VERSION "HNNBNNNYNNNNNNNNNNNNNNNNNNNNNNNNNNNNNNNNNN/4/%%%/4/'%**4NNN///"

NS_ :

BS_ :

BU_:  Airbag BAP_Tester ICAS1_Gateway ICAS1_KommunikationsServer LE1 LE2 Motor_BEV Schaltbetaetigung

BO_ 299 GRA_ACC_01: 8 ICAS1_Gateway
 SG_ GRA_ACC_01_CRC  : 0|8@1+ (1.000000,0.000000) [0.000000|255.000000] "" Motor_BEV
 SG_ GRA_ACC_01_BZ  : 8|4@1+ (1.000000,0.000000) [0.000000|15.000000] "" Motor_BEV
 SG_ GRA_Hauptschalter  : 12|1@1+ (1.000000,0.000000) [0.000000|1.000000] "" Motor_BEV
 SG_ GRA_Abbrechen  : 13|1@1+ (1.000000,0.000000) [0.000000|1.000000] "" Motor_BEV
 SG_ GRA_Typ_Hauptschalter  : 14|1@1+ (1.000000,0.000000) [0.000000|1.000000] "" Motor_BEV
 SG_ GRA_Limiter  : 15|1@1+ (1.000000,0.000000) [0.000000|1.000000] "" Motor_BEV
 SG_ GRA_Tip_Setzen  : 16|1@1+ (1.000000,0.000000) [0.000000|1.000000] "" Motor_BEV
 SG_ GRA_Tip_Hoch  : 17|1@1+ (1.000000,0.000000) [0.000000|1.000000] "" Motor_BEV
 SG_ GRA_Tip_Runter  : 18|1@1+ (1.000000,0.000000) [0.000000|1.000000] "" Motor_BEV
 SG_ GRA_Tip_Wiederaufnahme  : 19|1@1+ (1.000000,0.000000) [0.000000|1.000000] "" Motor_BEV
 SG_ GRA_Verstellung_Zeitluecke  : 20|2@1+ (1.000000,0.000000) [0.000000|3.000000] "" Vector__XXX
 SG_ GRA_Codierung  : 22|2@1+ (1.000000,0.000000) [0.000000|3.000000] "" Motor_BEV
 SG_ GRA_Fehler  : 24|1@1+ (1.000000,0.000000) [0.000000|1.000000] "" Motor_BEV
 SG_ GRA_LIM_Taste_verfuegbar  : 25|1@1+ (1.000000,0.000000) [0.000000|1.000000] "" Motor_BEV
 SG_ GRA_Tip_Stufe_2  : 26|1@1+ (1.000000,0.000000) [0.000000|1.000000] "" Motor_BEV
 SG_ GRA_Typ_Bedienteil  : 27|3@1+ (1.000000,0.000000) [0.000000|7.000000] "" Motor_BEV
 SG_ GRA_TravelAssist  : 30|1@1+ (1.000000,0.000000) [0.000000|1.000000] "" Vector__XXX
 SG_ GRA_reserveByte4  : 31|1@1+ (1.000000,0.000000) [0.000000|1.000000] "" Vector__XXX
 SG_ GRA_reserveByte5  : 32|8@1+ (1.000000,0.000000) [0.000000|255.000000] "" Vector__XXX
 SG_ GRA_reserveByte6  : 40|8@1+ (1.000000,0.000000) [0.000000|255.000000] "" Vector__XXX
 SG_ GRA_reserveByte7  : 48|8@1+ (1.000000,0.000000) [0.000000|255.000000] "" Vector__XXX
 SG_ GRA_reserveByte8  : 56|8@1+ (1.000000,0.000000) [0.000000|255.000000] "" Vector__XXX

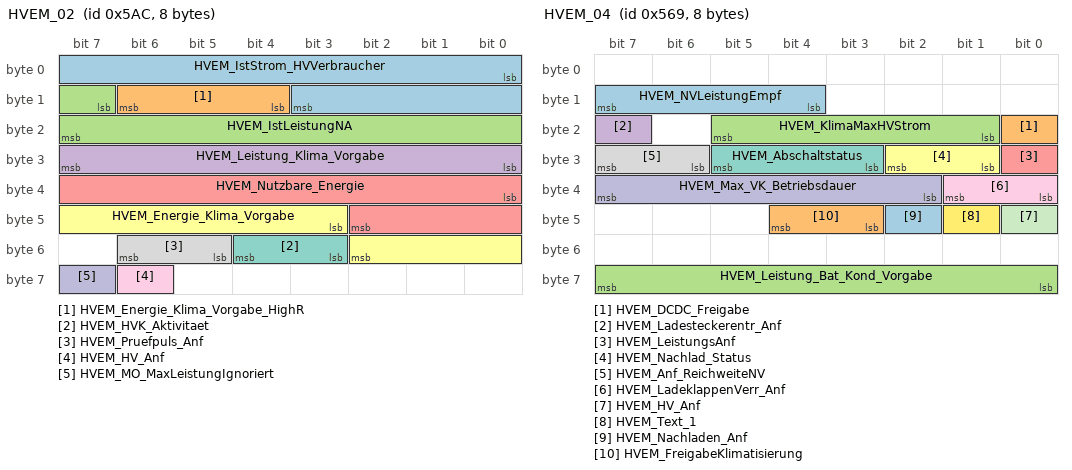
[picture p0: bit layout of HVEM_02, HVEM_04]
BO_ 1452 HVEM_02: 8 ICAS1_Gateway
 SG_ HVEM_IstStrom_HVVerbraucher  : 0|12@1+ (0.100000,-204.700000) [-204.700000|204.600000] "Unit_Amper" Vector__XXX
 SG_ HVEM_Energie_Klima_Vorgabe_HighR  : 12|3@1+ (10.000000,0.000000) [0.000000|50.000000] "Unit_WattHour" Vector__XXX
 SG_ HVEM_IstLeistungNA  : 15|9@1+ (50.000000,0.000000) [0.000000|25450.000000] "Unit_Watt" Motor_BEV
 SG_ HVEM_Leistung_Klima_Vorgabe  : 24|8@1+ (50.000000,0.000000) [0.000000|12650.000000] "Unit_Watt" Vector__XXX
 SG_ HVEM_Nutzbare_Energie  : 32|11@1+ (50.000000,0.000000) [0.000000|102200.000000] "Unit_WattHour" Vector__XXX
 SG_ HVEM_Energie_Klima_Vorgabe  : 43|8@1+ (50.000000,0.000000) [0.000000|12650.000000] "Unit_WattHour" Vector__XXX
 SG_ HVEM_HVK_Aktivitaet  : 51|2@1+ (1.000000,0.000000) [0.000000|3.000000] "" Motor_BEV
 SG_ HVEM_Pruefpuls_Anf  : 53|2@1+ (1.000000,0.000000) [0.000000|3.000000] "" Motor_BEV
 SG_ HVEM_HV_Anf  : 62|1@1+ (1.000000,0.000000) [0.000000|1.000000] "" Motor_BEV
 SG_ HVEM_MO_MaxLeistungIgnoriert  : 63|1@1+ (1.000000,0.000000) [0.000000|1.000000] "" Vector__XXX

BO_ 1385 HVEM_04: 8 ICAS1_Gateway
 SG_ HVEM_NVLeistungEmpf  : 12|4@1+ (100.000000,0.000000) [0.000000|1500.000000] "Unit_Watt" Vector__XXX
 SG_ HVEM_DCDC_Freigabe  : 16|1@1+ (1.000000,0.000000) [0.000000|1.000000] "" Motor_BEV
 SG_ HVEM_KlimaMaxHVStrom  : 17|5@1+ (1.000000,0.000000) [0.000000|31.000000] "Unit_Amper" Vector__XXX
 SG_ HVEM_Ladesteckerentr_Anf  : 23|1@1+ (1.000000,0.000000) [0.000000|1.000000] "" Vector__XXX
 SG_ HVEM_LeistungsAnf  : 24|1@1+ (1.000000,0.000000) [0.000000|1.000000] "" Vector__XXX
 SG_ HVEM_Nachlad_Status  : 25|2@1+ (1.000000,0.000000) [0.000000|3.000000] "" Vector__XXX
 SG_ HVEM_Abschaltstatus  : 27|3@1+ (1.000000,0.000000) [0.000000|7.000000] "" Vector__XXX
 SG_ HVEM_Anf_ReichweiteNV  : 30|2@1+ (1.000000,0.000000) [0.000000|3.000000] "" Vector__XXX
 SG_ HVEM_LadeklappenVerr_Anf  : 32|2@1+ (1.000000,0.000000) [0.000000|3.000000] "" Vector__XXX
 SG_ HVEM_Max_VK_Betriebsdauer  : 34|6@1+ (1.000000,0.000000) [0.000000|60.000000] "Unit_Minut" Vector__XXX
 SG_ HVEM_HV_Anf  : 40|1@1+ (1.000000,0.000000) [0.000000|1.000000] "" Vector__XXX
 SG_ HVEM_Text_1  : 41|1@1+ (1.000000,0.000000) [0.000000|1.000000] "" Vector__XXX
 SG_ HVEM_Nachladen_Anf  : 42|1@1+ (1.000000,0.000000) [0.000000|1.000000] "" Vector__XXX
 SG_ HVEM_FreigabeKlimatisierung  : 43|2@1+ (1.000000,0.000000) [0.000000|3.000000] "" Vector__XXX
 SG_ HVEM_Leistung_Bat_Kond_Vorgabe  : 56|8@1+ (50.000000,0.000000) [0.000000|12650.000000] "Unit_Watt" Vector__XXX

BO_ 1283 HVK_01: 8 Motor_BEV
 SG_ HVK_01_CRC  : 0|8@1+ (1.000000,0.000000) [0.000000|255.000000] "" ICAS1_Gateway LE1 LE2
 SG_ HVK_01_BZ  : 8|4@1+ (1.000000,0.000000) [0.000000|15.000000] "" ICAS1_Gateway LE1 LE2
 SG_ HVK_Istmodus_Anf  : 12|1@1+ (1.000000,0.000000) [0.000000|1.000000] "" ICAS1_Gateway
 SG_ HVK_TN1_Sollmodus  : 13|2@1+ (1.000000,0.000000) [0.000000|3.000000] "" ICAS1_Gateway
 SG_ HVK_Vorladung_aktiv  : 15|1@1+ (1.000000,0.000000) [0.000000|1.000000] "" ICAS1_Gateway
 SG_ HVK_BMS_Sollmodus  : 24|3@1+ (1.000000,0.000000) [0.000000|7.000000] "" ICAS1_Gateway
 SG_ HVK_DCDC_Sollmodus  : 27|3@1+ (1.000000,0.000000) [0.000000|7.000000] "" ICAS1_Gateway
 SG_ HVK_EKK_Sollmodus  : 30|3@1+ (1.000000,0.000000) [0.000000|7.000000] "" ICAS1_Gateway
 SG_ HVK_HVPTC_Sollmodus  : 33|3@1+ (1.000000,0.000000) [0.000000|7.000000] "" ICAS1_Gateway
 SG_ HVK_HVLM_Sollmodus  : 36|3@1+ (1.000000,0.000000) [0.000000|7.000000] "" ICAS1_Gateway
 SG_ HVK_HV_Netz_Warnungen  : 39|2@1+ (1.000000,0.000000) [0.000000|3.000000] "" ICAS1_Gateway ICAS1_KommunikationsServer
 SG_ HV_Bordnetz_aktiv  : 41|1@1+ (1.000000,0.000000) [0.000000|1.000000] "" ICAS1_Gateway LE1 LE2
 SG_ HV_Bordnetz_Fehler  : 42|1@1+ (1.000000,0.000000) [0.000000|1.000000] "" ICAS1_Gateway
 SG_ HVK_Gesamtst_Spgfreiheit  : 43|2@1+ (1.000000,0.000000) [0.000000|3.000000] "" ICAS1_Gateway ICAS1_KommunikationsServer
 SG_ HVK_AktiveEntladung_Anf  : 45|1@1+ (1.000000,0.000000) [0.000000|1.000000] "" ICAS1_Gateway LE1 LE2
 SG_ HVK_HVEM_Freigabe  : 46|2@1+ (1.000000,0.000000) [0.000000|3.000000] "" ICAS1_Gateway
 SG_ HVK_Notentladung_Anf  : 48|2@1+ (1.000000,0.000000) [0.000000|3.000000] "" ICAS1_Gateway LE1 LE2
 SG_ HVK_Iso_Messung_Start  : 50|3@1+ (1.000000,0.000000) [0.000000|7.000000] "" ICAS1_Gateway
 SG_ HVK_Ladebereit  : 53|3@1+ (1.000000,0.000000) [0.000000|7.000000] "" ICAS1_Gateway
 SG_ HVK_PPulsFreigabe  : 56|2@1+ (1.000000,0.000000) [0.000000|3.000000] "" ICAS1_Gateway

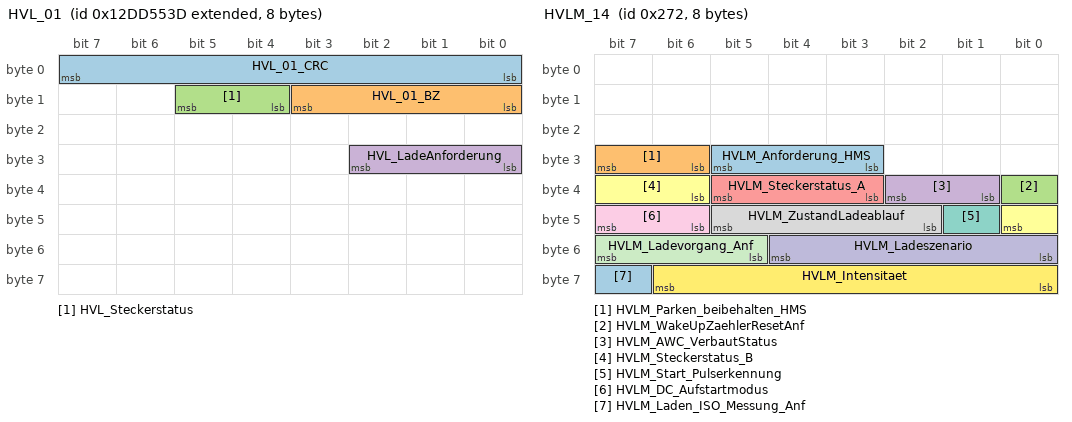
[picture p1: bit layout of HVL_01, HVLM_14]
BO_ 2463978813 HVL_01: 8 ICAS1_Gateway
 SG_ HVL_01_CRC  : 0|8@1+ (1.000000,0.000000) [0.000000|255.000000] "" Motor_BEV
 SG_ HVL_01_BZ  : 8|4@1+ (1.000000,0.000000) [0.000000|15.000000] "" Motor_BEV
 SG_ HVL_Steckerstatus  : 12|2@1+ (1.000000,0.000000) [0.000000|3.000000] "" Motor_BEV
 SG_ HVL_LadeAnforderung  : 24|3@1+ (1.000000,0.000000) [0.000000|7.000000] "" Motor_BEV

BO_ 626 HVLM_14: 8 ICAS1_Gateway
 SG_ HVLM_Anforderung_HMS  : 27|3@1+ (1.000000,0.000000) [0.000000|7.000000] "" Vector__XXX
 SG_ HVLM_Parken_beibehalten_HMS  : 30|2@1+ (1.000000,0.000000) [0.000000|3.000000] "" Vector__XXX
 SG_ HVLM_WakeUpZaehlerResetAnf  : 32|1@1+ (1.000000,0.000000) [0.000000|1.000000] "" Vector__XXX
 SG_ HVLM_AWC_VerbautStatus  : 33|2@1+ (1.000000,0.000000) [0.000000|3.000000] "" Motor_BEV
 SG_ HVLM_Steckerstatus_A  : 35|3@1+ (1.000000,0.000000) [0.000000|7.000000] "" Motor_BEV
 SG_ HVLM_Steckerstatus_B  : 38|3@1+ (1.000000,0.000000) [0.000000|7.000000] "" Vector__XXX
 SG_ HVLM_Start_Pulserkennung  : 41|1@1+ (1.000000,0.000000) [0.000000|1.000000] "" Vector__XXX
 SG_ HVLM_ZustandLadeablauf  : 42|4@1+ (1.000000,0.000000) [0.000000|15.000000] "" Motor_BEV
 SG_ HVLM_DC_Aufstartmodus  : 46|2@1+ (1.000000,0.000000) [0.000000|3.000000] "" Motor_BEV
 SG_ HVLM_Ladeszenario  : 48|5@1+ (1.000000,0.000000) [0.000000|31.000000] "" Vector__XXX
 SG_ HVLM_Ladevorgang_Anf  : 53|3@1+ (1.000000,0.000000) [0.000000|7.000000] "" Motor_BEV
 SG_ HVLM_Intensitaet  : 56|7@1+ (1.000000,0.000000) [0.000000|100.000000] "Unit_PerCent" Vector__XXX
 SG_ HVLM_Laden_ISO_Messung_Anf  : 63|1@1+ (1.000000,0.000000) [0.000000|1.000000] "" Motor_BEV

BO_ 268 IMMO_CORD_01: 8 Motor_BEV
 SG_ ImoCord_Auth_Aufforderung_WFS  : 63|1@1+ (1.000000,0.000000) [0.000000|1.000000] "" LE1 LE2

BO_ 23 IMMO_MSG3_Antwort: 8 ICAS1_Gateway
 SG_ WFS_IMMO_MSG3_CRC  : 0|32@1+ (1.000000,0.000000) [0.000000|4294967295.000000] "" LE2
 SG_ WFS_IMMO_MSG3_Status  : 56|8@1+ (1.000000,0.000000) [0.000000|255.000000] "" LE2

BO_ 25 IMMO_MSG4_Antwort: 8 ICAS1_Gateway
 SG_ WFS_IMMO_MSG4_CRC  : 0|32@1+ (1.000000,0.000000) [0.000000|4294967295.000000] "" LE1
 SG_ WFS_IMMO_MSG4_Status  : 56|8@1+ (1.000000,0.000000) [0.000000|255.000000] "" LE1

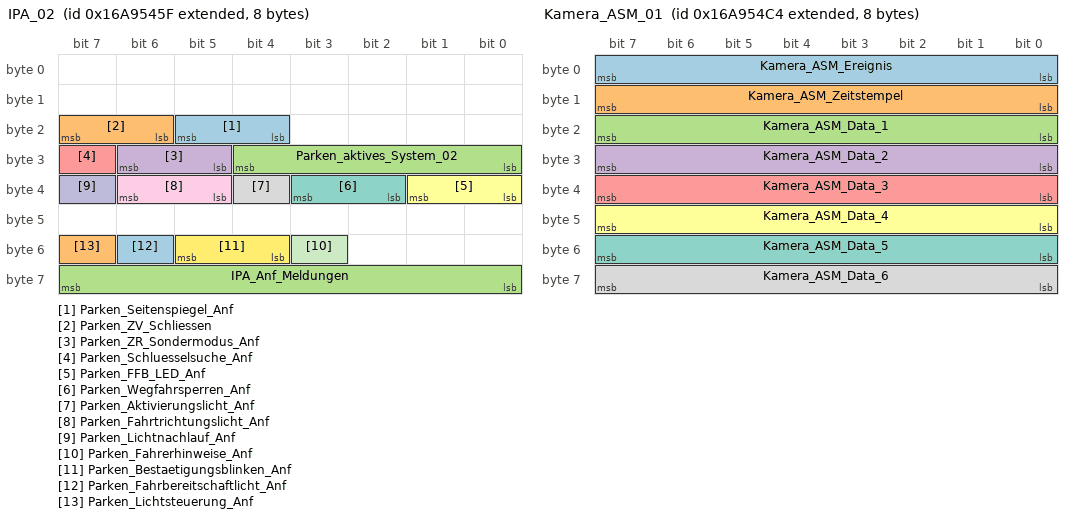
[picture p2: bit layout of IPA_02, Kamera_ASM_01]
BO_ 2527679583 IPA_02: 8 ICAS1_Gateway
 SG_ Parken_Seitenspiegel_Anf  : 20|2@1+ (1.000000,0.000000) [0.000000|3.000000] "" Vector__XXX
 SG_ Parken_ZV_Schliessen  : 22|2@1+ (1.000000,0.000000) [0.000000|3.000000] "" Vector__XXX
 SG_ Parken_aktives_System_02  : 24|5@1+ (1.000000,0.000000) [0.000000|31.000000] "" Vector__XXX
 SG_ Parken_ZR_Sondermodus_Anf  : 29|2@1+ (1.000000,0.000000) [0.000000|3.000000] "" Vector__XXX
 SG_ Parken_Schluesselsuche_Anf  : 31|1@1+ (1.000000,0.000000) [0.000000|1.000000] "" Vector__XXX
 SG_ Parken_FFB_LED_Anf  : 32|2@1+ (1.000000,0.000000) [0.000000|3.000000] "" Vector__XXX
 SG_ Parken_Wegfahrsperren_Anf  : 34|2@1+ (1.000000,0.000000) [0.000000|3.000000] "" LE1 LE2
 SG_ Parken_Aktivierungslicht_Anf  : 36|1@1+ (1.000000,0.000000) [0.000000|1.000000] "" Vector__XXX
 SG_ Parken_Fahrtrichtungslicht_Anf  : 37|2@1+ (1.000000,0.000000) [0.000000|3.000000] "" Vector__XXX
 SG_ Parken_Lichtnachlauf_Anf  : 39|1@1+ (1.000000,0.000000) [0.000000|1.000000] "" Vector__XXX
 SG_ Parken_Fahrerhinweise_Anf  : 51|1@1+ (1.000000,0.000000) [0.000000|1.000000] "" Vector__XXX
 SG_ Parken_Bestaetigungsblinken_Anf  : 52|2@1+ (1.000000,0.000000) [0.000000|3.000000] "" Vector__XXX
 SG_ Parken_Fahrbereitschaftlicht_Anf  : 54|1@1+ (1.000000,0.000000) [0.000000|1.000000] "" Vector__XXX
 SG_ Parken_Lichtsteuerung_Anf  : 55|1@1+ (1.000000,0.000000) [0.000000|1.000000] "" Vector__XXX
 SG_ IPA_Anf_Meldungen  : 56|8@1+ (1.000000,0.000000) [0.000000|255.000000] "" Vector__XXX

BO_ 1813 ISO_Airbag_01_Req: 8 ICAS1_Gateway
 SG_ ISO_Airbag_01_Req_Data  : 0|64@1+ (1.000000,0.000000) [0.000000|18446744073709551616.000000] "" Airbag

BO_ 1919 ISO_Airbag_01_Resp: 8 Airbag
 SG_ ISO_Airbag_01_Resp_Data  : 0|64@1+ (1.000000,0.000000) [0.000000|18446744073709551616.000000] "" ICAS1_Gateway

BO_ 1792 ISO_Funktionaler_Req_All: 8 ICAS1_Gateway
 SG_ ISO_ALL_01_Req_Data  : 0|64@1+ (1.000000,0.000000) [0.000000|18446744073709551616.000000] "" Airbag LE1 LE2 Motor_BEV

BO_ 2621440021 ISOx_Airbag_01_Req_FD: 64 ICAS1_Gateway
 SG_ ISOx_Airbag_01_Req_FD_Data  : 0|512@1+ (1.000000,0.000000) [0.000000|13407807929942597099574024998205846127479365820592393377723561443721764030073546976801874298166903427690031858186486050853753882811946569946433649006084096.000000] "" Airbag

BO_ 2621571093 ISOx_Airbag_01_Resp_FD: 64 Airbag
 SG_ ISOx_Airbag_01_Resp_FD_Data  : 0|512@1+ (1.000000,0.000000) [0.000000|13407807929942597099574024998205846127479365820592393377723561443721764030073546976801874298166903427690031858186486050853753882811946569946433649006084096.000000] "" ICAS1_Gateway

BO_ 2549874812 ISOx_EMotor_01_Req: 8 ICAS1_Gateway
 SG_ ISO_EMotor_01_Req_Data  : 0|64@1+ (1.000000,0.000000) [0.000000|18446744073709551616.000000] "" LE1

BO_ 2621440124 ISOx_EMotor_01_Req_FD: 64 ICAS1_Gateway
 SG_ ISOx_EMotor_01_Req_FD_Data  : 0|512@1+ (1.000000,0.000000) [0.000000|13407807929942597099574024998205846127479365820592393377723561443721764030073546976801874298166903427690031858186486050853753882811946569946433649006084096.000000] "" LE1

BO_ 2550005884 ISOx_EMotor_01_Resp: 8 LE1
 SG_ ISO_EMotor_01_Resp_Data  : 0|64@1+ (1.000000,0.000000) [0.000000|18446744073709551616.000000] "" ICAS1_Gateway

BO_ 2621571196 ISOx_EMotor_01_Resp_FD: 64 LE1
 SG_ ISOx_EMotor_01_Resp_FD_Data  : 0|512@1+ (1.000000,0.000000) [0.000000|13407807929942597099574024998205846127479365820592393377723561443721764030073546976801874298166903427690031858186486050853753882811946569946433649006084096.000000] "" ICAS1_Gateway

BO_ 2549874872 ISOx_EMotor_02_Req: 8 ICAS1_Gateway
 SG_ ISO_EMotor_02_Req_Data  : 0|64@1+ (1.000000,0.000000) [0.000000|18446744073709551616.000000] "" LE2

BO_ 2621440184 ISOx_EMotor_02_Req_FD: 64 ICAS1_Gateway
 SG_ ISOx_EMotor_02_Req_FD_Data  : 0|512@1+ (1.000000,0.000000) [0.000000|13407807929942597099574024998205846127479365820592393377723561443721764030073546976801874298166903427690031858186486050853753882811946569946433649006084096.000000] "" LE2

BO_ 2550005944 ISOx_EMotor_02_Resp: 8 LE2
 SG_ ISO_EMotor_02_Resp_Data  : 0|64@1+ (1.000000,0.000000) [0.000000|18446744073709551616.000000] "" ICAS1_Gateway

BO_ 2621571256 ISOx_EMotor_02_Resp_FD: 64 LE2
 SG_ ISOx_EMotor_02_Resp_FD_Data  : 0|512@1+ (1.000000,0.000000) [0.000000|13407807929942597099574024998205846127479365820592393377723561443721764030073546976801874298166903427690031858186486050853753882811946569946433649006084096.000000] "" ICAS1_Gateway

BO_ 2621505536 ISOx_Funkt_Req_All_FD: 64 ICAS1_Gateway
 SG_ ISOx_Funkt_Req_All_FD_Data  : 0|512@1+ (1.000000,0.000000) [0.000000|13407807929942597099574024998205846127479365820592393377723561443721764030073546976801874298166903427690031858186486050853753882811946569946433649006084096.000000] "" Airbag LE1 LE2 Motor_BEV

BO_ 2549874806 ISOx_MO_01_Req: 8 ICAS1_Gateway
 SG_ ISOx_MO_01_Req_Data  : 0|64@1+ (1.000000,0.000000) [0.000000|18446744073709551616.000000] "" Motor_BEV

BO_ 2621440118 ISOx_MO_01_Req_FD: 64 ICAS1_Gateway
 SG_ ISOx_MO_01_Req_FD_Data  : 0|512@1+ (1.000000,0.000000) [0.000000|13407807929942597099574024998205846127479365820592393377723561443721764030073546976801874298166903427690031858186486050853753882811946569946433649006084096.000000] "" Motor_BEV

BO_ 2550005878 ISOx_MO_01_Resp: 8 Motor_BEV
 SG_ ISOx_MO_01_Resp_Data  : 0|64@1+ (1.000000,0.000000) [0.000000|18446744073709551616.000000] "" ICAS1_Gateway

BO_ 2621571190 ISOx_MO_01_Resp_FD: 64 Motor_BEV
 SG_ ISOx_MO_01_Resp_FD_Data  : 0|512@1+ (1.000000,0.000000) [0.000000|13407807929942597099574024998205846127479365820592393377723561443721764030073546976801874298166903427690031858186486050853753882811946569946433649006084096.000000] "" ICAS1_Gateway

BO_ 2527679684 Kamera_ASM_01: 8 ICAS1_Gateway
 SG_ Kamera_ASM_Ereignis  : 0|8@1+ (1.000000,0.000000) [1.000000|254.000000] "" Airbag
 SG_ Kamera_ASM_Zeitstempel  : 8|8@1+ (0.080000,0.000000) [0.000000|20.320000] "Unit_Secon" Airbag
 SG_ Kamera_ASM_Data_1  : 16|8@1+ (1.000000,0.000000) [0.000000|255.000000] "" Airbag
 SG_ Kamera_ASM_Data_2  : 24|8@1+ (1.000000,0.000000) [0.000000|255.000000] "" Airbag
 SG_ Kamera_ASM_Data_3  : 32|8@1+ (1.000000,0.000000) [0.000000|255.000000] "" Airbag
 SG_ Kamera_ASM_Data_4  : 40|8@1+ (1.000000,0.000000) [0.000000|255.000000] "" Airbag
 SG_ Kamera_ASM_Data_5  : 48|8@1+ (1.000000,0.000000) [0.000000|255.000000] "" Airbag
 SG_ Kamera_ASM_Data_6  : 56|8@1+ (1.000000,0.000000) [0.000000|255.000000] "" Airbag

BO_ 960 Klemmen_Status_01: 4 ICAS1_Gateway
 SG_ Klemmen_Status_01_CRC  : 0|8@1+ (1.000000,0.000000) [0.000000|255.000000] "" Motor_BEV
 SG_ Klemmen_Status_01_BZ  : 8|4@1+ (1.000000,0.000000) [0.000000|15.000000] "" Motor_BEV
 SG_ RSt_Fahrerhinweise  : 12|4@1+ (1.000000,0.000000) [0.000000|15.000000] "" Vector__XXX
 SG_ ZAS_Kl_S  : 16|1@1+ (1.000000,0.000000) [0.000000|1.000000] "" Vector__XXX
 SG_ ZAS_Kl_15  : 17|1@1+ (1.000000,0.000000) [0.000000|1.000000] "" Airbag LE1 LE2 Motor_BEV Schaltbetaetigung
 SG_ ZAS_Kl_X  : 18|1@1+ (1.000000,0.000000) [0.000000|1.000000] "" Vector__XXX
 SG_ ZAS_Kl_50_Startanforderung  : 19|1@1+ (1.000000,0.000000) [0.000000|1.000000] "" Motor_BEV
 SG_ BCM_Remotestart_Betrieb  : 20|1@1+ (1.000000,0.000000) [0.000000|1.000000] "" Vector__XXX
 SG_ ZAS_Kl_Infotainment  : 21|1@1+ (1.000000,0.000000) [0.000000|1.000000] "" Vector__XXX
 SG_ BCM_Remotestart_KL15_Anf  : 22|1@1+ (1.000000,0.000000) [0.000000|1.000000] "" Vector__XXX
 SG_ BCM_Remotestart_MO_Start  : 23|1@1+ (1.000000,0.000000) [0.000000|1.000000] "" Vector__XXX
 SG_ KST_Warn_P1_ZST_def  : 24|1@1+ (1.000000,0.000000) [0.000000|1.000000] "" Vector__XXX
 SG_ KST_Warn_P2_ZST_def  : 25|1@1+ (1.000000,0.000000) [0.000000|1.000000] "" Vector__XXX
 SG_ KST_Fahrerhinweis_1  : 26|1@1+ (1.000000,0.000000) [0.000000|1.000000] "" Vector__XXX
 SG_ KST_Fahrerhinweis_2  : 27|1@1+ (1.000000,0.000000) [0.000000|1.000000] "" Vector__XXX
 SG_ BCM_Ausparken_Betrieb  : 28|1@1+ (1.000000,0.000000) [0.000000|1.000000] "" Vector__XXX
 SG_ KST_Fahrerhinweis_4  : 29|1@1+ (1.000000,0.000000) [0.000000|1.000000] "" Vector__XXX
 SG_ KST_Fahrerhinweis_5  : 30|1@1+ (1.000000,0.000000) [0.000000|1.000000] "" Vector__XXX
 SG_ KST_Fahrerhinweis_6  : 31|1@1+ (1.000000,0.000000) [0.000000|1.000000] "" Vector__XXX

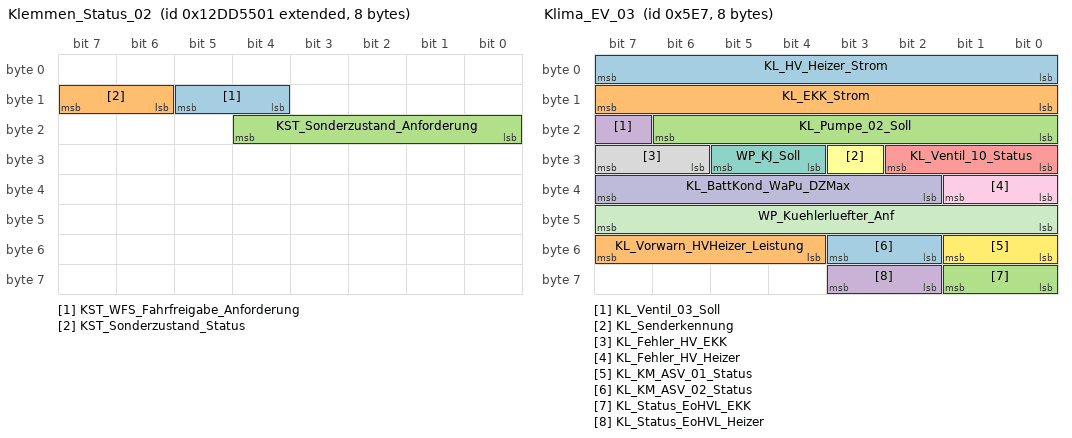
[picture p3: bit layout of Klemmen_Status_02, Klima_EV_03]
BO_ 2463978753 Klemmen_Status_02: 8 ICAS1_Gateway
 SG_ KST_WFS_Fahrfreigabe_Anforderung  : 12|2@1+ (1.000000,0.000000) [0.000000|3.000000] "" LE1 LE2
 SG_ KST_Sonderzustand_Status  : 14|2@1+ (1.000000,0.000000) [0.000000|3.000000] "" LE1 LE2
 SG_ KST_Sonderzustand_Anforderung  : 16|5@1+ (1.000000,0.000000) [0.000000|31.000000] "" LE1 LE2

BO_ 1420 Klemmen_Steuerung_01: 8 ICAS1_Gateway
 SG_ Klemmen_Steuerung_01_CRC  : 0|8@1+ (1.000000,0.000000) [0.000000|255.000000] "" Vector__XXX
 SG_ Klemmen_Steuerung_01_BZ  : 8|4@1+ (1.000000,0.000000) [0.000000|15.000000] "" Vector__XXX
 SG_ KST_Anf_Klemme_15  : 12|1@1+ (1.000000,0.000000) [0.000000|1.000000] "" Vector__XXX
 SG_ KST_Anf_Klemme_50  : 13|1@1+ (1.000000,0.000000) [0.000000|1.000000] "" Motor_BEV
 SG_ KST_Anf_Klemme_S  : 14|1@1+ (1.000000,0.000000) [0.000000|1.000000] "" Vector__XXX
 SG_ KST_Txt_Werkstatt  : 15|1@1+ (1.000000,0.000000) [0.000000|1.000000] "" Vector__XXX
 SG_ KST_Txt_P_Gang  : 16|1@1+ (1.000000,0.000000) [0.000000|1.000000] "" Vector__XXX
 SG_ KST_Txt_Panikabschaltung  : 17|1@1+ (1.000000,0.000000) [0.000000|1.000000] "" Vector__XXX
 SG_ KST_Anf_Klemmenfreigabe_ELV  : 18|1@1+ (1.000000,0.000000) [0.000000|1.000000] "" Vector__XXX
 SG_ KST_Txt_Komfortabschaltung  : 19|1@1+ (1.000000,0.000000) [0.000000|1.000000] "" Vector__XXX
 SG_ KST_ZAT_betaetigt  : 20|1@1+ (1.000000,0.000000) [0.000000|1.000000] "" Vector__XXX
 SG_ KST_Unterdr_Zuendungsmeldung  : 21|1@1+ (1.000000,0.000000) [0.000000|1.000000] "" Vector__XXX
 SG_ KST_aut_Abschaltung_Zuendung  : 22|1@1+ (1.000000,0.000000) [0.000000|1.000000] "" Vector__XXX
 SG_ KST_Anf_Klemmenfreigabe_WFS  : 23|1@1+ (1.000000,0.000000) [0.000000|1.000000] "" Vector__XXX
 SG_ KST_Anf_ZV_Verriegelung  : 24|1@1+ (1.000000,0.000000) [0.000000|1.000000] "" Vector__XXX
 SG_ Relais_VoKo_angesteuert  : 25|1@1+ (1.000000,0.000000) [0.000000|1.000000] "" Vector__XXX
 SG_ RSt_Anforderung_HMS  : 26|3@1+ (1.000000,0.000000) [0.000000|7.000000] "" Vector__XXX
 SG_ KST_Zuendungswarnung  : 29|2@1+ (1.000000,0.000000) [0.000000|3.000000] "" Vector__XXX
 SG_ KST_Fahrer_Info_Text  : 31|3@1+ (1.000000,0.000000) [0.000000|7.000000] "" Vector__XXX

BO_ 949 Klima_11: 8 ICAS1_Gateway
 SG_ KL_Drehz_Anh  : 0|1@1+ (1.000000,0.000000) [0.000000|1.000000] "" Vector__XXX
 SG_ KL_Vorwarn_Komp_ein  : 1|1@1+ (1.000000,0.000000) [0.000000|1.000000] "" Vector__XXX
 SG_ KL_AC_Schalter  : 2|1@1+ (1.000000,0.000000) [0.000000|1.000000] "" Vector__XXX
 SG_ KL_Komp_Moment_alt  : 3|1@1+ (1.000000,0.000000) [0.000000|1.000000] "" Vector__XXX
 SG_ KL_Vorwarn_Zuheizer_ein  : 6|1@1+ (1.000000,0.000000) [0.000000|1.000000] "" Vector__XXX
 SG_ KL_Zustand  : 7|1@1+ (1.000000,0.000000) [0.000000|1.000000] "" Vector__XXX
 SG_ KL_Kompressorkupplung_linear  : 8|8@1+ (20.000000,0.000000) [0.000000|4000.000000] "Unit_MilliAmper" Vector__XXX
 SG_ KL_Charisma_FahrPr  : 16|4@1+ (1.000000,0.000000) [0.000000|15.000000] "" Vector__XXX
 SG_ KL_Charisma_Status  : 20|2@1+ (1.000000,0.000000) [0.000000|3.000000] "" Vector__XXX
 SG_ KL_nachtr_Stopp_Anf  : 22|1@1+ (1.000000,0.000000) [0.000000|1.000000] "" Vector__XXX
 SG_ KL_T_Charge  : 23|1@1+ (1.000000,0.000000) [0.000000|1.000000] "" Vector__XXX
 SG_ KL_Last_Kompr  : 24|8@1+ (0.250000,0.000000) [0.000000|63.500000] "Unit_NewtoMeter" Vector__XXX
 SG_ KL_Spannungs_Anf  : 32|2@1+ (1.000000,0.000000) [0.000000|3.000000] "" Vector__XXX
 SG_ KL_Thermomanagement  : 34|2@1+ (1.000000,0.000000) [0.000000|3.000000] "" Motor_BEV
 SG_ KL_StartStopp_Info  : 36|2@1+ (1.000000,0.000000) [0.000000|3.000000] "" Vector__XXX
 SG_ KL_Freilauf_Info  : 38|2@1+ (1.000000,0.000000) [0.000000|3.000000] "" Vector__XXX
 SG_ KL_Anf_KL  : 40|8@1+ (0.400000,0.000000) [0.000000|101.600000] "Unit_PerCent" Motor_BEV
 SG_ KL_el_Zuheizer_Stufe  : 48|3@1+ (1.000000,0.000000) [0.000000|7.000000] "" Vector__XXX
 SG_ KL_Ausstattung_Klima  : 51|3@1+ (1.000000,0.000000) [0.000000|7.000000] "" Vector__XXX
 SG_ KL_Variante_Standheizung  : 54|2@1+ (1.000000,0.000000) [0.000000|3.000000] "" Vector__XXX
 SG_ KL_Anf_KV  : 57|7@1+ (1.000000,0.000000) [0.000000|100.000000] "Unit_PerCent" Motor_BEV

BO_ 1511 Klima_EV_03: 8 ICAS1_Gateway
 SG_ KL_HV_Heizer_Strom  : 0|8@1+ (0.250000,0.000000) [0.000000|63.500000] "Unit_Amper" Motor_BEV
 SG_ KL_EKK_Strom  : 8|8@1+ (0.250000,0.000000) [0.000000|63.500000] "Unit_Amper" Motor_BEV
 SG_ KL_Pumpe_02_Soll  : 16|7@1+ (1.000000,0.000000) [0.000000|100.000000] "Unit_PerCent" Motor_BEV
 SG_ KL_Ventil_03_Soll  : 23|1@1+ (1.000000,0.000000) [0.000000|1.000000] "" Vector__XXX
 SG_ KL_Ventil_10_Status  : 24|3@1+ (1.000000,0.000000) [0.000000|7.000000] "" Vector__XXX
 SG_ KL_Senderkennung  : 27|1@1+ (1.000000,0.000000) [0.000000|1.000000] "" Vector__XXX
 SG_ WP_KJ_Soll  : 28|2@1+ (1.000000,0.000000) [0.000000|3.000000] "" Vector__XXX
 SG_ KL_Fehler_HV_EKK  : 30|2@1+ (1.000000,0.000000) [0.000000|3.000000] "" Vector__XXX
 SG_ KL_Fehler_HV_Heizer  : 32|2@1+ (1.000000,0.000000) [0.000000|3.000000] "" Vector__XXX
 SG_ KL_BattKond_WaPu_DZMax  : 34|6@1+ (2.000000,0.000000) [0.000000|100.000000] "Unit_PerCent" Vector__XXX
 SG_ WP_Kuehlerluefter_Anf  : 40|8@1+ (0.400000,0.000000) [0.000000|101.600000] "Unit_PerCent" Vector__XXX
 SG_ KL_KM_ASV_01_Status  : 48|2@1+ (1.000000,0.000000) [0.000000|3.000000] "" Vector__XXX
 SG_ KL_KM_ASV_02_Status  : 50|2@1+ (1.000000,0.000000) [0.000000|3.000000] "" Vector__XXX
 SG_ KL_Vorwarn_HVHeizer_Leistung  : 52|4@1+ (1.000000,0.000000) [0.000000|15.000000] "" Vector__XXX
 SG_ KL_Status_EoHVL_EKK  : 56|2@1+ (1.000000,0.000000) [0.000000|3.000000] "" Motor_BEV
 SG_ KL_Status_EoHVL_Heizer  : 58|2@1+ (1.000000,0.000000) [0.000000|3.000000] "" Motor_BEV

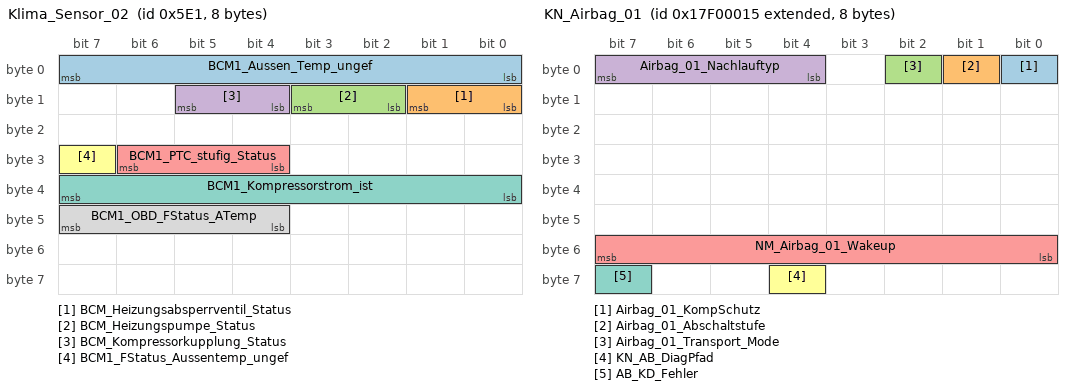
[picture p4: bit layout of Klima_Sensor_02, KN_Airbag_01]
BO_ 1505 Klima_Sensor_02: 8 ICAS1_Gateway
 SG_ BCM1_Aussen_Temp_ungef  : 0|8@1+ (0.500000,-50.000000) [-50.000000|76.000000] "Unit_DegreCelsi" LE1 LE2 Motor_BEV
 SG_ BCM_Heizungsabsperrventil_Status  : 8|2@1+ (1.000000,0.000000) [0.000000|3.000000] "" Vector__XXX
 SG_ BCM_Heizungspumpe_Status  : 10|2@1+ (1.000000,0.000000) [0.000000|3.000000] "" Vector__XXX
 SG_ BCM_Kompressorkupplung_Status  : 12|2@1+ (1.000000,0.000000) [0.000000|3.000000] "" Vector__XXX
 SG_ BCM1_PTC_stufig_Status  : 28|3@1+ (1.000000,0.000000) [0.000000|7.000000] "" Vector__XXX
 SG_ BCM1_FStatus_Aussentemp_ungef  : 31|1@1+ (1.000000,0.000000) [0.000000|1.000000] "" Vector__XXX
 SG_ BCM1_Kompressorstrom_ist  : 32|8@1+ (4.000000,0.000000) [0.000000|1000.000000] "Unit_MilliAmper" Vector__XXX
 SG_ BCM1_OBD_FStatus_ATemp  : 44|4@1+ (1.000000,0.000000) [0.000000|15.000000] "" Vector__XXX

BO_ 2549088277 KN_Airbag_01: 8 Airbag
 SG_ Airbag_01_KompSchutz  : 0|1@1+ (1.000000,0.000000) [0.000000|1.000000] "" Vector__XXX
 SG_ Airbag_01_Abschaltstufe  : 1|1@1+ (1.000000,0.000000) [0.000000|1.000000] "" Vector__XXX
 SG_ Airbag_01_Transport_Mode  : 2|1@1+ (1.000000,0.000000) [0.000000|1.000000] "" Vector__XXX
 SG_ Airbag_01_Nachlauftyp  : 4|4@1+ (1.000000,0.000000) [0.000000|15.000000] "" ICAS1_Gateway
 SG_ NM_Airbag_01_Wakeup  : 48|8@1+ (1.000000,0.000000) [0.000000|255.000000] "" Vector__XXX
 SG_ KN_AB_DiagPfad  : 60|1@1+ (1.000000,0.000000) [0.000000|1.000000] "" ICAS1_Gateway
 SG_ AB_KD_Fehler  : 63|1@1+ (1.000000,0.000000) [0.000000|1.000000] "" ICAS1_Gateway

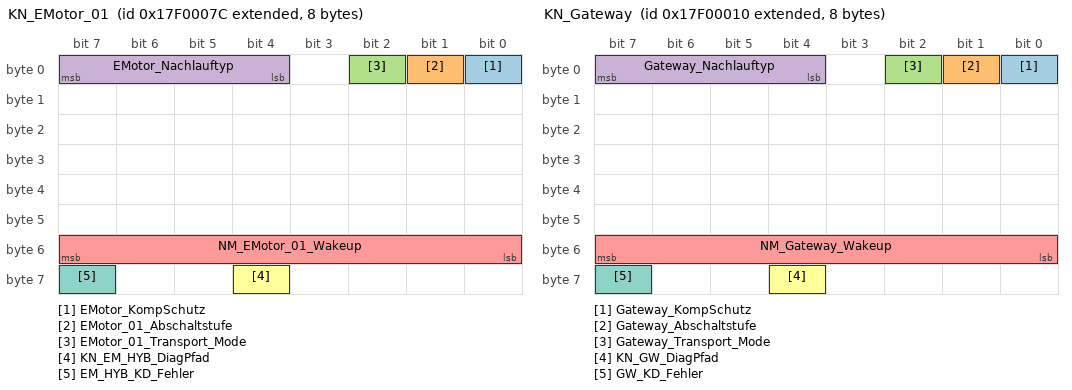
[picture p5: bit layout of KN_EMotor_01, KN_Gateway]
BO_ 2549088380 KN_EMotor_01: 8 LE1
 SG_ EMotor_KompSchutz  : 0|1@1+ (1.000000,0.000000) [0.000000|1.000000] "" Vector__XXX
 SG_ EMotor_01_Abschaltstufe  : 1|1@1+ (1.000000,0.000000) [0.000000|1.000000] "" Vector__XXX
 SG_ EMotor_01_Transport_Mode  : 2|1@1+ (1.000000,0.000000) [0.000000|1.000000] "" Vector__XXX
 SG_ EMotor_Nachlauftyp  : 4|4@1+ (1.000000,0.000000) [0.000000|15.000000] "" ICAS1_Gateway
 SG_ NM_EMotor_01_Wakeup  : 48|8@1+ (1.000000,0.000000) [0.000000|255.000000] "" Vector__XXX
 SG_ KN_EM_HYB_DiagPfad  : 60|1@1+ (1.000000,0.000000) [0.000000|1.000000] "" ICAS1_Gateway
 SG_ EM_HYB_KD_Fehler  : 63|1@1+ (1.000000,0.000000) [0.000000|1.000000] "" ICAS1_Gateway

BO_ 2549088272 KN_Gateway: 8 ICAS1_Gateway
 SG_ Gateway_KompSchutz  : 0|1@1+ (1.000000,0.000000) [0.000000|1.000000] "" Vector__XXX
 SG_ Gateway_Abschaltstufe  : 1|1@1+ (1.000000,0.000000) [0.000000|1.000000] "" Vector__XXX
 SG_ Gateway_Transport_Mode  : 2|1@1+ (1.000000,0.000000) [0.000000|1.000000] "" Vector__XXX
 SG_ Gateway_Nachlauftyp  : 4|4@1+ (1.000000,0.000000) [0.000000|15.000000] "" Vector__XXX
 SG_ NM_Gateway_Wakeup  : 48|8@1+ (1.000000,0.000000) [0.000000|255.000000] "" Vector__XXX
 SG_ KN_GW_DiagPfad  : 60|1@1+ (1.000000,0.000000) [0.000000|1.000000] "" Vector__XXX
 SG_ GW_KD_Fehler  : 63|1@1+ (1.000000,0.000000) [0.000000|1.000000] "" Vector__XXX

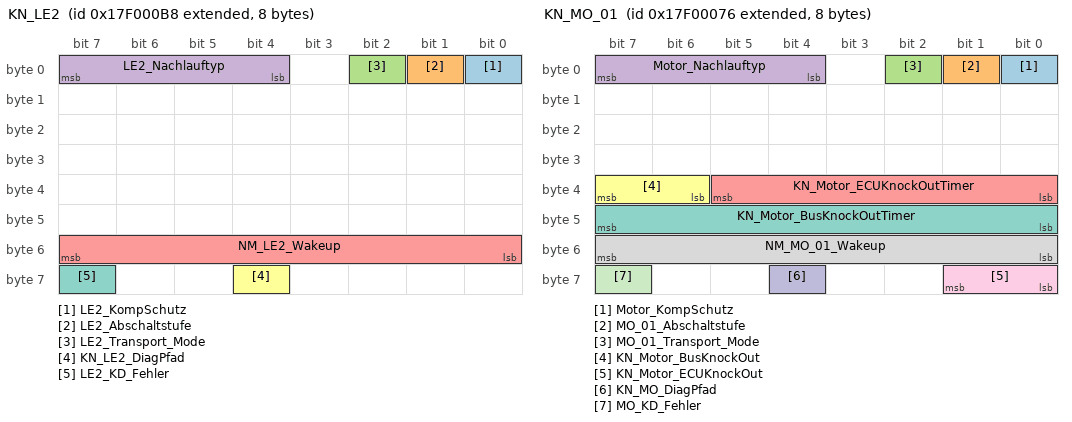
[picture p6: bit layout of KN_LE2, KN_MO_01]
BO_ 2549088440 KN_LE2: 8 LE2
 SG_ LE2_KompSchutz  : 0|1@1+ (1.000000,0.000000) [0.000000|1.000000] "" Vector__XXX
 SG_ LE2_Abschaltstufe  : 1|1@1+ (1.000000,0.000000) [0.000000|1.000000] "" Vector__XXX
 SG_ LE2_Transport_Mode  : 2|1@1+ (1.000000,0.000000) [0.000000|1.000000] "" Vector__XXX
 SG_ LE2_Nachlauftyp  : 4|4@1+ (1.000000,0.000000) [0.000000|15.000000] "" ICAS1_Gateway
 SG_ NM_LE2_Wakeup  : 48|8@1+ (1.000000,0.000000) [0.000000|255.000000] "" Vector__XXX
 SG_ KN_LE2_DiagPfad  : 60|1@1+ (1.000000,0.000000) [0.000000|1.000000] "" ICAS1_Gateway
 SG_ LE2_KD_Fehler  : 63|1@1+ (1.000000,0.000000) [0.000000|1.000000] "" ICAS1_Gateway

BO_ 2549088374 KN_MO_01: 8 Motor_BEV
 SG_ Motor_KompSchutz  : 0|1@1+ (1.000000,0.000000) [0.000000|1.000000] "" Vector__XXX
 SG_ MO_01_Abschaltstufe  : 1|1@1+ (1.000000,0.000000) [0.000000|1.000000] "" Vector__XXX
 SG_ MO_01_Transport_Mode  : 2|1@1+ (1.000000,0.000000) [0.000000|1.000000] "" Vector__XXX
 SG_ Motor_Nachlauftyp  : 4|4@1+ (1.000000,0.000000) [0.000000|15.000000] "" ICAS1_Gateway
 SG_ KN_Motor_ECUKnockOutTimer  : 32|6@1+ (1.000000,0.000000) [0.000000|62.000000] "Unit_Minut" Vector__XXX
 SG_ KN_Motor_BusKnockOut  : 38|2@1+ (1.000000,0.000000) [0.000000|3.000000] "" Vector__XXX
 SG_ KN_Motor_BusKnockOutTimer  : 40|8@1+ (1.000000,0.000000) [0.000000|254.000000] "" Vector__XXX
 SG_ NM_MO_01_Wakeup  : 48|8@1+ (1.000000,0.000000) [0.000000|255.000000] "" Vector__XXX
 SG_ KN_Motor_ECUKnockOut  : 56|2@1+ (1.000000,0.000000) [0.000000|3.000000] "" Vector__XXX
 SG_ KN_MO_DiagPfad  : 60|1@1+ (1.000000,0.000000) [0.000000|1.000000] "" ICAS1_Gateway
 SG_ MO_KD_Fehler  : 63|1@1+ (1.000000,0.000000) [0.000000|1.000000] "" ICAS1_Gateway

BO_ 2621440277 KS_Airbag_01_Req_FD: 16 ICAS1_Gateway
 SG_ KS_Airbag_01_Req_FD_Data  : 0|128@1+ (1.000000,0.000000) [0.000000|340282366920938463463374607431768211456.000000] "" Airbag

BO_ 2621571349 KS_Airbag_01_Resp_FD: 16 Airbag
 SG_ KS_Airbag_01_Resp_FD_Data  : 0|128@1+ (1.000000,0.000000) [0.000000|340282366920938463463374607431768211456.000000] "" ICAS1_Gateway

BO_ 982 Licht_hinten_01: 8 ICAS1_Gateway
 SG_ Licht_hinten_01_BZ  : 0|4@1+ (1.000000,0.000000) [0.000000|15.000000] "" Vector__XXX
 SG_ LH_Aussenlicht_def  : 7|1@1+ (1.000000,0.000000) [0.000000|1.000000] "" Vector__XXX
 SG_ LH_Standlicht_H_aktiv  : 8|1@1+ (1.000000,0.000000) [0.000000|1.000000] "" Vector__XXX
 SG_ LH_Parklicht_HL_aktiv  : 9|1@1+ (1.000000,0.000000) [0.000000|1.000000] "" Vector__XXX
 SG_ LH_Parklicht_HR_aktiv  : 10|1@1+ (1.000000,0.000000) [0.000000|1.000000] "" Vector__XXX
 SG_ LH_Bremslicht_H_aktiv  : 11|1@1+ (1.000000,0.000000) [0.000000|1.000000] "" Vector__XXX
 SG_ LH_Nebelschluss_aktiv  : 12|1@1+ (1.000000,0.000000) [0.000000|1.000000] "" Vector__XXX
 SG_ LH_Rueckfahrlicht_aktiv  : 13|1@1+ (1.000000,0.000000) [0.000000|1.000000] "" Vector__XXX
 SG_ LH_Blinker_HL_akt  : 14|1@1+ (1.000000,0.000000) [0.000000|1.000000] "" Vector__XXX
 SG_ LH_Blinker_HR_akt  : 15|1@1+ (1.000000,0.000000) [0.000000|1.000000] "" Vector__XXX
 SG_ LH_Blinker_li_def  : 16|1@1+ (1.000000,0.000000) [0.000000|1.000000] "" Vector__XXX
 SG_ LH_Bremsl_li_def  : 17|1@1+ (1.000000,0.000000) [0.000000|1.000000] "" Vector__XXX
 SG_ LH_Schlusslicht_li_def  : 18|1@1+ (1.000000,0.000000) [0.000000|1.000000] "" Vector__XXX
 SG_ LH_Rueckf_li_def  : 19|1@1+ (1.000000,0.000000) [0.000000|1.000000] "" Vector__XXX
 SG_ LH_Nebel_li_def  : 20|1@1+ (1.000000,0.000000) [0.000000|1.000000] "" Vector__XXX
 SG_ LH_Schluss_Brems_Nebel_li_def  : 21|1@1+ (1.000000,0.000000) [0.000000|1.000000] "" Vector__XXX
 SG_ LH_Schluss_Brems_Nebel_re_def  : 22|1@1+ (1.000000,0.000000) [0.000000|1.000000] "" Vector__XXX
 SG_ LH_Zusatzschlussl_def  : 23|1@1+ (1.000000,0.000000) [0.000000|1.000000] "" Vector__XXX
 SG_ LH_Schluss_Brems_li_def  : 24|1@1+ (1.000000,0.000000) [0.000000|1.000000] "" Vector__XXX
 SG_ LH_Schluss_Nebel_li_def  : 25|1@1+ (1.000000,0.000000) [0.000000|1.000000] "" Vector__XXX
 SG_ LH_SL_BRL_BLK_li_def  : 26|1@1+ (1.000000,0.000000) [0.000000|1.000000] "" Vector__XXX
 SG_ LH_Brems_Blk_li_def  : 27|1@1+ (1.000000,0.000000) [0.000000|1.000000] "" Vector__XXX
 SG_ LH_Diag_Status_re_def  : 28|1@1+ (1.000000,0.000000) [0.000000|1.000000] "" Vector__XXX
 SG_ LH_Diag_Status_li_def  : 29|1@1+ (1.000000,0.000000) [0.000000|1.000000] "" Vector__XXX
 SG_ LH_Diag_LED_li_def  : 30|1@1+ (1.000000,0.000000) [0.000000|1.000000] "" Vector__XXX
 SG_ LH_Diag_LED_re_def  : 31|1@1+ (1.000000,0.000000) [0.000000|1.000000] "" Vector__XXX
 SG_ LH_Blinker_re_def  : 32|1@1+ (1.000000,0.000000) [0.000000|1.000000] "" Vector__XXX
 SG_ LH_Bremsl_re_def  : 33|1@1+ (1.000000,0.000000) [0.000000|1.000000] "" Vector__XXX
 SG_ LH_Schlusslicht_re_def  : 34|1@1+ (1.000000,0.000000) [0.000000|1.000000] "" Vector__XXX
 SG_ LH_Rueckf_re_def  : 35|1@1+ (1.000000,0.000000) [0.000000|1.000000] "" Vector__XXX
 SG_ LH_Nebel_re_def  : 36|1@1+ (1.000000,0.000000) [0.000000|1.000000] "" Vector__XXX
 SG_ LH_Schluss_Brems_mi_def  : 37|1@1+ (1.000000,0.000000) [0.000000|1.000000] "" Vector__XXX
 SG_ LH_Schluss_Brems_re_def  : 40|1@1+ (1.000000,0.000000) [0.000000|1.000000] "" Vector__XXX
 SG_ LH_Schluss_Nebel_re_def  : 41|1@1+ (1.000000,0.000000) [0.000000|1.000000] "" Vector__XXX
 SG_ LH_SL_BRL_BLK_re_def  : 42|1@1+ (1.000000,0.000000) [0.000000|1.000000] "" Vector__XXX
 SG_ LH_Brems_Blk_re_def  : 43|1@1+ (1.000000,0.000000) [0.000000|1.000000] "" Vector__XXX
 SG_ LH_Kennzl_def  : 48|1@1+ (1.000000,0.000000) [0.000000|1.000000] "" Vector__XXX
 SG_ LH_3_Bremsl_def  : 49|1@1+ (1.000000,0.000000) [0.000000|1.000000] "" Motor_BEV
 SG_ LH_Nebel_mi_def  : 50|1@1+ (1.000000,0.000000) [0.000000|1.000000] "" Vector__XXX
 SG_ LH_Rueckf_mi_def  : 51|1@1+ (1.000000,0.000000) [0.000000|1.000000] "" Vector__XXX
 SG_ LH_Schlusslicht_mi_def  : 52|1@1+ (1.000000,0.000000) [0.000000|1.000000] "" Vector__XXX
 SG_ LH_Bremsl_li_ges_def  : 54|1@1+ (1.000000,0.000000) [0.000000|1.000000] "" Motor_BEV
 SG_ LH_Bremsl_re_ges_def  : 55|1@1+ (1.000000,0.000000) [0.000000|1.000000] "" Motor_BEV
 SG_ LH_Bremsl_mi_def  : 61|1@1+ (1.000000,0.000000) [0.000000|1.000000] "" Vector__XXX
 SG_ BRL_als_SHL  : 62|1@1+ (1.000000,0.000000) [0.000000|1.000000] "" Vector__XXX

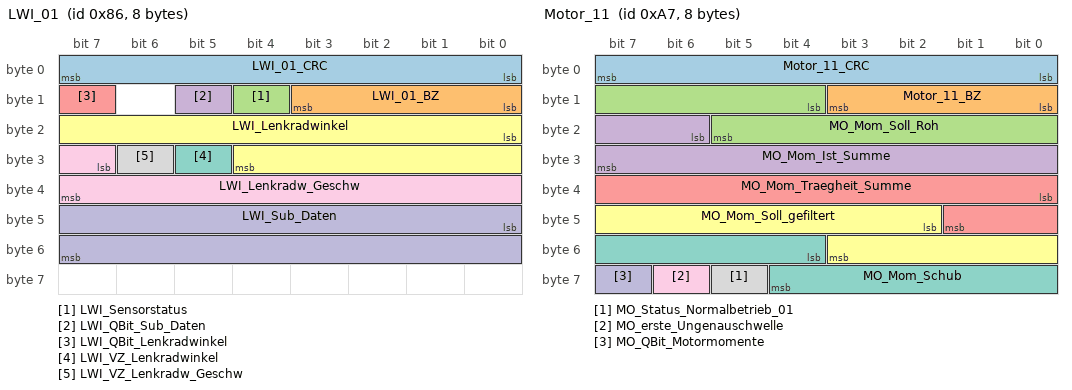
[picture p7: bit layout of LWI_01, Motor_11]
BO_ 134 LWI_01: 8 ICAS1_Gateway
 SG_ LWI_01_CRC  : 0|8@1+ (1.000000,0.000000) [0.000000|255.000000] "" Airbag Motor_BEV
 SG_ LWI_01_BZ  : 8|4@1+ (1.000000,0.000000) [0.000000|15.000000] "" Airbag Motor_BEV
 SG_ LWI_Sensorstatus  : 12|1@1+ (1.000000,0.000000) [0.000000|1.000000] "" Airbag Motor_BEV
 SG_ LWI_QBit_Sub_Daten  : 13|1@1+ (1.000000,0.000000) [0.000000|1.000000] "" Vector__XXX
 SG_ LWI_QBit_Lenkradwinkel  : 15|1@1+ (1.000000,0.000000) [0.000000|1.000000] "" Airbag Motor_BEV
 SG_ LWI_Lenkradwinkel  : 16|13@1+ (0.100000,0.000000) [0.000000|800.000000] "Unit_DegreOfArc" Airbag Motor_BEV
 SG_ LWI_VZ_Lenkradwinkel  : 29|1@1+ (1.000000,0.000000) [0.000000|1.000000] "" Airbag Motor_BEV
 SG_ LWI_VZ_Lenkradw_Geschw  : 30|1@1+ (1.000000,0.000000) [0.000000|1.000000] "" Vector__XXX
 SG_ LWI_Lenkradw_Geschw  : 31|9@1+ (5.000000,0.000000) [0.000000|2500.000000] "Unit_DegreOfArcPerSecon" Airbag
 SG_ LWI_Sub_Daten  : 40|16@1+ (1.000000,0.000000) [0.000000|65535.000000] "" Vector__XXX

BO_ 817 MFL_01: 8 ICAS1_Gateway
 SG_ MFL_Zaehler  : 0|4@1+ (1.000000,0.000000) [0.000000|15.000000] "" Vector__XXX
 SG_ MFL_Toggle  : 4|1@1+ (1.000000,0.000000) [0.000000|1.000000] "" Vector__XXX
 SG_ MFL_Lokalaktiv  : 5|1@1+ (1.000000,0.000000) [0.000000|1.000000] "" Vector__XXX
 SG_ MFL_M_Taste  : 6|1@1+ (1.000000,0.000000) [0.000000|1.000000] "" Vector__XXX
 SG_ MFL_Paddle_Verbau  : 7|1@1+ (1.000000,0.000000) [0.000000|1.000000] "" Vector__XXX
 SG_ MFL_Tastencode_1  : 8|8@1+ (1.000000,0.000000) [0.000000|255.000000] "" Vector__XXX
 SG_ MFL_Tastencode_2  : 16|8@1+ (1.000000,0.000000) [0.000000|255.000000] "" Vector__XXX
 SG_ MFL_Eventcode_1  : 24|4@1+ (1.000000,0.000000) [0.000000|15.000000] "" Vector__XXX
 SG_ MFL_Eventcode_2  : 28|4@1+ (1.000000,0.000000) [0.000000|15.000000] "" Vector__XXX
 SG_ MFL_Marke  : 32|4@1+ (1.000000,0.000000) [0.000000|15.000000] "" Vector__XXX
 SG_ MFL_Variante  : 36|4@1+ (1.000000,0.000000) [0.000000|15.000000] "" Vector__XXX
 SG_ MFL_Dummy_0_Signal_1  : 40|8@1+ (1.000000,0.000000) [0.000000|255.000000] "" Vector__XXX
 SG_ MFL_Tip_Down  : 48|1@1+ (1.000000,0.000000) [0.000000|1.000000] "" Motor_BEV
 SG_ MFL_Tip_Up  : 49|1@1+ (1.000000,0.000000) [0.000000|1.000000] "" Motor_BEV
 SG_ MFL_SatModul_links_Err  : 50|1@1+ (1.000000,0.000000) [0.000000|1.000000] "" Vector__XXX
 SG_ MFL_SatModul_rechts_Err  : 51|1@1+ (1.000000,0.000000) [0.000000|1.000000] "" Vector__XXX
 SG_ MFL_Dummy_0_Signal_2  : 52|1@1+ (1.000000,0.000000) [0.000000|1.000000] "" Vector__XXX
 SG_ MFL_Dummy_0_Signal_3  : 53|1@1+ (1.000000,0.000000) [0.000000|1.000000] "" Vector__XXX
 SG_ MFL_LR_HZG_Status  : 54|1@1+ (1.000000,0.000000) [0.000000|1.000000] "" Vector__XXX
 SG_ MFL_LR_HZG_Err  : 55|1@1+ (1.000000,0.000000) [0.000000|1.000000] "" Vector__XXX
 SG_ MFL_Signalhorn  : 56|1@1+ (1.000000,0.000000) [0.000000|1.000000] "" Vector__XXX
 SG_ MFL_Signalhorn_Err  : 57|1@1+ (1.000000,0.000000) [0.000000|1.000000] "" Vector__XXX
 SG_ MFL_Tip_links_Err  : 58|1@1+ (1.000000,0.000000) [0.000000|1.000000] "" Vector__XXX
 SG_ MFL_Tip_rechts_Err  : 59|1@1+ (1.000000,0.000000) [0.000000|1.000000] "" Vector__XXX
 SG_ MFL_Taste_links_Err  : 60|1@1+ (1.000000,0.000000) [0.000000|1.000000] "" Vector__XXX
 SG_ MFL_Taste_rechts_Err  : 61|1@1+ (1.000000,0.000000) [0.000000|1.000000] "" Vector__XXX
 SG_ MFL_ECU_Err  : 62|1@1+ (1.000000,0.000000) [0.000000|1.000000] "" Vector__XXX
 SG_ MFL_Response_Err  : 63|1@1+ (1.000000,0.000000) [0.000000|1.000000] "" Vector__XXX

BO_ 15 MO_SOPC: 1 Motor_BEV
 SG_ MO_SOPC  : 0|1@1+ (1.000000,0.000000) [0.000000|1.000000] "" Vector__XXX

BO_ 1600 Motor_07: 8 Motor_BEV
 SG_ MO_QBit_Ansaugluft_Temp  : 0|1@1+ (1.000000,0.000000) [0.000000|1.000000] "" Vector__XXX
 SG_ MO_QBit_Oel_Temp  : 1|1@1+ (1.000000,0.000000) [0.000000|1.000000] "" Vector__XXX
 SG_ MO_QBit_Kuehlmittel_Temp  : 2|1@1+ (1.000000,0.000000) [0.000000|1.000000] "" Vector__XXX
 SG_ MO_KL15_Abschaltempfehlung  : 3|1@1+ (1.000000,0.000000) [0.000000|1.000000] "" Vector__XXX
 SG_ MO_HYB_Fehler_HV_Netz  : 4|1@1+ (1.000000,0.000000) [0.000000|1.000000] "" Vector__XXX
 SG_ MO_aktives_Getriebeheizen  : 5|1@1+ (1.000000,0.000000) [0.000000|1.000000] "" Vector__XXX
 SG_ MO_Absperrventil_oeffnen  : 6|2@1+ (1.000000,0.000000) [0.000000|3.000000] "" Vector__XXX
 SG_ MO_Ansaugluft_Temp  : 8|8@1+ (0.750000,-48.000000) [-48.000000|141.750000] "Unit_DegreCelsi" Vector__XXX
 SG_ MO_Oel_Temp  : 16|8@1+ (1.000000,-60.000000) [-60.000000|192.000000] "Unit_DegreCelsi" Vector__XXX
 SG_ MO_Kuehlmittel_Temp  : 24|8@1+ (0.750000,-48.000000) [-48.000000|141.750000] "Unit_DegreCelsi" Vector__XXX
 SG_ MO_Hoeheninfo  : 32|8@1+ (0.007810,0.000000) [0.000000|1.983740] "" Vector__XXX
 SG_ MO_Kennfeldk  : 40|1@1+ (1.000000,0.000000) [0.000000|1.000000] "" Vector__XXX
 SG_ MO_Versionsinfo_02  : 41|5@1+ (1.000000,0.000000) [0.000000|31.000000] "" Vector__XXX
 SG_ MO_QBit_Hoeheninfo  : 46|1@1+ (1.000000,0.000000) [0.000000|1.000000] "" Vector__XXX
 SG_ MO_Getriebe_kuehlen  : 47|1@1+ (1.000000,0.000000) [0.000000|1.000000] "" Vector__XXX
 SG_ MO_Mom_Traegheit_02  : 48|5@1+ (0.010000,0.000000) [0.000000|0.310000] "Unit_KiloGramMeterSquar" Vector__XXX
 SG_ MO_Heizungspumpenansteuerung  : 53|4@1+ (10.000000,0.000000) [0.000000|100.000000] "Unit_PerCent" Vector__XXX
 SG_ MO_SpannungsAnf  : 57|1@1+ (1.000000,0.000000) [0.000000|1.000000] "" Vector__XXX
 SG_ MO_Nachlaufzeit_Heizungspumpe  : 58|6@1+ (15.000000,0.000000) [0.000000|945.000000] "Unit_Secon" Vector__XXX

BO_ 167 Motor_11: 8 Motor_BEV
 SG_ Motor_11_CRC  : 0|8@1+ (1.000000,0.000000) [0.000000|255.000000] "" ICAS1_Gateway
 SG_ Motor_11_BZ  : 8|4@1+ (1.000000,0.000000) [0.000000|15.000000] "" ICAS1_Gateway
 SG_ MO_Mom_Soll_Roh  : 12|10@1+ (1.000000,-509.000000) [-509.000000|509.000000] "" ICAS1_Gateway
 SG_ MO_Mom_Ist_Summe  : 22|10@1+ (1.000000,-509.000000) [-509.000000|509.000000] "" ICAS1_Gateway
 SG_ MO_Mom_Traegheit_Summe  : 32|10@1+ (1.000000,-509.000000) [-509.000000|509.000000] "" ICAS1_Gateway
 SG_ MO_Mom_Soll_gefiltert  : 42|10@1+ (1.000000,-509.000000) [-509.000000|509.000000] "" ICAS1_Gateway
 SG_ MO_Mom_Schub  : 52|9@1+ (1.000000,-509.000000) [-509.000000|0.000000] "" ICAS1_Gateway
 SG_ MO_Status_Normalbetrieb_01  : 61|1@1+ (1.000000,0.000000) [0.000000|1.000000] "" ICAS1_Gateway
 SG_ MO_erste_Ungenauschwelle  : 62|1@1+ (1.000000,0.000000) [0.000000|1.000000] "" ICAS1_Gateway
 SG_ MO_QBit_Motormomente  : 63|1@1+ (1.000000,0.000000) [0.000000|1.000000] "" ICAS1_Gateway

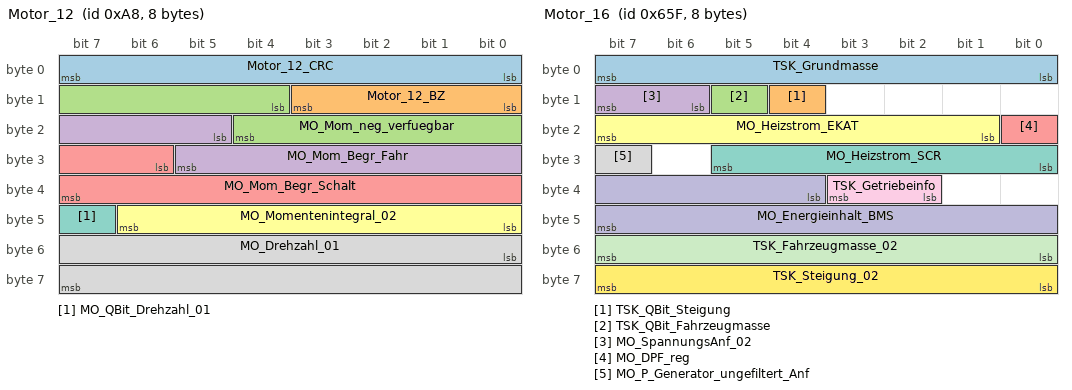
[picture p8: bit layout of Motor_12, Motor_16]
BO_ 168 Motor_12: 8 Motor_BEV
 SG_ Motor_12_CRC  : 0|8@1+ (1.000000,0.000000) [0.000000|255.000000] "" ICAS1_Gateway
 SG_ Motor_12_BZ  : 8|4@1+ (1.000000,0.000000) [0.000000|15.000000] "" ICAS1_Gateway
 SG_ MO_Mom_neg_verfuegbar  : 12|9@1+ (1.000000,-509.000000) [-509.000000|0.000000] "" ICAS1_Gateway
 SG_ MO_Mom_Begr_Fahr  : 21|9@1+ (1.000000,0.000000) [0.000000|509.000000] "" ICAS1_Gateway
 SG_ MO_Mom_Begr_Schalt  : 30|10@1+ (1.000000,-509.000000) [-509.000000|509.000000] "" ICAS1_Gateway
 SG_ MO_Momentenintegral_02  : 40|7@1+ (1.000000,0.000000) [0.000000|100.000000] "Unit_PerCent" ICAS1_Gateway
 SG_ MO_QBit_Drehzahl_01  : 47|1@1+ (1.000000,0.000000) [0.000000|1.000000] "" Airbag ICAS1_Gateway LE2
 SG_ MO_Drehzahl_01  : 48|16@1+ (0.250000,0.000000) [0.000000|16383.000000] "Unit_MinutInver" ICAS1_Gateway

BO_ 958 Motor_14: 8 Motor_BEV
 SG_ Motor_14_CRC  : 0|8@1+ (1.000000,0.000000) [0.000000|255.000000] "" ICAS1_Gateway
 SG_ Motor_14_BZ  : 8|4@1+ (1.000000,0.000000) [0.000000|15.000000] "" ICAS1_Gateway
 SG_ MO_StartStopp_Status  : 12|2@1+ (1.000000,0.000000) [0.000000|3.000000] "" ICAS1_Gateway
 SG_ MO_StartStopp_Wiederstart  : 14|1@1+ (1.000000,0.000000) [0.000000|1.000000] "" ICAS1_Gateway
 SG_ MO_StartStopp_Motorstopp  : 15|1@1+ (1.000000,0.000000) [0.000000|1.000000] "" ICAS1_Gateway
 SG_ MO_Freig_Reku  : 16|2@1+ (1.000000,0.000000) [0.000000|3.000000] "" ICAS1_Gateway
 SG_ MO_Kl_75  : 18|1@1+ (1.000000,0.000000) [0.000000|1.000000] "" ICAS1_Gateway
 SG_ MO_Kl_50  : 19|1@1+ (1.000000,0.000000) [0.000000|1.000000] "" ICAS1_Gateway
 SG_ MO_Gangposition  : 20|4@1+ (1.000000,0.000000) [0.000000|15.000000] "" ICAS1_Gateway
 SG_ MO_StartStopp_Fahrerwunsch  : 24|2@1+ (1.000000,0.000000) [0.000000|3.000000] "" ICAS1_Gateway
 SG_ MO_HYB_Fahrbereitschaft  : 26|1@1+ (1.000000,0.000000) [0.000000|1.000000] "" ICAS1_Gateway
 SG_ MO_Ext_E_Fahrt_aktiv  : 27|1@1+ (1.000000,0.000000) [0.000000|1.000000] "" ICAS1_Gateway
 SG_ MO_Fahrer_bremst  : 28|1@1+ (1.000000,0.000000) [0.000000|1.000000] "" Airbag ICAS1_Gateway
 SG_ MO_QBit_Fahrer_bremst  : 29|1@1+ (1.000000,0.000000) [0.000000|1.000000] "" Airbag ICAS1_Gateway
 SG_ MO_BLS  : 30|1@1+ (1.000000,0.000000) [0.000000|1.000000] "" Airbag ICAS1_Gateway
 SG_ MO_Konsistenz_Bremsped  : 31|1@1+ (1.000000,0.000000) [0.000000|1.000000] "" ICAS1_Gateway
 SG_ MO_Timeout_ESP  : 32|1@1+ (1.000000,0.000000) [0.000000|1.000000] "" ICAS1_Gateway
 SG_ MO_Klima_Eingr  : 33|2@1+ (1.000000,0.000000) [0.000000|3.000000] "" ICAS1_Gateway
 SG_ MO_Aussp_Anlass  : 35|1@1+ (1.000000,0.000000) [0.000000|1.000000] "" ICAS1_Gateway
 SG_ MO_Freig_Anlass  : 36|1@1+ (1.000000,0.000000) [0.000000|1.000000] "" ICAS1_Gateway
 SG_ MO_Kuppl_schalter  : 37|1@1+ (1.000000,0.000000) [0.000000|1.000000] "" ICAS1_Gateway
 SG_ MO_Interlock  : 38|1@1+ (1.000000,0.000000) [0.000000|1.000000] "" ICAS1_Gateway
 SG_ MO_Motor_laeuft  : 39|1@1+ (1.000000,0.000000) [0.000000|1.000000] "" ICAS1_Gateway
 SG_ MO_Kickdown  : 40|1@1+ (1.000000,0.000000) [0.000000|1.000000] "" ICAS1_Gateway ICAS1_KommunikationsServer
 SG_ MO_QBit_KL_75  : 41|1@1+ (1.000000,0.000000) [0.000000|1.000000] "" ICAS1_Gateway
 SG_ MO_EKlKomLeiRed  : 42|2@1+ (1.000000,0.000000) [0.000000|3.000000] "" ICAS1_Gateway
 SG_ MO_Handshake_STH  : 44|1@1+ (1.000000,0.000000) [0.000000|1.000000] "" ICAS1_Gateway
 SG_ MO_BKV_Unterdruckwarnung  : 45|1@1+ (1.000000,0.000000) [0.000000|1.000000] "" ICAS1_Gateway
 SG_ MO_Freigabe_Segeln  : 46|1@1+ (1.000000,0.000000) [0.000000|1.000000] "" ICAS1_Gateway
 SG_ MO_PTC_Status  : 47|3@1+ (1.000000,0.000000) [0.000000|7.000000] "" ICAS1_Gateway
 SG_ MO_QBit_Gangposition  : 50|1@1+ (1.000000,0.000000) [0.000000|1.000000] "" ICAS1_Gateway
 SG_ MO_Signalquelle_Gangposition  : 51|1@1+ (1.000000,0.000000) [0.000000|1.000000] "" ICAS1_Gateway
 SG_ MO_Remotestart_Betrieb  : 52|1@1+ (1.000000,0.000000) [0.000000|1.000000] "" ICAS1_Gateway
 SG_ MO_Remotestart_moeglich  : 53|1@1+ (1.000000,0.000000) [0.000000|1.000000] "" ICAS1_Gateway
 SG_ MO_FMAus_aktiv  : 55|1@1+ (1.000000,0.000000) [0.000000|1.000000] "" ICAS1_Gateway
 SG_ MO_FMAus_Startvariante  : 56|2@1+ (1.000000,0.000000) [0.000000|3.000000] "" ICAS1_Gateway
 SG_ MO_BMS_NV_Anf_stuetzen  : 58|1@1+ (1.000000,0.000000) [0.000000|1.000000] "" ICAS1_Gateway
 SG_ MO_Zylinderabschaltung  : 59|2@1+ (1.000000,0.000000) [0.000000|3.000000] "" ICAS1_Gateway
 SG_ MO_HYB_VM_aktiv  : 61|1@1+ (1.000000,0.000000) [0.000000|1.000000] "" ICAS1_Gateway
 SG_ MO_StartVorauss_erfuellt  : 62|2@1+ (1.000000,0.000000) [0.000000|3.000000] "" ICAS1_Gateway

BO_ 1631 Motor_16: 8 Motor_BEV
 SG_ TSK_Grundmasse  : 0|8@1+ (32.000000,0.000000) [0.000000|8128.000000] "Unit_KiloGram" ICAS1_Gateway
 SG_ TSK_QBit_Steigung  : 12|1@1+ (1.000000,0.000000) [0.000000|1.000000] "" ICAS1_Gateway
 SG_ TSK_QBit_Fahrzeugmasse  : 13|1@1+ (1.000000,0.000000) [0.000000|1.000000] "" ICAS1_Gateway
 SG_ MO_SpannungsAnf_02  : 14|2@1+ (1.000000,0.000000) [0.000000|3.000000] "" ICAS1_Gateway
 SG_ MO_DPF_reg  : 16|1@1+ (1.000000,0.000000) [0.000000|1.000000] "" ICAS1_Gateway
 SG_ MO_Heizstrom_EKAT  : 17|7@1+ (1.000000,0.000000) [0.000000|126.000000] "Unit_Amper" ICAS1_Gateway
 SG_ MO_Heizstrom_SCR  : 24|6@1+ (1.000000,0.000000) [0.000000|62.000000] "Unit_Amper" ICAS1_Gateway
 SG_ MO_P_Generator_ungefiltert_Anf  : 31|1@1+ (1.000000,0.000000) [0.000000|1.000000] "" ICAS1_Gateway
 SG_ TSK_Getriebeinfo  : 34|2@1+ (1.000000,0.000000) [0.000000|3.000000] "" ICAS1_Gateway
 SG_ MO_Energieinhalt_BMS  : 36|12@1+ (25.000000,0.000000) [0.000000|102325.000000] "Unit_WattHour" ICAS1_Gateway
 SG_ TSK_Fahrzeugmasse_02  : 48|8@1+ (32.000000,0.000000) [0.000000|8128.000000] "Unit_KiloGram" ICAS1_Gateway
 SG_ TSK_Steigung_02  : 56|8@1+ (0.800000,-101.600000) [-100.800000|101.600000] "Unit_PerCent" ICAS1_Gateway

BO_ 1648 Motor_18: 8 Motor_BEV
 SG_ MO_max_Ladedruck  : 0|6@1+ (0.100000,0.000000) [0.000000|6.300000] "Unit_Bar" ICAS1_Gateway
 SG_ MO_ANC_Kennfeld_Anf  : 6|2@1+ (1.000000,0.000000) [0.000000|3.000000] "" ICAS1_Gateway
 SG_ MO_Bremslicht_Reku  : 8|1@1+ (1.000000,0.000000) [0.000000|1.000000] "" ICAS1_Gateway
 SG_ MO_StartStopp_PopUp  : 9|2@1+ (1.000000,0.000000) [0.000000|3.000000] "" ICAS1_Gateway
 SG_ MO1_Sperr_Info_WFS  : 11|1@1+ (1.000000,0.000000) [0.000000|1.000000] "" ICAS1_Gateway
 SG_ MO1_Freigabe_Info_WFS  : 12|1@1+ (1.000000,0.000000) [0.000000|1.000000] "" ICAS1_Gateway
 SG_ MO_EPCL  : 13|3@1+ (1.000000,0.000000) [0.000000|7.000000] "" ICAS1_Gateway ICAS1_KommunikationsServer
 SG_ MO_Zylabsch_Texte_02  : 16|4@1+ (1.000000,0.000000) [0.000000|15.000000] "" ICAS1_Gateway
 SG_ MO_Fahrzeugtyp  : 20|3@1+ (1.000000,0.000000) [0.000000|7.000000] "" ICAS1_Gateway ICAS1_KommunikationsServer
 SG_ MO_NMAX_Schaltanzeige  : 23|9@1+ (25.000000,0.000000) [0.000000|12775.000000] "Unit_MinutInver" ICAS1_Gateway
 SG_ MO_Abstellzeit  : 32|8@1+ (8.000000,0.000000) [0.000000|2024.000000] "Unit_Minut" ICAS1_Gateway
 SG_ MO_Abstellzeit_Status  : 40|2@1+ (1.000000,0.000000) [0.000000|3.000000] "" ICAS1_Gateway
 SG_ MO1_Freigabe_Verfallsinfo_WFS  : 42|1@1+ (1.000000,0.000000) [0.000000|1.000000] "" ICAS1_Gateway
 SG_ MO_Hybrid_StartStopp_LED  : 43|2@1+ (1.000000,0.000000) [0.000000|3.000000] "" ICAS1_Gateway
 SG_ MO_Fehler_Zylabsch  : 45|2@1+ (1.000000,0.000000) [0.000000|3.000000] "" ICAS1_Gateway
 SG_ MO_Anzahl_Abgesch_Zyl  : 47|3@1+ (1.000000,0.000000) [0.000000|7.000000] "" ICAS1_Gateway
 SG_ MO_Zylabsch_Texte  : 50|2@1+ (1.000000,0.000000) [0.000000|3.000000] "" ICAS1_Gateway
 SG_ MO_Ethanol_BS_Texte  : 52|3@1+ (1.000000,0.000000) [0.000000|7.000000] "" ICAS1_Gateway
 SG_ MO_Drehzahl_Warnung  : 55|1@1+ (1.000000,0.000000) [0.000000|1.000000] "" ICAS1_Gateway
 SG_ MO_obere_Drehzahlgrenze  : 56|8@1+ (50.000000,0.000000) [50.000000|12750.000000] "Unit_MinutInver" ICAS1_Gateway

BO_ 967 Motor_26: 8 Motor_BEV
 SG_ MO_Kuehlerluefter_MUX M : 0|1@1+ (1.000000,0.000000) [0.000000|1.000000] "siema ooo" ICAS1_Gateway
 SG_ MO_Kuehlerluefter_1 m0 : 1|7@1+ (1.000000,0.000000) [0.000000|100.000000] "Unit_PerCent" ICAS1_Gateway
 SG_ MO_Kuehlerluefter_2 m1 : 1|7@1+ (1.000000,0.000000) [0.000000|100.000000] "Unit_PerCent" ICAS1_Gateway
 SG_ MO_EFLEX_Lampe  : 8|2@1+ (1.000000,0.000000) [0.000000|3.000000] "" ICAS1_Gateway
 SG_ MO_KJS_nicht_bereit  : 10|1@1+ (1.000000,0.000000) [0.000000|1.000000] "" ICAS1_Gateway
 SG_ MO_ITM_Warnung_Pumpe  : 11|1@1+ (1.000000,0.000000) [0.000000|1.000000] "" ICAS1_Gateway
 SG_ WIV_Anzeige_aktiv  : 12|1@1+ (1.000000,0.000000) [0.000000|1.000000] "" ICAS1_Gateway
 SG_ WIV_Oelmin_Warn  : 13|1@1+ (1.000000,0.000000) [0.000000|1.000000] "" ICAS1_Gateway
 SG_ WIV_Sensorfehler  : 14|1@1+ (1.000000,0.000000) [0.000000|1.000000] "" ICAS1_Gateway
 SG_ WIV_Schieflage  : 15|1@1+ (1.000000,0.000000) [0.000000|1.000000] "" ICAS1_Gateway
 SG_ WIV_Oelstand  : 16|4@1+ (12.500000,0.000000) [0.000000|100.000000] "Unit_PerCent" ICAS1_Gateway
 SG_ MO_Zustand_HWP  : 20|2@1+ (1.000000,0.000000) [0.000000|3.000000] "" ICAS1_Gateway
 SG_ OLEV_Systemstoerung  : 22|1@1+ (1.000000,0.000000) [0.000000|1.000000] "" ICAS1_Gateway
 SG_ MO_Oelwarnung_max  : 23|1@1+ (1.000000,0.000000) [0.000000|1.000000] "" ICAS1_Gateway
 SG_ WIV_Oelsystem_aktiv  : 24|1@1+ (1.000000,0.000000) [0.000000|1.000000] "" ICAS1_Gateway
 SG_ WIV_nicht_betriebswarm  : 25|1@1+ (1.000000,0.000000) [0.000000|1.000000] "" ICAS1_Gateway
 SG_ WIV_Ueberfuell_Warn  : 26|1@1+ (1.000000,0.000000) [0.000000|1.000000] "" ICAS1_Gateway
 SG_ WIV_laufender_Motor  : 27|1@1+ (1.000000,0.000000) [0.000000|1.000000] "" ICAS1_Gateway
 SG_ MO_E_Warnungen  : 28|4@1+ (1.000000,0.000000) [0.000000|15.000000] "" ICAS1_Gateway
 SG_ MO_Text_Motorstart  : 32|4@1+ (1.000000,0.000000) [0.000000|15.000000] "" ICAS1_Gateway
 SG_ MO_E_Texte  : 36|4@1+ (1.000000,0.000000) [0.000000|15.000000] "" ICAS1_Gateway
 SG_ WIV_Oeldyn_avl  : 40|1@1+ (1.000000,0.000000) [0.000000|1.000000] "" ICAS1_Gateway
 SG_ MO_Text_Partikelfil_Reg  : 41|1@1+ (1.000000,0.000000) [0.000000|1.000000] "" ICAS1_Gateway
 SG_ OLEV_Oelstand_nicht_vorhanden  : 42|1@1+ (1.000000,0.000000) [0.000000|1.000000] "" ICAS1_Gateway
 SG_ WIV_Oelmenge  : 43|5@1+ (125.000000,0.000000) [0.000000|3875.000000] "Unit_MilliLiter" ICAS1_Gateway
 SG_ MO_Systemlampe  : 48|1@1+ (1.000000,0.000000) [0.000000|1.000000] "" ICAS1_Gateway
 SG_ MO_OBD2_Lampe  : 49|1@1+ (1.000000,0.000000) [0.000000|1.000000] "" ICAS1_Gateway
 SG_ MO_Heissleuchte  : 50|1@1+ (1.000000,0.000000) [0.000000|1.000000] "" ICAS1_Gateway
 SG_ MO_Partikel_Lampe  : 51|1@1+ (1.000000,0.000000) [0.000000|1.000000] "" ICAS1_Gateway
 SG_ MO_RedFahrleistung_Lampe  : 52|1@1+ (1.000000,0.000000) [0.000000|1.000000] "" ICAS1_Gateway ICAS1_KommunikationsServer
 SG_ WIV_Oelstand_nicht_vorhanden  : 53|1@1+ (1.000000,0.000000) [0.000000|1.000000] "" ICAS1_Gateway
 SG_ WIV_nachfuellanzeige_ein  : 54|1@1+ (1.000000,0.000000) [0.000000|1.000000] "" ICAS1_Gateway
 SG_ WIV_Ueberfuell_deaktiv  : 55|1@1+ (1.000000,0.000000) [0.000000|1.000000] "" ICAS1_Gateway
 SG_ WIV_Unterfuell_Warn  : 56|1@1+ (1.000000,0.000000) [0.000000|1.000000] "" ICAS1_Gateway
 SG_ MO_Tankdeckel_Lampe  : 57|1@1+ (1.000000,0.000000) [0.000000|1.000000] "" ICAS1_Gateway
 SG_ MO_Text_Tankdeckelwarn  : 58|1@1+ (1.000000,0.000000) [0.000000|1.000000] "" ICAS1_Gateway
 SG_ MO_Vorglueh_Lampe  : 59|1@1+ (1.000000,0.000000) [0.000000|1.000000] "" ICAS1_Gateway
 SG_ WIV_Oeldr_Warn_Motor  : 60|1@1+ (1.000000,0.000000) [0.000000|1.000000] "" ICAS1_Gateway
 SG_ MO_E_Mode  : 61|3@1+ (1.000000,0.000000) [0.000000|7.000000] "" ICAS1_Gateway

CM_ BO_ 2527679583 "ehemalsZFAS_01";
CM_ BO_ 2621505536 "VWAGDiagnosefunktionalerRequestaufCANFD";
CM_ BO_ 960 "MQB";
CM_ BO_ 949 "abMQB7.4";
CM_ BO_ 1505 "abMQB7.3";
CM_ BO_ 982 "MQB";
CM_ BO_ 134 "abMQBmitCRCinByte1";
CM_ BO_ 1600 "abMQBmitQBitHöheneinfoundMO_Versionsinfo_02";
CM_ BO_ 168 "Teil2neueMomentenschnittstelleMLB";
CM_ BO_ 1648 "Kombischnittstelle";
CM_ BO_ 967 "MQB-vorherMotor_06/Umbenennungwg.ID-Wechsel";
CM_ SG_ 299 GRA_ACC_01_CRC "FürMLB:
'Berechnung siehe Lastenheft 'Kommunikationsabsicherung für FlexRay und CAN''

Ab MQB und MLBevo:
'Berechnung siehe Lastenheft 'End-to-End Kommunikationsabsicherung''

Endwerte siehe Begleitdokument 'S-PDU Kennungsfolgen'";
CM_ SG_ 299 GRA_ACC_01_BZ "4bitBotschaftszaehler,wirdmitjederSendebotschaftinkrementiert";
CM_ SG_ 299 GRA_Hauptschalter "StellungdesGRA/ACC-Hauptschalters:
Bei gerastetem Hauptschalter:
0: Hauptschalter aus
1: Hauptschalter ein
Bei getastetem Hauptschalter:
0: Taster nicht betätigt
1: Taster betätigt";
CM_ SG_ 299 GRA_Abbrechen "GRA:ausmitspeichern
ACC : Soft aus";
CM_ SG_ 299 GRA_Typ_Hauptschalter "VariantedesGRA/ACC-Hauptschalters:
0: gerasteter Hauptschalter (bzw. Taster mit Speicherung des Status im SMLS (PAG))
1: getasteter Hauptschalter, keine Speicherung des Status im SMLS";
CM_ SG_ 299 GRA_Limiter "StellungdesLimiter-Tasters";
CM_ SG_ 299 GRA_Tip_Setzen "TippschalterSet";
CM_ SG_ 299 GRA_Tip_Hoch "TippschalterTipUp/Geschwindigkeiterhöhen";
CM_ SG_ 299 GRA_Tip_Runter "TippschalterTipDown/Geschwindigkeitreduzieren";
CM_ SG_ 299 GRA_Tip_Wiederaufnahme "TippschalterWiederaufnahme";
CM_ SG_ 299 GRA_Verstellung_Zeitluecke "VerstellungderZeitlückefürACC

DIST -1 = Zeitluecke um 1 Stufe kleiner
DIST +1 = Zeitluecke um 1 Stufe groeßer
DIST Toggle = Zeitlücke um 1 Stufe kleiner, von kleinster Stufe auf größte Stufe";
CM_ SG_ 299 GRA_Codierung "DasSignalzeigtan,obdasSende-SG(SMLS/MFL)aufGRA-oderACC-Bedienteilcodiertist:
0: kein GRA- oder ACC Bedienteil
1: GRA-Bedienteil
2: ACC-Bedienteil
3: Limiter_Only-Bedienteil";
CM_ SG_ 299 GRA_Fehler "DasSignalzeigtan,dassdasSende-SG(SMLS/MFG)einenDefektdesGRA-BedienteilserkannthatundhierzueinFSPEabgelegtwurde.";
CM_ SG_ 299 GRA_LIM_Taste_verfuegbar "DasSignalzeigtan,obeineLimiter-UmschalttasteamjeweiligenGRA/ACC-Bedienelementvorhandenist.";
CM_ SG_ 299 GRA_Tip_Stufe_2 "Signalzeigtan,dassderzweistufigeGRA/ACC-Hebel(8_Positions_Bedienteil)inder2.Tip-Stufebetätigtwird.DasSignalwirdnurgleichzeitigmitdemSignalGRA_Tip_HochoderGRA_Tip_Runtergesetzt,wobeidieBitsGRA_Tip_Hochbzw.GRA_Tip_RunterdieR";
CM_ SG_ 299 GRA_Typ_Bedienteil "DasSignalkennzeichnetdieVariantedesGRA/ACC-Bedienteils:
0: Init
1: 4-Positionen-Bedienteil (z.B. GRA im Blinkerhebel)
2: 6-Positionen-Bedienteil (GRA/ACC-Bedienteil mit separaten Stellungen für Set/Resume/TipUp/TipDown)
3: 8-Positionen-Bediente";
CM_ SG_ 299 GRA_TravelAssist "TastefürTravelAssist";
CM_ SG_ 299 GRA_reserveByte4 "Zweck:BefüllenderreserviertenBitpositionenmit0(wg.LIN-TeilnehmerMFL)";
CM_ SG_ 299 GRA_reserveByte5 "Zweck:BefüllenderreserviertenBitpositionenmit0(wg.LIN-TeilnehmerMFL)";
CM_ SG_ 299 GRA_reserveByte6 "Zweck:BefüllenderreserviertenBitpositionenmit0(wg.LIN-TeilnehmerMFL)";
CM_ SG_ 299 GRA_reserveByte7 "Zweck:BefüllenderreserviertenBitpositionenmit0(wg.LIN-TeilnehmerMFL)";
CM_ SG_ 299 GRA_reserveByte8 "Zweck:BefüllenderreserviertenBitpositionenmit0(wg.LIN-TeilnehmerMFL)";
CM_ SG_ 1452 HVEM_IstStrom_HVVerbraucher "IststromaufnahmederelektrischenNebenaggregateausdemHVZwischenkreis";
CM_ SG_ 1452 HVEM_Energie_Klima_Vorgabe_HighR "ErweiterteAuflösungvon10WhfürSignalHVEM_Energie_Klima_Vorgabe.
Signalwert wird zu HVEM_Energie_Klima_Vorgabe Addiert";
CM_ SG_ 1452 HVEM_IstLeistungNA "aktuelleLeistungsaufnahmederNebenaggregate";
CM_ SG_ 1452 HVEM_Leistung_Klima_Vorgabe "LeistungsvorgabeThermo(fürKühlenundHeizen)";
CM_ SG_ 1452 HVEM_Nutzbare_Energie "NutzbareEnergiewelchefürKomfortfunktionenvomHVEMfreigegebenwird.";
CM_ SG_ 1452 HVEM_Energie_Klima_Vorgabe "HVEM-EnergievorgabefürKlima-Vorkonditionierung";
CM_ SG_ 1452 HVEM_HVK_Aktivitaet "DemHVEMsindHV-Komponentenzugeordnet.DasHVEMübermitteltandenHVKein
Hochvolt –Aktivitätsstatus dieser HV-Komponenten.";
CM_ SG_ 1452 HVEM_Pruefpuls_Anf "PrüfpulsanforderungandenHV-Koordinator";
CM_ SG_ 1452 HVEM_HV_Anf "HVAnforderungdesHVEnergiemanagementsandasMSG";
CM_ SG_ 1452 HVEM_MO_MaxLeistungIgnoriert "RueckmeldungdesHVEMobdievorgegebeneMaxLeistungvomMSGeingehaltenwird.";
CM_ SG_ 1385 HVEM_NVLeistungEmpf "MaximalerSollwertderaktuellenLeistungderNV-SeitedesDCDC-Wandlers.";
CM_ SG_ 1385 HVEM_DCDC_Freigabe "FreigabedesDCDCwenndasFzgnichtFahrbereitist.";
CM_ SG_ 1385 HVEM_KlimaMaxHVStrom "KommuniziertdemKlimasteuergerätdenmax.Aufnahmestrom";
CM_ SG_ 1385 HVEM_Ladesteckerentr_Anf "AnforderungLadesteckerentriegelnnachZVAufBefehl";
CM_ SG_ 1385 HVEM_LeistungsAnf "AnforderunganNV-EMzurErhöhungderPerformancedenEnergieverbrauchaufderNV-Seitezureduzieren.";
CM_ SG_ 1385 HVEM_Nachlad_Status "StatusderUmsetzungderNachladeanforderungderNV-Seite.";
CM_ SG_ 1385 HVEM_Abschaltstatus "StatusderReduzierungsstufenderKlimakomponentenbeimLaden

0 = 100% (keine Reduzierung)
1 = 75%
2 = 50%
3 = 25%
7 = Init";
CM_ SG_ 1385 HVEM_Anf_ReichweiteNV "AnforderunganNV-EMzurErhöhungderReichweitedenEnergieverbrauchaufderNV-Seitezureduzieren.";
CM_ SG_ 1385 HVEM_LadeklappenVerr_Anf "AnforderungeinesVer-oderEntriegelnsderLadedosenklappeüberdieZV.";
CM_ SG_ 1385 HVEM_Max_VK_Betriebsdauer "BetriebslaufzeitderStandklimatisierung";
CM_ SG_ 1385 HVEM_HV_Anf "HVAnforderungdesHVEnergiemanagementsandasMSG";
CM_ SG_ 1385 HVEM_Text_1 "MeldungbeieinemAnzeigeSOC<10%('AchtungBatterieladen.Funktioneneingeschränkt')";
CM_ SG_ 1385 HVEM_Nachladen_Anf "AnforderungfürHVLadenbeigestecktemSteckerunddeaktivierterLadeanforderung";
CM_ SG_ 1385 HVEM_FreigabeKlimatisierung "Klimatisierungfreigeben";
CM_ SG_ 1385 HVEM_Leistung_Bat_Kond_Vorgabe "elektr.LeistungsvorgabeThermoBatterie";
CM_ SG_ 1283 HVK_01_CRC "FürMLB:
'Berechnung siehe Lastenheft 'Kommunikationsabsicherung für FlexRay und CAN''

Ab MQB und MLBevo:
'Berechnung siehe Lastenheft 'End-to-End Kommunikationsabsicherung''

Endwerte siehe Begleitdokument 'S-PDU Kennungsfolgen'";
CM_ SG_ 1283 HVK_Istmodus_Anf "HVK-AnforderunganalleHV-KomponentenderenIstmodusimschnellenZyklus(Inhibitzeit)zusenden.";
CM_ SG_ 1283 HVK_TN1_Sollmodus "AngeforderterSollmodusderSteuereinheitfürdasSchützedesTeilnetz1'Ladepfad':
0 : HV_Off
1 : HV_On (Schütz geschlossen)
2 : reserviert
3 : Init   (CAN-Initialisierung)";
CM_ SG_ 1283 HVK_Vorladung_aktiv "Systeminformation,dassaktivvorgeladenwird";
CM_ SG_ 1283 HVK_BMS_Sollmodus "AngeforderterSollmodusderHV-Batterie:
0 : HV_Off
1 : HV_On (HS geschlossen)
2 : nicht belegbar
3 : AC-Laden_erw (HS +AC_2-Schütze geschlossen)
4 : AC-";
CM_ SG_ 1283 HVK_DCDC_Sollmodus "angeforderteSoll-BetriebsartdesDC/DC-Wandlers:
0: Standby; Kommunikation aktiv
1: Zwischenkreis des HV-Netzes wird vorgeladen; HV-Netz wird aktiviert und darf nicht
belastet werden.
2: Tiefsetzen (HV --> BN 14,4V)
Sollwertvorgabe projek";
CM_ SG_ 1283 HVK_EKK_Sollmodus "SollmoduselektrischerKlimakompressor";
CM_ SG_ 1283 HVK_HVPTC_Sollmodus "SollmodusHV-PTC
0 : keine Freigabe
1 : Freigabe
2 : Freigabe_ausgesetzt
3 : nicht belegbar
4 : nicht belegbar
5 : nicht belegbar
6 : nicht belegbar
7 : Init   (CAN-Initialisierung)

Info: 'nicht belegbar' d.h. Sollmodus nicht relevant für HV";
CM_ SG_ 1283 HVK_HVLM_Sollmodus "AngeforderterSollmodusdesLademanagers.";
CM_ SG_ 1283 HVK_HV_Netz_Warnungen "AnforderungWarnung/FehlerHV-SystemimKombi
0: Keine Warnung/Init
1:Anforderung_Anzeige_Warnung_HV-Netz (gelbes Symbol)
2:Anforderung_Anzeige_Fehler_HV-Netz (rotes Symbol)
3:Anforderung_Anzeige_Warnung_Kein_Wiederstart_möglich";
CM_ SG_ 1283 HV_Bordnetz_aktiv "SignalisierteinaktivesHochvoltbordnetz.FürdieBelastbarkeitdesHV-NetzesmüssenStrom-bzw.Leistungsgrenzeneingehaltenwerden";
CM_ SG_ 1283 HV_Bordnetz_Fehler "StatusobimHV-NetzeinFehlerdetektiertwurde.";
CM_ SG_ 1283 HVK_Gesamtst_Spgfreiheit "StatusdesHV-Systems";
CM_ SG_ 1283 HVK_AktiveEntladung_Anf "AnforderungzumaktivenEntladendesHV-Netzes,währendderAbschaltungdesHV-Netz.";
CM_ SG_ 1283 HVK_HVEM_Freigabe "DerHVKgibtdasHVEMfrei,umdasHV-NetzunterEinhaltungvonLeistungsgrenzeninAnspruchzunehmen.";
CM_ SG_ 1283 HVK_Notentladung_Anf "AufforderungzurschnellstmöglichenEntladungdesHV-NetzesaufgrundHV-Sicherheit(Crash-Erkennung/AbrissPilotlinie/…).";
CM_ SG_ 1283 HVK_Iso_Messung_Start "AnforderungandieisolationswiderstandsüberwachendenHV-KomponentenzurDurchführungderIsolations-Widerstandsmessung.";
CM_ SG_ 1283 HVK_Ladebereit "InformationandasLademanagement,dassdasHV-SystemausSichtdesHVKsbereitgestelltwerdenkann.";
CM_ SG_ 1283 HVK_PPulsFreigabe "Prüfpuls-FreigabeseitensHochvoltkoordinator";
CM_ SG_ 2463978813 HVL_01_CRC "FürMLB:
Berechnung siehe Lastenheft 'Kommunikationsabsicherung für FlexRay und CAN'
Ab MQB und MLBevo:
Berechnung siehe Lastenheft 'End-to-End Kommunikationsabsicherung'

Endwerte siehe Begleitdokument 'S-PDU Kennungsfolgen'";
CM_ SG_ 2463978813 HVL_01_BZ "4bitBotschaftszähler,wirdmitjederSendebotschaftinkrementiert";
CM_ SG_ 2463978813 HVL_Steckerstatus "StelltdenStatusdesLadesteckershinsichtlichPräsenzzurVerfügung";
CM_ SG_ 2463978813 HVL_LadeAnforderung "FuSi-AbgesicherteLadeanforderungandenHVK";
CM_ SG_ 626 HVLM_Anforderung_HMS "AnforderungzurVerriegelungdesTriebstrangs";
CM_ SG_ 626 HVLM_Parken_beibehalten_HMS "AnforderungdenTriebstrangverriegeltzuhalten";
CM_ SG_ 626 HVLM_WakeUpZaehlerResetAnf "0=keine_Anforderung
1 = Reset_Zaehler";
CM_ SG_ 626 HVLM_AWC_VerbautStatus "VerbausignalisierungvomHVLMderoptionalenKomponenteAWC";
CM_ SG_ 626 HVLM_Steckerstatus_A "GibtdenSteckerstatusausderLadedoseAan";
CM_ SG_ 626 HVLM_Steckerstatus_B "GibtdenSteckerstatusausderLadedoseBan";
CM_ SG_ 626 HVLM_Start_Pulserkennung "StartanforderungfürdiePulserkennung";
CM_ SG_ 626 HVLM_ZustandLadeablauf "ZustandimAblaufdesLadevorganges
0 = Init
1 = Standby_Ladevorbedingungen erfuellt
2 = Standby_Ladevorbedingungen_nicht_erfuellt
3 = Fehler
4 = Laden_starten
5 = Laden_beenden
6 = HVBatterie_Laden
7 = HVBatterie_Entladen
8 = Erhaltungsladen";
CM_ SG_ 626 HVLM_DC_Aufstartmodus "AufstartmoduszumAktivierendesHV-ModusfürDC-Laden
0= keine_Anforderung
1= Angleich_Fahrzeug (Fahrzeug schaltet auf DC-Spannung der Ladesäule auf)
2= Angleich_LS_1 (Ladesäule schaltet auf DC-Spannung des Fahrzeuges auf Methode 1)
3= Angleich_LS_2 ";
CM_ SG_ 626 HVLM_Ladeszenario "ÜberdiesesSignalwirddaseinzustellendeSzenariofürdieVisualisierunggesendet.";
CM_ SG_ 626 HVLM_Ladevorgang_Anf "ArtderangefordertenLadeart
0 = Laden_nicht_angefordert
1 = AC_Laden_Angefordert
2 = DC_Laden_Angefordert
3 = AC_und_DC_Angefordert
4 = Induktiv_Laden_Angef
5 = AC_und_Induktiv_Angef
6 = DC_und_Induktiv_Angef
7 = AC_DC_und_Induktiv_Angef";
CM_ SG_ 626 HVLM_Intensitaet "ÜberdiesesSignalwirdeineInformationüberdieBeleuchtungsintensitätgesendet.";
CM_ SG_ 626 HVLM_Laden_ISO_Messung_Anf "MessungdesIsolationswiderstandesdesLadesystems(FzgundLadesäule)währenddesLadevorgangesdurchdasFahrzeug
0= Anforderung
1= keine_Anforderung";
CM_ SG_ 268 ImoCord_Auth_Aufforderung_WFS "WFS-Anforderung";
CM_ SG_ 2527679583 Parken_Seitenspiegel_Anf "AnforderungfürSeitenspiegelan-oderabklappenbeimPiloPa";
CM_ SG_ 2527679583 Parken_ZV_Schliessen "AnforderungfürZentralverriegelungverriegelnodersafenbeimPiloPa";
CM_ SG_ 2527679583 Parken_aktives_System_02 "zeigtanwelchesparkendesSystemaktivist";
CM_ SG_ 2527679583 Parken_ZR_Sondermodus_Anf "AnforderungSondermodus,umbeim„pilotiertenParken“spezielleFunktionsanpassungenimInfotainment-Bereichzuermöglichen(u.a.schnellererStartup,AbschaltungBT)";
CM_ SG_ 2527679583 Parken_Schluesselsuche_Anf "AnsteuerungderSchlüsselsuchefürdaspilotierteParken.";
CM_ SG_ 2527679583 Parken_FFB_LED_Anf "StatusinformationdesPilotiertenParkensfürdieAnsteuerungderLEDaufderFunkfernbedienung.";
CM_ SG_ 2527679583 Parken_Wegfahrsperren_Anf "AnsteuerungderWegfahrsperrenKomponentenfürdaspilotierteParken.";
CM_ SG_ 2527679583 Parken_Aktivierungslicht_Anf "AnforderungdesAktivierungslichtsnacherfolgreicherAktivierungshandlungseitensPilotiertemParken.";
CM_ SG_ 2527679583 Parken_Fahrtrichtungslicht_Anf "AnforderungseitensPilotiertemParkenfürdieAnzeigederinitialenFahrtrichtungnachSystemaktivierung.";
CM_ SG_ 2527679583 Parken_Lichtnachlauf_Anf "AnforderungdesLichtnachlaufsbeimBCM1(analogVerlassenskonzept)fürdasPilotierteParken.";
CM_ SG_ 2527679583 Parken_Fahrerhinweise_Anf "AnforderungzurerneutenLampenaufprüfungundAnzeigevonWarnhinweisennacheinempilotiertenAusparkvorgang.";
CM_ SG_ 2527679583 Parken_Bestaetigungsblinken_Anf "AnforderungseitensPilotiertemParkenfüreinErfolgsblinkennachdemErreichenderZielpositionbzw.füreinAbbruchsblinkenbeiEintreteneinerAbbruchsbedingung.";
CM_ SG_ 2527679583 Parken_Fahrbereitschaftlicht_Anf "AnforderungdesFahrbereitschaftslichts";
CM_ SG_ 2527679583 Parken_Lichtsteuerung_Anf "AnforderungzumSetzendesLichtmodusdesFahrzeugesvonderParkfunktion";
CM_ SG_ 2527679583 IPA_Anf_Meldungen "AnforderungderMeldungen:
0 - Keine Meldung
1-127 IPA niederprio. Meldungen
128-191 IPA hochprio. Meldungen
192-207 TPA Meldungen
208-255 Vorhalt";
CM_ SG_ 1813 ISO_Airbag_01_Req_Data "DiagnoseRequestAirbagsteuergeraet";
CM_ SG_ 1919 ISO_Airbag_01_Resp_Data "DiagnoseResponseAirbagsteuergeraet";
CM_ SG_ 1792 ISO_ALL_01_Req_Data "FunktionalerRequestALL";
CM_ SG_ 2621440021 ISOx_Airbag_01_Req_FD_Data "DiagnoseRequest";
CM_ SG_ 2621571093 ISOx_Airbag_01_Resp_FD_Data "DiagnoseResponse";
CM_ SG_ 2549874812 ISO_EMotor_01_Req_Data "DiagnoseRequestLeistungselektronikE-Maschine1";
CM_ SG_ 2621440124 ISOx_EMotor_01_Req_FD_Data "DiagnoseRequest";
CM_ SG_ 2550005884 ISO_EMotor_01_Resp_Data "DiagnoseResponseLeistungselektronikE-Maschine1";
CM_ SG_ 2621571196 ISOx_EMotor_01_Resp_FD_Data "DiagnoseResponse";
CM_ SG_ 2549874872 ISO_EMotor_02_Req_Data "DiagnoseRequestLeistungselektronikE-Maschine2";
CM_ SG_ 2621440184 ISOx_EMotor_02_Req_FD_Data "DiagnoseRequest";
CM_ SG_ 2550005944 ISO_EMotor_02_Resp_Data "DiagnoseResponseLeistungselektronikE-Maschine2";
CM_ SG_ 2621571256 ISOx_EMotor_02_Resp_FD_Data "DiagnoseResponse";
CM_ SG_ 2621505536 ISOx_Funkt_Req_All_FD_Data "VWAGDiagnosefunktionalerRequestaufCANFD";
CM_ SG_ 2549874806 ISOx_MO_01_Req_Data "DiagnoseRequest";
CM_ SG_ 2621440118 ISOx_MO_01_Req_FD_Data "DiagnoseRequest";
CM_ SG_ 2550005878 ISOx_MO_01_Resp_Data "DiagnoseResponse";
CM_ SG_ 2621571190 ISOx_MO_01_Resp_FD_Data "DiagnoseResponse";
CM_ SG_ 2527679684 Kamera_ASM_Ereignis "DiesesSignaldefiniert,welcheFunktionundwelcheArtvonAktivitätdasSendenderBotschaftandenAssistenzsystemmonitorASMveranlassthat.";
CM_ SG_ 2527679684 Kamera_ASM_Zeitstempel "DiesesSignalermöglichtdiezeitlicheZuordnungdervonACCandenAssistenzsystemmonitorASMgesendetenStatusbotschaften.";
CM_ SG_ 2527679684 Kamera_ASM_Data_1 "DiesesSignalwirdvonderFrontkamerabefülltundandenAssistenzsystemmonitorASMgesendet.";
CM_ SG_ 2527679684 Kamera_ASM_Data_2 "DiesesSignalwirdvonderFrontkamerabefülltundandenAssistenzsystemmonitorASMgesendet.";
CM_ SG_ 2527679684 Kamera_ASM_Data_3 "DiesesSignalwirdvonderFrontkamerabefülltundandenAssistenzsystemmonitorASMgesendet.";
CM_ SG_ 2527679684 Kamera_ASM_Data_4 "DiesesSignalwirdvonderFrontkamerabefülltundandenAssistenzsystemmonitorASMgesendet.";
CM_ SG_ 2527679684 Kamera_ASM_Data_5 "DiesesSignalwirdvonderFrontkamerabefülltundandenAssistenzsystemmonitorASMgesendet.";
CM_ SG_ 2527679684 Kamera_ASM_Data_6 "DiesesSignalwirdvonderFrontkamerabefülltundandenAssistenzsystemmonitorASMgesendet.";
CM_ SG_ 960 Klemmen_Status_01_CRC "FürMLB:
'Berechnung siehe Lastenheft 'Kommunikationsabsicherung für FlexRay und CAN''

Ab MQB und MLBevo:
'Berechnung siehe Lastenheft 'End-to-End Kommunikationsabsicherung''

Endwerte siehe Begleitdokument 'S-PDU Kennungsfolgen'";
CM_ SG_ 960 Klemmen_Status_01_BZ "4bitBotschaftszaehler;wirdinjederSendebotschaftinkrementiert";
CM_ SG_ 960 RSt_Fahrerhinweise "ÜberdasSignalfordertdasBCMFahrerhinweiseimKombifürdieFunktionRemoteStartan.";
CM_ SG_ 960 ZAS_Kl_S "KlemmeS:S-Kontakt(Schluesselsteckt)
";
CM_ SG_ 960 ZAS_Kl_15 "Klemme15:Zuendung(SW-Kl.15)
";
CM_ SG_ 960 ZAS_Kl_X "Klemme75
";
CM_ SG_ 960 ZAS_Kl_50_Startanforderung "Klemme50:StartwunschFahrer
";
CM_ SG_ 960 BCM_Remotestart_Betrieb "ZeigtdenStatusdesRemoteStartsan,d.h.KL15_RStistaktiviertundderMotorlaufistimRSt-Betriebaktiv.";
CM_ SG_ 960 ZAS_Kl_Infotainment "SeparateKlemmeninformationfürdasInfotainment.SignalentsprichtimwesentlicheneinerKlemmeSInformation,kannaberübereinenVor-bzw.NachlaufzuKlemmeSverfügen.
Ein konkreter Anwendungsfall für einen Nachlauf ist die Abschaltung der Klemme";
CM_ SG_ 960 BCM_Remotestart_KL15_Anf "ZeigtdenStatusderAktivierungderKL15_RSTdurchdasBCMan.";
CM_ SG_ 960 BCM_Remotestart_MO_Start "NachdemdasBCMdieRemotestartMSGFreigabesichererkannthat,fordertdasBCMwiederumüberdiesesSignalvomMSGeinenMotorstartdurchzuführen.";
CM_ SG_ 960 KST_Warn_P1_ZST_def "KombiPrioWarnungKlemmensteuerung
Zündschloß defekt, Service aufsuchen!";
CM_ SG_ 960 KST_Warn_P2_ZST_def "KombiPrioWarnungKlemmensteuerung
Zündschloß defekt!
";
CM_ SG_ 960 KST_Fahrerhinweis_1 "SignalisierungFahrerhinweis1derKlemmensteuerungandasKombi";
CM_ SG_ 960 KST_Fahrerhinweis_2 "SignalisierungFahrerhinweis2derKlemmensteuerungandasKombi";
CM_ SG_ 960 BCM_Ausparken_Betrieb "AnforderungzurerneutenLampenaufprüfungundAnzeigevonWarnhinweisennacheinempilotiertenAusparkvorgang(Trigger:fallendeFlanke)";
CM_ SG_ 960 KST_Fahrerhinweis_4 "SignalisierungFahrerhinweis4derKlemmensteuerungandasKombi";
CM_ SG_ 960 KST_Fahrerhinweis_5 "AnzeigesignalfürRemoteStart";
CM_ SG_ 960 KST_Fahrerhinweis_6 "SignalaktiviertdieKombi-Anzeigeinstrumente(Drehzahl,Tankinhalt,Kühlmitteltemperatur)währendaktiviertemRemoteStart-Betrieb";
CM_ SG_ 2463978753 KST_WFS_Fahrfreigabe_Anforderung "HiermitwirddenWegfahrsperren-TeilnehmernsignalisiertwelcheArtderFahrfreigabevonderanforderndenSonderfunktionbenötigtwird";
CM_ SG_ 2463978753 KST_Sonderzustand_Status "Hiermitwirdsignalisiert,dasseineSonderfunktionaktivistunddieKlemme15durchdieseangefordertwurdebzw.einÜbergangvonSonderfunktionenstattfindet";
CM_ SG_ 2463978753 KST_Sonderzustand_Anforderung "Hiermitwirddieaktivebzw.aktuellangeforderte(s.KST_Sonderzustand_Status)Sonderfunktionidentifiziert";
CM_ SG_ 1420 Klemmen_Steuerung_01_CRC "AbMQBundMLBevo:
'Berechnung siehe Lastenheft 'End-to-End Kommunikationsabsicherung''

Endwerte siehe Begleitdokument 'S-PDU Kennungsfolgen'";
CM_ SG_ 1420 Klemmen_Steuerung_01_BZ "4bitBotschaftszaehler;wirdinjederSendebotschaftinkrementiert";
CM_ SG_ 1420 KST_Anf_Klemme_15 "AnforderungderKlemme15andasBCM.SignalwirdzurPlausibilisierungparallelzumKlemmensignalaufdemCANübertragen.";
CM_ SG_ 1420 KST_Anf_Klemme_50 "AnforderungderKlemme50andasMSG.SignalwirdzurPlausibilisierungparallelzumKlemmensignalaufdemCANübertragen.";
CM_ SG_ 1420 KST_Anf_Klemme_S "AnforderungderKlemmeSandasBCM.SignalwirdzurPlausibilisierungparallelzumKlemmensignalaufdemCANübertragen.";
CM_ SG_ 1420 KST_Txt_Werkstatt "Text:'Klemmensteuerung!Werkstatt!'";
CM_ SG_ 1420 KST_Txt_P_Gang "Text:'WählhebelinPositionPbringen!'";
CM_ SG_ 1420 KST_Txt_Panikabschaltung "Text:'Notabschaltung''";
CM_ SG_ 1420 KST_Anf_Klemmenfreigabe_ELV "KlemmensteuerungfordertKlemmen-FreigabedurchdieELVan.";
CM_ SG_ 1420 KST_Txt_Komfortabschaltung "DiesesSignalfordertimKombidieMeldungan,diedenFahrerüberdieausgeführteautomatischeZündungsabschaltunginformiert.Signalwirdfür10sgesendet.";
CM_ SG_ 1420 KST_ZAT_betaetigt "Zündanlass-Taster(ZAT)betätigt";
CM_ SG_ 1420 KST_Unterdr_Zuendungsmeldung "BeiaktivemSignalsolldieZündungsmeldungdurchdasKombiunterdrücktwerden.";
CM_ SG_ 1420 KST_aut_Abschaltung_Zuendung "FallsbeieingeschalteterZündungdasAbblendlichtaktivwar,mussnachderautomatischenAbschaltungderKl_15&Kl_S,dassStandlichtaktivbleiben.DasSignalsendetdieInformation,dasseineautomatischeAbschaltungderKl_15undKl_Serfogt.";
CM_ SG_ 1420 KST_Anf_Klemmenfreigabe_WFS "AnforderungderFreigabevonderWFSzumEinschaltenvonKlemme15undKlemmeS";
CM_ SG_ 1420 KST_Anf_ZV_Verriegelung "NeuerVerriegelungstriggerfürdieZVnachderautomatischenKlemmenabschaltung.

Wird bei Kessyfahrzeugen mit StartStop ein aktiver Stop-Mode und Fahrerverlassen erkannt, startet ein 30 Sekunden-Timer. Innerhalb dieser 30 Sekunden hat der Fahrer die Mö";
CM_ SG_ 1420 Relais_VoKo_angesteuert "SignalzurRückmeldung,obdasRelaisfürdieVerbrauchervonerweiterteVoko/RemoteStartangesteuertwird.";
CM_ SG_ 1420 RSt_Anforderung_HMS "AnforderungvomRSt(RemoteStart)andasHMS(HaltemanagementSystem)";
CM_ SG_ 1420 KST_Zuendungswarnung "BeiaktivemSignalsolljenachgesetztemStatuseineWarnungdurchdasKombiausgegebenwerden";
CM_ SG_ 1420 KST_Fahrer_Info_Text "HinweisefürdenFahrerfürdieFahrzeugaktivierung/-deaktivierung";
CM_ SG_ 949 KL_Drehz_Anh "DrehzahlanhebungvomMotorangefordert

";
CM_ SG_ 949 KL_Vorwarn_Komp_ein "VorwarnungKompressorein;140msvorher;InformationfürMotorzumAufbauMomentenreserve";
CM_ SG_ 949 KL_AC_Schalter "ACSchalter
";
CM_ SG_ 949 KL_Vorwarn_Zuheizer_ein "VorwarnungZuheizerbetrieb
";
CM_ SG_ 949 KL_Zustand "BeschreibtdenZustanddesKlima-/Heizungsbedienteils.(OFF-ModeBedienteil)

PAG (MLB): Beschreibt den Zustand des Kompressors";
CM_ SG_ 949 KL_Kompressorkupplung_linear "SollwertzurAnsteuerungderKompressorkupplung";
CM_ SG_ 949 KL_Charisma_FahrPr "MLBevo:AktuellesFahrprogrammdesCharisma-Teilnehmers(sieheSystemlastenheftDriveSelect)
MQB: Istwert der Kennlinie (siehe Systemlastenheft MQB FPA)";
CM_ SG_ 949 KL_Charisma_Status "CharismaSystemstatusdesCharisma-Teilnehmers

Wert 0x3 ist nur für Fahrzeuge ab MQB relevant";
CM_ SG_ 949 KL_nachtr_Stopp_Anf "DiesesSignaldientdemMotoralsTrigger,dasseinnachträglicherMotorstoppeingeleitetwerdenkann,wennesdieBedingungendesStStKoordinatorsdieszulassen.";
CM_ SG_ 949 KL_T_Charge "SignalfürTastenbetätigungCharge-Taste(SOCIncreasing)";
CM_ SG_ 949 KL_Last_Kompr "AktuellesVerlustmomentderKlimaanlagebezogenaufdieKurbelwelle.WirdderKlimakompressornichtangesteuert,istdasSchleppmomentbezogenaufdieKurbelwellezusenden.";
CM_ SG_ 949 KL_Spannungs_Anf "ForderungdesKlima-SG'szurSpannungsanhebung.";
CM_ SG_ 949 KL_Thermomanagement "StufendesThermomanagement";
CM_ SG_ 949 KL_StartStopp_Info "Stopp-FreigabeundStart-AnforderungandenStart-Stopp-Koordinator";
CM_ SG_ 949 KL_Freilauf_Info "FreilaufInformationssignalvonKlimazumFreilaufkoordinator.KlimakannüberdiesesSignaldenFreilauffreigeben,verhindernbzw.explizitanfordern.";
CM_ SG_ 949 KL_Anf_KL "AnforderungKühlerlüfterderKlimaanlageinProzent

";
CM_ SG_ 949 KL_el_Zuheizer_Stufe "VorgabefürMotorsteuergeraetPTC-Stufe;imMLB-B8undMQBnurStufe0...3

";
CM_ SG_ 949 KL_Ausstattung_Klima "AusttattungsartderKlimabedienung";
CM_ SG_ 949 KL_Variante_Standheizung "IdentifikationderVariantederStandheizungenzurBerechnungderenergetischenZielzeit";
CM_ SG_ 949 KL_Anf_KV "AnforderungdesKühlerrollosin%";
CM_ SG_ 1511 KL_HV_Heizer_Strom "StromHV-HeizerfürReichweitenberechnung";
CM_ SG_ 1511 KL_EKK_Strom "EKKStromaufnahme(Hochvolt)";
CM_ SG_ 1511 KL_Pumpe_02_Soll "AnforderungKM-PumpeKlimakreislauf
Init (126dec)      = 0% Ansteuerung Pumpe
Fehler (127dec) = 100% Ansteuerung Pumpe";
CM_ SG_ 1511 KL_Ventil_03_Soll "AnforderungBatteriebypass-VentilimKlimakreislauf";
CM_ SG_ 1511 KL_Ventil_10_Status "StatusVentil_Wärmepump";
CM_ SG_ 1511 KL_Senderkennung "Gibtan,welchesSG(KlimaoderWP)dieBotschaftsendet";
CM_ SG_ 1511 WP_KJ_Soll "AnforderungderKuehlerjalousiestellungdurchWaermepumpenSG";
CM_ SG_ 1511 KL_Fehler_HV_EKK "FehlersignalbeiErkennungHVFehleramelektrischenKlimakompressorEKK
Sender: Klima MQB (evtl. Wärmepumpen SG MQB, OBD SG MQB)";
CM_ SG_ 1511 KL_Fehler_HV_Heizer "FehlersignalbeiErkennungHVFehleramHVHeizer
Sender: Klima MQB (evtl. Wärmepumpen SG MQB, OBD SG MQB)";
CM_ SG_ 1511 KL_BattKond_WaPu_DZMax "Maximal-DrehzahlderWasserpumpeimBatteriekühlkreislaufalsVorgabefürBMS";
CM_ SG_ 1511 WP_Kuehlerluefter_Anf "AnforderungKühlerlüfterdurchWärmepumpenSG";
CM_ SG_ 1511 KL_KM_ASV_01_Status "SchaltstatusKältemittelAbsperrventil
VW370/9 PHEV = Ventil vor Verdampfer";
CM_ SG_ 1511 KL_KM_ASV_02_Status "SchaltstatusKältemittelAbsperrventil
VW370/9 PHEV = Ventil vor Chiller";
CM_ SG_ 1511 KL_Vorwarn_HVHeizer_Leistung "VorwarnungderHeizerleistungfürdieStromregelung.Botschaft:Klima_EV_03,dadasSignalentwedervomKlimasteuergerätoderdemWärmepumpensteuergerätgesendetwerdensoll.";
CM_ SG_ 1511 KL_Status_EoHVL_EKK "ErkennungeineroffenenHV-Leitung(EoHVL).BewertetanhandeinerSpannungsgrenze.";
CM_ SG_ 1511 KL_Status_EoHVL_Heizer "ErkennungeineroffenenHV-Leitung(EoHVL).BewertetanhandeinerSpannungsgrenze.";
CM_ SG_ 1505 BCM1_Aussen_Temp_ungef "ungefilterterWertdesAussentemperatursensors
";
CM_ SG_ 1505 BCM_Heizungsabsperrventil_Status "DasSignalbeschreibtdenZustanddesHeizungsabsperrventils,welchesalsPortexpandervomBCM1elektrischangesteuertwird.";
CM_ SG_ 1505 BCM_Heizungspumpe_Status "DasSignalbeschreibtdenZustandderHeizungspumpe,welchealsPortexpandervomBCM1elektrischangesteuertwird.";
CM_ SG_ 1505 BCM_Kompressorkupplung_Status "DasSignalbeschreibtdenZustandderKlimakompressorkupplung,welchealsPortexpandervomBCM1elektrischangesteuertwird.";
CM_ SG_ 1505 BCM1_PTC_stufig_Status "StatusdesBCM1-HeizverbrauchersPTC(stufig)";
CM_ SG_ 1505 BCM1_FStatus_Aussentemp_ungef "FehlerstatusfürAussentemperatur(Kombianzeige)";
CM_ SG_ 1505 BCM1_Kompressorstrom_ist "IST-StromvomKlima-Kompressor";
CM_ SG_ 1505 BCM1_OBD_FStatus_ATemp "FehlerstatusUmgebungstemperatursensor(OBDrelevanterSensor)
";
CM_ SG_ 2549088277 Airbag_01_KompSchutz "FunktionseinschränkungaufgrundKomponentenschutzaktiv";
CM_ SG_ 2549088277 Airbag_01_Abschaltstufe "FunktionseinschränkungaufgrundaktiverAbschaltstufe";
CM_ SG_ 2549088277 Airbag_01_Transport_Mode "FunktionseinschränkungaufgrundaktivemTransportModeund/oderTransportSchutz";
CM_ SG_ 2549088277 Airbag_01_Nachlauftyp "AbgebildetwirddievonderHardwarevorgegebeneMöglichkeit,dieKommunikationnachKlemme15=AUSaufrechtzuerhalten.EswirdeinInit-Wertgesendet.
0 = Kommunikation nur bei KL15=EIN (kein Nachlauf, nicht weckfähig)
1 = Kommunikation nach KL15=AU";
CM_ SG_ 2549088277 NM_Airbag_01_Wakeup "enthältdieWeckursache;stehenmehrereWeckursachenparallelan,dannmussderkleinsteWertübertragenwerden";
CM_ SG_ 2549088277 KN_AB_DiagPfad "KennzeichnungderDiagnosefähigkeitdesBusInterfaceseinesSteuergerätes(Knoten)
Umfang LAH 80127

Bei Nutzung des Signal explizit pro angebundenem BusInterface zu setzen:
MQB auf A-CAN = 0 (aktiv)
MQB2020 auf A-CAN = 0 (aktiv)
MLBevo auf FlexRay ";
CM_ SG_ 2549088277 AB_KD_Fehler "BeigesetztemBitistmindestenseinKundendienstfehlereingetragen
";
CM_ SG_ 2549088380 EMotor_KompSchutz "FunktionseinschränkungaufgrundKomponentenschutzaktiv";
CM_ SG_ 2549088380 EMotor_01_Abschaltstufe "FunktionseinschränkungaufgrundaktiverAbschaltstufe";
CM_ SG_ 2549088380 EMotor_01_Transport_Mode "FunktionseinschränkungaufgrundaktivemTransportModeund/oderTransportSchutz";
CM_ SG_ 2549088380 EMotor_Nachlauftyp "AbgebildetwirddievonderHardwarevorgegebeneMöglichkeit,dieKommunikationnachKlemme15=AUSaufrechtzuerhalten.EswirdeinInit-Wertgesendet.
0 = Kommunikation nur bei KL15=EIN (kein Nachlauf, nicht weckfähig)
1 = Kommunikation nach KL15=AU";
CM_ SG_ 2549088380 NM_EMotor_01_Wakeup "enthältdieWeckursache;stehenmehrereWeckursachenparallelan,dannmussderkleinsteWertübertragenwerden";
CM_ SG_ 2549088380 KN_EM_HYB_DiagPfad "KennzeichnungderDiagnosefähigkeitdesBusInterfaceseinesSteuergerätes(Knoten)
Umfang LAH 80127

Bei Nutzung des Signal explizit pro angebundenem BusInterface zu setzen:
MQB AB auf A-CAN = 0 (aktiv)
MQB2020 auf A-CAN = 0 (aktiv)
MEB auf A-CAN = ";
CM_ SG_ 2549088380 EM_HYB_KD_Fehler "BeigesetztemBitistmindestenseinKundendienstfehlereingetragen";
CM_ SG_ 2549088272 Gateway_KompSchutz "FunktionseinschränkungaufgrundKomponentenschutzaktiv";
CM_ SG_ 2549088272 Gateway_Abschaltstufe "FunktionseinschränkungaufgrundaktiverAbschaltstufe";
CM_ SG_ 2549088272 Gateway_Transport_Mode "FunktionseinschränkungaufgrundaktivemTransportModeund/oderTransportSchutz";
CM_ SG_ 2549088272 Gateway_Nachlauftyp "AbgebildetwirddievonderHardwarevorgegebeneMöglichkeit,dieKommunikationnachKlemme15=AUSaufrechtzuerhalten.EswirdeinInit-Wertgesendet.
0 = Kommunikation nur bei KL15=EIN (kein Nachlauf, nicht weckfähig)
1 = Kommunikation nach KL15=AU";
CM_ SG_ 2549088272 NM_Gateway_Wakeup "enthältdieWeckursache;stehenmehrereWeckursachenparallelan,dannmussderkleinsteWertübertragenwerden";
CM_ SG_ 2549088272 KN_GW_DiagPfad "KennzeichnungderDiagnosefähigkeitdesBusInterfaceseinesSteuergerätes(Knoten)
Umfang LAH 80127

Bei Nutzung des Signal explizit pro angebundenem BusInterface zu setzen:
MQB auf Diag-CAN = 0 (aktiv)
MLBevo auf Diag-CAN = 0 (aktiv)
alle weiteren ";
CM_ SG_ 2549088272 GW_KD_Fehler "KundendienstfehlerbitGatewayzurAnzeigeeinesimGatewayabgelegtenFehlerspeichereintrages.";
CM_ SG_ 2549088440 LE2_KompSchutz "FunktionseinschränkungaufgrundKomponentenschutzaktiv";
CM_ SG_ 2549088440 LE2_Abschaltstufe "FunktionseinschränkungaufgrundaktiverAbschaltstufe";
CM_ SG_ 2549088440 LE2_Transport_Mode "FunktionseinschränkungaufgrundaktivemTransportModeund/oderTransportSchutz
";
CM_ SG_ 2549088440 LE2_Nachlauftyp "AbgebildetwirddievonderHardwarevorgegebeneMoeglichkeit,dieKommunikationnachKlemme15=AUSaufrechtzuerhalten.EswirdeinInit-Wertgesendet.
0 = Kommunikation nur bei KL15=EIN (kein Nachlauf, nicht weckfähig)
1 = Kommunikation nach KL15=A";
CM_ SG_ 2549088440 NM_LE2_Wakeup "enthältdieWeckursache;stehenmehrereWeckursachenparallelan,dannmussderkleinsteWertübertragenwerden";
CM_ SG_ 2549088440 KN_LE2_DiagPfad "KennzeichnungderDiagnosefähigkeitdesBusInterfaceseinesSteuergerätes(Knoten)
Umfang LAH 80127

Bei Nutzung des Signal explizit pro angebundenem BusInterface zu setzen:

MQB2020 auf A-CAN = 0 (aktiv)
MEB auf A-CAN = 0 (aktiv)";
CM_ SG_ 2549088440 LE2_KD_Fehler "StatusKundendienst-Fehlerspeicher";
CM_ SG_ 2549088374 Motor_KompSchutz "FunktionseinschränkungaufgrundKomponentenschutzaktiv";
CM_ SG_ 2549088374 MO_01_Abschaltstufe "FunktionseinschränkungaufgrundaktiverAbschaltstufe";
CM_ SG_ 2549088374 MO_01_Transport_Mode "FunktionseinschränkungaufgrundaktivemTransportModeund/oderTransportSchutz";
CM_ SG_ 2549088374 Motor_Nachlauftyp "AbgebildetwirddievonderHardwarevorgegebeneMöglichkeit,dieKommunikationnachKlemme15=AUSaufrechtzuerhalten.EswirdeinInit-Wertgesendet.
0 = Kommunikation nur bei KL15=EIN (kein Nachlauf, nicht weckfähig)
1 = Kommunikation nach KL15=AU";
CM_ SG_ 2549088374 KN_Motor_ECUKnockOutTimer "AusgabedesECUKnockOut-TimerinderKnotenbotschaft";
CM_ SG_ 2549088374 KN_Motor_BusKnockOut "AusgabedesBusKnockout-StatusinderKnotenbotschaft";
CM_ SG_ 2549088374 KN_Motor_BusKnockOutTimer "AusgabedesBusKnockOut-TimerinderKnotenbotschaft";
CM_ SG_ 2549088374 NM_MO_01_Wakeup "enthältdieWeckursache;stehenmehrereWeckursachenparallelan,dannmussderkleinsteWertübertragenwerden";
CM_ SG_ 2549088374 KN_Motor_ECUKnockOut "AusgabedesECUKnockout-StatusinderKnotenbotschaft";
CM_ SG_ 2549088374 KN_MO_DiagPfad "KennzeichnungderDiagnosefähigkeitdesBusInterfaceseinesSteuergerätes(Knoten)
Umfang LAH 80127

Bei Nutzung des Signal explizit pro angebundenem BusInterface zu setzen:

MLBevo auf FlexRay A-Kanal = 0 (aktiv)
MQB auf A-CAN = 0 (aktiv)
MQB2020 ";
CM_ SG_ 2549088374 MO_KD_Fehler "Kundendienstfehlerspeicherbit";
CM_ SG_ 982 Licht_hinten_01_BZ "überlaufender4bitBotschaftszaehler;wirdinjederSendebotschaftinkrementiert";
CM_ SG_ 982 LH_Aussenlicht_def "Aussenlichtkannnichtmehrkorrektangesteuertwerden(EEPROMCodierungkannnichtmehrausgelesenwerden)
";
CM_ SG_ 982 LH_Standlicht_H_aktiv "Standlichthinten
";
CM_ SG_ 982 LH_Parklicht_HL_aktiv "Parklichthintenlinks
";
CM_ SG_ 982 LH_Parklicht_HR_aktiv "Parklichthintenrechts
";
CM_ SG_ 982 LH_Bremslicht_H_aktiv "Bremslichthinten
";
CM_ SG_ 982 LH_Nebelschluss_aktiv "Nebelschlusslicht
";
CM_ SG_ 982 LH_Rueckfahrlicht_aktiv "Rueckfahrlicht
";
CM_ SG_ 982 LH_Blinker_HL_akt "Blinkerhintenlinks
";
CM_ SG_ 982 LH_Blinker_HR_akt "Blinkerhintenrechts
";
CM_ SG_ 982 LH_Blinker_li_def "FehlerstatusBlinkerhintenlinks
";
CM_ SG_ 982 LH_Bremsl_li_def "FehlerstatusBremslichthintenlinks(DetektionEinzelausfall)
";
CM_ SG_ 982 LH_Schlusslicht_li_def "FehlererkennungSchlusslichthintenlinks
";
CM_ SG_ 982 LH_Rueckf_li_def "FehlererkennungRückfahrlichthintenlinks
";
CM_ SG_ 982 LH_Nebel_li_def "FehlererkennungNebelschlusslichthintenlinks
";
CM_ SG_ 982 LH_Schluss_Brems_Nebel_li_def "Signalwirdgesetzt,wenneineUnterbrechungodereinKurzschlussamLampenausgangfürSchluss_Brems_Nebelschlusslichterkanntwird.";
CM_ SG_ 982 LH_Schluss_Brems_Nebel_re_def "Signalwirdgesetzt,wenneineUnterbrechungodereinKurzschlussamLampenausgangfürSchluss_Brems_Nebelschlusslichterkanntwird.";
CM_ SG_ 982 LH_Zusatzschlussl_def "mindestenseinZusatzschlusslichtinderHeckbeleuchtungdefekt.";
CM_ SG_ 982 LH_Schluss_Brems_li_def "KonfigurationSL+BRL+PLlinksundSL+BRLlinks
";
CM_ SG_ 982 LH_Schluss_Nebel_li_def "KonfigurationSL+NSLlinksoderSL+NSL+PLlinks
";
CM_ SG_ 982 LH_SL_BRL_BLK_li_def "KonfigurationSL+BRL+BLKlinksoderSL+BRL+BLK+PLlinks
";
CM_ SG_ 982 LH_Brems_Blk_li_def "KonfigurationBRL+BLKlinks
";
CM_ SG_ 982 LH_Diag_Status_re_def "AußenlichtDiagnoseSystemstörungrechts";
CM_ SG_ 982 LH_Diag_Status_li_def "AußenlichtDiagnose
Systemstörung links";
CM_ SG_ 982 LH_Diag_LED_li_def "Heckleuchtelinksdefekt";
CM_ SG_ 982 LH_Diag_LED_re_def "Heckleuchterechtsdefekt";
CM_ SG_ 982 LH_Blinker_re_def "FehlerstatusBlinkerhintenrechts
";
CM_ SG_ 982 LH_Bremsl_re_def "FehlerstatusBremslichthintenrechts(DetektionEinzelausfall)
";
CM_ SG_ 982 LH_Schlusslicht_re_def "FehlererkennungSchlusslichthintenrechts
";
CM_ SG_ 982 LH_Rueckf_re_def "FehlererkennungRückfahrlichthintenrechts
";
CM_ SG_ 982 LH_Nebel_re_def "FehlererkennungNebelschlusslichthintenrechts
";
CM_ SG_ 982 LH_Schluss_Brems_mi_def "FehlerstatusSchluss+Bremslichtmittedefekt(DetektionEinzelausfall)";
CM_ SG_ 982 LH_Schluss_Brems_re_def "KonfigurationSL+BRL+PLrechtsundSL+BRLrechts
";
CM_ SG_ 982 LH_Schluss_Nebel_re_def "KonfigurationSL+NSLrechtsoderSL+NSL+PLrechts
";
CM_ SG_ 982 LH_SL_BRL_BLK_re_def "KonfigurationSL+BRL+BLKrechtsoderSL+BRL+BLK+PLrechts
";
CM_ SG_ 982 LH_Brems_Blk_re_def "KonfigurationBRL+BLKrechts
";
CM_ SG_ 982 LH_Kennzl_def "FehlerstatusKennzeichenbeleuchtunghinten
";
CM_ SG_ 982 LH_3_Bremsl_def "Fehlerstatus3.Bremsleuchte
";
CM_ SG_ 982 LH_Nebel_mi_def "FehlererkennungNebelschlusslichthintenMitte


";
CM_ SG_ 982 LH_Rueckf_mi_def "FehlererkennungRückfahrlichtMitte
";
CM_ SG_ 982 LH_Schlusslicht_mi_def "FehlererkennungSchlusslichthintenMitte";
CM_ SG_ 982 LH_Bremsl_li_ges_def "FehlerstatusBremslichthintenlinks(DetektionTotalausfall)
";
CM_ SG_ 982 LH_Bremsl_re_ges_def "FehlerstatusBremslichthintenrechts(DetektionTotalausfall)";
CM_ SG_ 982 LH_Bremsl_mi_def "FehlerstatusBremslichtmitteoderGepäckraumklappe(DetektionEinzelausfall)";
CM_ SG_ 982 BRL_als_SHL "ZeigtanobdasBremslichtalsSchlusslichtimplementiertwird(VarianteNAR)";
CM_ SG_ 134 LWI_01_CRC "FürMLB:
'Berechnung siehe Lastenheft 'Kommunikationsabsicherung für FlexRay und CAN''

Ab MQB und MLBevo:
'Berechnung siehe Lastenheft 'End-to-End Kommunikationsabsicherung'

Endwerte siehe Begleitdokument 'S-PDU Kennungsfolgen'";
CM_ SG_ 134 LWI_QBit_Sub_Daten "EsgiltdieSignalspezifikationlautLAH";
CM_ SG_ 134 LWI_QBit_Lenkradwinkel "DasQBitwirdauchbeinichtabgeglichenemLenkradwinkelsensorgesetzt";
CM_ SG_ 134 LWI_Lenkradwinkel "Wertebereich=+/-800Grad
Auflösung = 0,1 Grad
ACHTUNG: spezifizierte Interne Auflösung des Sensors beträgt aber nur Schrittweite 0,5 Grad!

Hinweis:
MLB: Zusätzlich gestellte Winkel bei Dynamiklenkung beachten !
MQB: Nicht konstante Lenkübersetzu";
CM_ SG_ 134 LWI_VZ_Lenkradwinkel "VorzeichenLenkradwinkelgemässDIN7000";
CM_ SG_ 134 LWI_VZ_Lenkradw_Geschw "VorzeichenLenkradwinkelgeschwindigkeitgemässDIN7000";
CM_ SG_ 134 LWI_Lenkradw_Geschw "Wertebereich=+/-2500Grad/s
Auflösung = 5 Grad/s

Hinweis: Zusätzlich gestellte Winkel bei Dynamiklenkung beachten !";
CM_ SG_ 134 LWI_Sub_Daten "VerschlüsseltesDatenpaketvomSub-RechnerdesLWS,VerwendungnurdurchSCUundESP_ADS
Verwendung gemäß 'Sicherheitsanforderungen an Empfängersteuergeräte'

Im MLB gilt die Signalspezifikation: LAH 8K0953B
Im MLBevo gilt die Signalspezifikation LAH.";
CM_ SG_ 817 MFL_Toggle "WatchdogToggle-Bit";
CM_ SG_ 817 MFL_Lokalaktiv "ZeigtanobdasSGnachKlemme15AUSundnachentsprechenderMAXAktivzeitnochaktivwar";
CM_ SG_ 817 MFL_M_Taste "TasterfürUmschaltungAutomatik/manuellesSchalten(Tiptronic)";
CM_ SG_ 817 MFL_Paddle_Verbau "SignalisiertdenZustanddesTipp-Paddle-Verbaus";
CM_ SG_ 817 MFL_Tastencode_1 "BeschreibtdieFunktioneinerfestzugeordnetenTaste/WalzeaufdemMFL.BeiBetätigungändertsichderWertvon0x0aufdenjeweiligenTastencode.";
CM_ SG_ 817 MFL_Tastencode_2 "BeschreibtdieFunktioneinerfestzugeordnetenTaste/WalzeaufdemMFL.IstMFL_Tastencode_1wegenBetätigungeinerTaste/WalzebereitsmiteinemWertungleich0x0belegt,soändertsichbeiBetätigungeinerweiterenTaste/WalzederWertdiesesSignalsv";
CM_ SG_ 817 MFL_Eventcode_1 "SieheQ-LAHMFL-Protokoll";
CM_ SG_ 817 MFL_Eventcode_2 "SieheQ-LAHMFL-Protokoll";
CM_ SG_ 817 MFL_Variante "MarkenspezifischeVariantennummerdesMFL";
CM_ SG_ 817 MFL_Tip_Down "MFL-TiptronicTastenvomMFLfürGetriebe
0x0 = kein Tip_Down
0x1 = Tip_Down";
CM_ SG_ 817 MFL_Tip_Up "MFL-TiptronicTastenvomMFLfürGetriebe
0x0 = kein Tip_Up
0x1 = Tip_Up";
CM_ SG_ 817 MFL_SatModul_links_Err "SchalterTastermodullinksFehler";
CM_ SG_ 817 MFL_SatModul_rechts_Err "SchalterTastermodulrechtsFehler";
CM_ SG_ 817 MFL_LR_HZG_Status "StatusLenkradheizung";
CM_ SG_ 817 MFL_LR_HZG_Err "LenkradheizungFehler";
CM_ SG_ 817 MFL_Signalhorn "Signalhornnichtbetaetigt/betaetigt";
CM_ SG_ 817 MFL_Signalhorn_Err "SignalhornFehler";
CM_ SG_ 817 MFL_Tip_links_Err "TiptroniclinksFehler";
CM_ SG_ 817 MFL_Tip_rechts_Err "TiptronicrechtsFehler";
CM_ SG_ 817 MFL_Taste_links_Err "MFL_TastenblocklinksFehler";
CM_ SG_ 817 MFL_Taste_rechts_Err "MFL_TastenblockrechtsFehler";
CM_ SG_ 817 MFL_ECU_Err "MFL-µCFehler";
CM_ SG_ 817 MFL_Response_Err "sieheLIN2.0-Specification
(Darf nicht über ein Fehlergueltigkeitsbit abgesichtert werden!)";
CM_ SG_ 15 MO_SOPC "SwitchofPathCheckderMotorsteuerung

Achtung, reines CAN-Signal!";
CM_ SG_ 1600 MO_QBit_Ansaugluft_Temp "
";
CM_ SG_ 1600 MO_QBit_Kuehlmittel_Temp "
";
CM_ SG_ 1600 MO_KL15_Abschaltempfehlung "KessyAbschaltempfehlungnachVerlassendesFahrzeugs";
CM_ SG_ 1600 MO_HYB_Fehler_HV_Netz "ImHV-BordnetzistfehlerbedingtkeingeneratorischerBetriebmöglich.Das12V-BordnetzwirdüberdenDC/DC-WandleralleinausderTraktionsbatteriegespeist.UmdiesenZustandmöglichstlangeaufrechterhaltenzukönnen,solltenKomfort-Verbraucherabgesc";
CM_ SG_ 1600 MO_aktives_Getriebeheizen "InformationfürGetriebe,obeinVentilfürGetriebheizenangesteuertwerdenmuss";
CM_ SG_ 1600 MO_Absperrventil_oeffnen "SignalanKlima-SGdasAbsperrrventilanzusteuern.AbD4auch0x3Ventil_schließen.

Im MQB wird hier der Soll-Status des Absperrventils ausgegeben.
Achtung: bei z. B. klemmendem Ventil entspricht das Signal nicht dem tatsächlichen Status!";
CM_ SG_ 1600 MO_Ansaugluft_Temp "InFahrzeugenohneAußentemperaturvomKombikannausderAnsauglufttemperaturaufdieAußentemperaturgeschlossenwerden.BeimSDIistdasmiteinergewissenGenauigkeitgegeben.GenutztwirdesvomASG.";
CM_ SG_ 1600 MO_Oel_Temp "RealerMeßbereichca.-40..150Grad";
CM_ SG_ 1600 MO_Kuehlmittel_Temp "Kuehlmitteltemperatur";
CM_ SG_ 1600 MO_Hoeheninfo "KorrekturfaktorHöhe(1entspricht1013mbar)";
CM_ SG_ 1600 MO_Kennfeldk "DieKennfeldkühlungistindiesemFahrzeugverbautundhatkeinenSystemfehler";
CM_ SG_ 1600 MO_Versionsinfo_02 "VersioninformationvomMotorzurSteuerungbeiinkompatiblenKMatrix-Änderungbzw.EinführungvonneuenFunktionen,dieindenEmpfängernverriegeltwerdenmüssen.ZujedemEreigniswirdeinfixerZählerstandzugeordnet,umdemEmpfängerdiefunktionaleÄ";
CM_ SG_ 1600 MO_QBit_Hoeheninfo "QualifizierungsbitderHöheninfo.GesetztbeiErsatzwert,InitoderFehler.";
CM_ SG_ 1600 MO_Getriebe_kuehlen "AnforderungGetriebekühlventilansteuerung";
CM_ SG_ 1600 MO_Mom_Traegheit_02 "Massenträgheit(J)derMotorsbzw.derAntriebsmaschineninkgm².

Zur Berücksichtigung des E-Motor in Hybrid-Projekten:
in MLB-Projekten wird nur der J-Wert des Verbrennungsmotors und nicht der J-Wert des E-Motors berücksichtigt.
In MQB/MLBevo-Projek";
CM_ SG_ 1600 MO_Heizungspumpenansteuerung "AnforderungHeizungspumpenansteuerung
MQB und Hybrid: Status der Heizungsunterstützungspumpe am MSG
";
CM_ SG_ 1600 MO_SpannungsAnf "ForderungdesMotor-SGszurSpannungsanhebung";
CM_ SG_ 1600 MO_Nachlaufzeit_Heizungspumpe "NachlaufzeitfürHeizungspumpefürTurboladerschutz";
CM_ SG_ 167 Motor_11_CRC "FürMLB:
'Berechnung siehe Lastenheft 'Kommunikationsabsicherung für FlexRay und CAN''

Ab MQB und MLBevo:
'Berechnung siehe Lastenheft 'End-to-End Kommunikationsabsicherung''

Endwerte siehe Begleitdokument 'S-PDU Kennungsfolgen'";
CM_ SG_ 167 MO_Mom_Soll_Roh "EinheitenloserWert!FaktorinMO_Faktor_Momente_02inMotor_Code_01beachten!

Momentenanforderung aus Fahrpedal bzw. von ACC/GRA bzw. aus dem Leerlaufregler (quasistatischer Anteil) bzw. aus Rekuperationsanforderung; keine Begrenzungen, keine Filterun";
CM_ SG_ 167 MO_Mom_Ist_Summe "EinheitenloserWert!FaktorinMO_Faktor_Momente_02inMotor_Code_01beachten!

Ist-Moment als Summe aus Verbrennungsmotor und E-Motor (bei Hybrid-Konzepten) incl. allen Eingriffen und Korrekturen

In Fahrzeugen mit einer Antriebsachse bzw. mit mechan";
CM_ SG_ 167 MO_Mom_Traegheit_Summe "EinheitenloserWert!FaktorinMO_Faktor_Momente(CANV6.x)bzw.MO_Faktor_Momente_02(CANV7.x)inMotor_Code_01beachten!

Moment, das zur Beschleunigung der trägen Massen aufgewendet wird bzw. frei wird; Summen aus Anteilen für Verbrennungsmotor und ";
CM_ SG_ 167 MO_Mom_Soll_gefiltert "EinheitenloserWert!FaktorinMO_Faktor_Momente_02inMotor_Code_01beachten!

MO_Mom_Soll_Roh nach Fahrverhaltensfilter, begrenzt nach oben mit MO_Mom_Begr_dyn, Einrechnung der plausibilisierten Bremsen-Eingriffe; ohne Getriebe-Schalt-Eingriffe, ohne ";
CM_ SG_ 167 MO_Mom_Schub "EinheitenloserWert!FaktorinMO_Faktor_Momente_02inMotor_Code_01beachten!

Moment das sich einstellt, wenn der Fahrer 0% Fahrpedal gibt; bei konventionellen Projekten = alle Verluste (mechanische Reibung und sonstige Verluste) des Verbrennungsmotor";
CM_ SG_ 167 MO_Status_Normalbetrieb_01 "DasMotorsteuergerätsendetdasInformationsbit,wenndieInitialisierungsphasedesSteuergerätesabgeschlossenist.ZusätzlichmussdieKlemme15eingeschaltenseinundeineapplizierbareMindestdrehzahlschwelle(KennlinieinAbh.vonderKühlwassertempe";
CM_ SG_ 167 MO_erste_Ungenauschwelle "ZusätzlicheUngenauigkeit(zurGrundungenauigkeit).Motormomenteungenau>8%(kleinsteUngenauschwelle)
";
CM_ SG_ 167 MO_QBit_Motormomente "AUDID4:Zykluszeit:10ms(sieheZykluszeitschnell/CycletimeFast)

Ungenaue Momentenangaben, weil die Momente aus Ersatzwerten berechnet wurden (z.B. HFM ausgefallen). Qualifizierungsbit für die Motormomente.

Achtung:
Reduktion der Zykluszeit Moto";
CM_ SG_ 168 Motor_12_CRC "FürMLB:
'Berechnung siehe Lastenheft 'Kommunikationsabsicherung für FlexRay und CAN''

Ab MQB und MLBevo:
'Berechnung siehe Lastenheft 'End-to-End Kommunikationsabsicherung'

Endwerte siehe Begleitdokument 'S-PDU Kennungsfolgen'";
CM_ SG_ 168 MO_Mom_neg_verfuegbar "EinheitenloserWert!FaktorinMO_Faktor_Momente(CANV6.x)bzw.MO_Faktor_Momente_02(CANV7.x)inMotor_Code_01beachten!

Bei aktueller Drehzahl im nächsten Task (bei CAN-Übertragung z.B. 10ms) tatsächlich verfügbares negatives Moment (Summe aus Verl";
CM_ SG_ 168 MO_Mom_Begr_Fahr "EinheitenloserWert!FaktorinMO_Faktor_Momente(CANV6.x)bzw.MO_Faktor_Momente_02(CANV7.xundhöher)inMotor_Code_01beachten!

Bei aktueller Drehzahl quasistationär (nach ca. 3…5 s) max. mögliches Getriebeeingangsmoment (Summe aus Verbrennungsmo";
CM_ SG_ 168 MO_Mom_Begr_Schalt "EinheitenloserWert!FaktorinMO_Faktor_Momente(CANV6.x)bzw.MO_Faktor_Momente_02(CANV7.x/8.x)inMotor_Code_01beachten!

Bei aktueller Drehzahl kurzfristig (ca. 100..200 ms) für momentenerhöhende Getriebeeingriffe max. zur Verfügung stehendes Ge";
CM_ SG_ 168 MO_Momentenintegral_02 "100%entsprichtvolleVerfügbarkeitaktuellvorhanden.0%entsprichtIntegralbisLimitgefüllt,erhöhenderEingriffkannaktuellnichtberücksichtigtwerdenoderaufgrundeinesFehlersnichtverfügbar
";
CM_ SG_ 168 MO_QBit_Drehzahl_01 "AUDID4:Zykluszeit:10ms(sieheZykluszeitschnell/CycletimeFast)

Achtung:
Reduktion der Zykluszeit Motor_03 auf 10ms geplant.
Projektabhängig soll künftig mit 10ms gesendet werden.
Empfänger die in weiteren Konzern-Projekten eingesetzt werden müs";
CM_ SG_ 168 MO_Drehzahl_01 "ImFehlerfallwirddieMotordrehzahlüberdieNockenwellendrehzahlalsErsatzgrösseausgegeben

Bei Parallelhybrid: Getriebeeingangsdrehzahl (=E-Maschinen Drehzahl)

Hinweis:
Ehemaliger Fehlerwert 0xFFFF wird senderseitig nicht unterstützt.
Diesen";
CM_ SG_ 958 Motor_14_CRC "AbMQBundMLBevo:
'Berechnung siehe Lastenheft 'End-to-End Kommunikationsabsicherung'

Endwerte siehe Begleitdokument 'S-PDU Kennungsfolgen'";
CM_ SG_ 958 MO_StartStopp_Status "AktivitätsstatusStart/Stopp-Koordinator
HYBRID:
Wenn MO_Hybridfahrzeug = 1 gilt:
Signal bezieht sich nur auf den Verbrennungsmotor, nicht auf den Hybridantrieb
";
CM_ SG_ 958 MO_StartStopp_Wiederstart "MotorwiederstartdurchStart/Stopp-Koordinator
HYBRID:
Wenn MO_Hybridfahrzeug =1 gilt:
Warnung vor Spannungseinbruch beim Zustart des Verbrennungsmotors.
-nicht relevant, da derzeit kein Start über 12V-Starter geplant-
Dieses Signal wird nur vom Hyb";
CM_ SG_ 958 MO_StartStopp_Motorstopp "Motor-StoppdurchStart/Stopp-Koordinator
HYBRID:
Wenn MO_Hybridfahrzeug = 1 gilt:
Verbrennungsmotor durch Hybrid-Koordinator im MSG ausgeschaltet.
Die definierten Start/Stopp-Signale beziehen sich nur auf den Verbrennungsmotor!";
CM_ SG_ 958 MO_Freig_Reku "EmpfehlungdesMotor-SG'szurSpannungsabsenkung/-anhebungfürdenRekuperationsbetrieb";
CM_ SG_ 958 MO_Kl_75 "KlemmeX
";
CM_ SG_ 958 MO_Kl_50 "Klemme50:StartausführungdurchRitzelstarter

MLB: nicht von allen Motoren gesendet
MQB/MLBevo: gesendet von allen Motoren";
CM_ SG_ 958 MO_Gangposition "MLB:
Stellung des Wählhebels in der Schaltgasse des Handschaltgetriebes.
MLBevo:
Ausweitung der Bedienung auch auf Automatikgetrieb";
CM_ SG_ 958 MO_StartStopp_Fahrerwunsch "FahreraktivitätStart/Stop";
CM_ SG_ 958 MO_HYB_Fahrbereitschaft "Signalsteuertu.a.inderLenkhilfezusammenmitweiterenInformationendenModewechselinden'Drivemode'
Grüne Anzeige im Kombiinstrument zur Signalisierung der Bereitschaft des Hybridsystems.";
CM_ SG_ 958 MO_Ext_E_Fahrt_aktiv "Funktionsrückmeldungzumerw.E-Fahr-BetriebüberLampe/LEDimE-Mode-Taster";
CM_ SG_ 958 MO_Fahrer_bremst "RedundanteBremsinformationvomMotor.

MLB:
AUDI D4: Zykluszeit: 10ms (siehe Zykluszeit schnell/Cycletime Fast)
Im AUDI B8 wird in diesem Bit der Wert der ESP-CAN-Information 'ESP_Fahrer_bremst' ausgegeben.

Achtung:
Reduktion der Zykluszeit Motor";
CM_ SG_ 958 MO_QBit_Fahrer_bremst "MLB:
AUDI D4: Zykluszeit: 10ms (siehe Zykluszeit schnell/Cycletime Fast)

Achtung:
Reduktion der Zykluszeit Motor_03 auf 10ms geplant.
Projektabhängig soll künftig mit 10ms gesendet werden.
Empfänger die in weiteren Konzern-Projekten eingesetzt werd";
CM_ SG_ 958 MO_BLS "UngefiltertesRohsignaldesBremslichtschalters,nurwennHW-Eingangbestücktundausgewertetwird.BeiMotorenohnegenutztenHW-EingangwirdkeinErsatzwert(bspw.SW-SignalüberCAN)ausgegeben!
Bei AUDI muss das Signal wg. Bremslichtfunktion immer be";
CM_ SG_ 958 MO_Konsistenz_Bremsped "MLB:

AUDI D4: Zykluszeit: 10ms (siehe Zykluszeit schnell/Cycletime Fast)
Siehe 'Funktionsspezifikation Bremslichtinfo B8'

Achtung:
Reduktion der Zykluszeit Motor_03 auf 10ms geplant.
Projektabhängig soll künftig mit 10ms gesendet werden.
Empfäng";
CM_ SG_ 958 MO_Timeout_ESP "500msTimeoutaufBremsen-Botschaftist>=1malaufgelaufen,LöschendesBitsnachNeustart(KL15).

MLB:
AUDI D4: Zykluszeit: 10ms (siehe Zykluszeit schnell/Cycletime Fast)

Achtung:
Reduktion der Zykluszeit Motor_03 auf 10ms geplant.
Projektabh";
CM_ SG_ 958 MO_Klima_Eingr "EingriffedesMotorbeiderKlima";
CM_ SG_ 958 MO_Aussp_Anlass "DasSignalzeigtan,obdieWiederholstartsperreaktivist.D.h.eineAnsteuerungdesAnlasserswirdauchbeierfülltenStartvoraussetzungen(HS:Interlockbetätigtbzw.AT:P/NeingelegtundBremsebetätigt)nichterfolgen.";
CM_ SG_ 958 MO_Freig_Anlass "Bitwirdgesetzt,wennderMotorbeimAutomatikstartgestartetwerdendarf(Motorstillstand,Emissionsmaßnahmensinderfüllt).";
CM_ SG_ 958 MO_Kuppl_schalter "MLB:
Das Motorsteuergerät gibt die Information aus, ab wann der Kupplungsschalter durch das Motorsteuergerät als getreten gesehen wird
0x0: Schalter sagt betätigt (Ausgekuppelt)
0x1: Schalter sagt nicht betätigt (Eingekuppelt)

MQB:
Nur Handschalter";
CM_ SG_ 958 MO_Interlock "DasMotorsteuergerätgibtdieInformationaus,abwannderKupplungsschalterdurchdasMotorsteuergerätalsgetretengesehenwird.
Bei Systemen für Start Stopp muss das Interlocksignal für einen Start durch das MSG generiert werden, sobald der Schalthebe";
CM_ SG_ 958 MO_Motor_laeuft "DasMotorsteuergerätgibtdieInformationaus,abwannderMotorverbrennungsbedingtautarkläuftunddurchzuschaltbareNebenaggregatemechanischbelastbarist(z.B.durchGenerator,Klimakompressor,etc.).

Die 'Motor läuft' Information wird ausgegebe";
CM_ SG_ 958 MO_Kickdown "Esgilt:SignalspecMO_Kickdownv1.0";
CM_ SG_ 958 MO_QBit_KL_75 "Q-BitfürdasKL75SignalzurVermeidungderfehlerhaftenErkennungvonMotorstarts.
Wird auf 1 gesetzt, solange das Motorsteuergerät KL15 = AUS erkannt hat.";
CM_ SG_ 958 MO_EKlKomLeiRed "AnforderungandieKlimasteuerung,dieLeistungsaufnahmedesE-KompressorsbeischlechtemSOCundinbestimmtenFahrsituationenzubegrenzen.(DasbereitsbestehendeSignal'Klimakompressoraus'alsstetsumzusetzendeAnforderungbleibtunverändertbesteh";
CM_ SG_ 958 MO_Handshake_STH "Esgilt:SignalspecMO_Handshakev1.0

Handshake zwischen MSG und STH. Wenn das MSG die EKP aufgrund einer STH-Anforderung ansteuert und kein Fehlereintrag bzgl. EKP/KPE/NDR vorliegt, wird das Bit gesetzt.";
CM_ SG_ 958 MO_BKV_Unterdruckwarnung "ÜberdieUnterdruckwarnungsignalisiertdasMSGdemESP,dasskeinausreichenderUnterdruckfürdenBKVzurVerfügunggestelltwerdenkann.";
CM_ SG_ 958 MO_Freigabe_Segeln "FreigabebitdesSegelbetriebsimGetriebe.BedingtdurchbestimmteDiagnosenundAdaptionendesMSGs,dienurimSchubmöglichsind,darfnichtjedeSchubphasefüreinenSegelbetriebgenutztwerden.EineFreigabebleibtauchaußerhalbeinerSchubphasebes";
CM_ SG_ 958 MO_PTC_Status "Status-RückmeldungvomMSGzumaktuellenPTC-Status(stufigesPTC,RelaisamMSG).BeiAnsteuerungeinesstufigenPTCdurcheinanderesSGbeschreibtdasSignaldievomMSGfreigegebenePTC-Stufe.";
CM_ SG_ 958 MO_QBit_Gangposition "QualitätsbitzumSignalMO_Gangposition";
CM_ SG_ 958 MO_Signalquelle_Gangposition "SignalquelledesSignalsMO_Gangposition
0: Signalquelle Gangpositionssensor
1: Signalquelle Modellwert (v/n)";
CM_ SG_ 958 MO_Remotestart_Betrieb "DasMSGistfürdenRemotestart-Betriebbereit.NachEmpfangderMotorstartanforderungfürRSt-BetriebdurchBCMwirdderFahrzeugmotorgestartetundsolangederMotorläuft,bleibtdiesesBitaktiv.DiesesSignalistnurzurVerwendungdurchdasBCMzur";
CM_ SG_ 958 MO_Remotestart_moeglich "WennBitgesetzt,würdedasMSGbeientsprechenderAnforderungdurchdasBCMdenRemotestartbetriebeinleiten,d.h.dasMSGistremotestartfähigundesliegenaktuellkeinerelevantenFehleroderandereAbbruchgründevor.";
CM_ SG_ 958 MO_FMAus_aktiv "DasSignalgibtRückmeldungobFreilaufMotorausaktivist.Beleibtauch0km/h(unterhalbderStartStoppSchwelle)weiterhinaktiv.";
CM_ SG_ 958 MO_FMAus_Startvariante "StartvariantebeimMotorstartausderFreilauf-Motor-AUSPhase";
CM_ SG_ 958 MO_BMS_NV_Anf_stuetzen "GarantierteUnterstützungdesZusatzspeichersisterforderlich.ZusatzspeichermussandasVersorgungsneztangebundenwerden.";
CM_ SG_ 958 MO_Zylinderabschaltung "StatusZylinderabschaltungMotor";
CM_ SG_ 958 MO_HYB_VM_aktiv "0=VMotorwirdnichtaktivgehalten(nVM<n_minundkeineLL-Regelungaktiv)
1 = VMotor aktiv (ab der ersten Einspritzung; gilt auch für Schubbetrieb, wenn VMotor spätestens durch LLRegelung befeuert würde)
Verwendet zur Bestimmung des Ist-Zustandes";
CM_ SG_ 958 MO_StartVorauss_erfuellt "DientderFallunterscheidungbeiZAT-BetätigungimZustand'KL15ein'(beinichtgesetztemSignalfolgtKL15aus,beigesetztemSignalfolgtsetzenKL50-Anf.)

0: Signal nicht bedient
1: Voraussetzungen zur Antriebsstrangaktivierung / Startvoraussetzu";
CM_ SG_ 1631 TSK_Grundmasse "Fahrzeuggrundmasseinkg.DasSignaldientderAnpassungderSollbeschleunigungvomACC

Hinweis: Ehemaliger Fehlerwert 0x7F wird senderseitig nicht unterstützt. Diesen Wert aus Kompatibilitätsgründen nicht neu belegen!";
CM_ SG_ 1631 MO_SpannungsAnf_02 "ForderungdesMotor-SG'szurSpannungsanhebung";
CM_ SG_ 1631 MO_DPF_reg "RegenerationDiesel-Partikel-Filter";
CM_ SG_ 1631 MO_Heizstrom_EKAT "AktuelleGesamtstromaufnahmedesE-Katalysators";
CM_ SG_ 1631 MO_Heizstrom_SCR "AktuelleGesamtstromaufnahmederTank-,Fördermodul-undLeitungsheizungdesSCR-Systems";
CM_ SG_ 1631 MO_P_Generator_ungefiltert_Anf "BeiEmpfangderAnforderungsollderSenderBEM_P_Generatorungefiltertbefüllen.";
CM_ SG_ 1631 MO_Energieinhalt_BMS "RestenergieinhaltderTraktionsbatterie,beeinflusstdurchFahrstrategieundweiterenFaktorenderAntriebssteuerung.";
CM_ SG_ 1631 TSK_Fahrzeugmasse_02 "NeueDefinitionabD4
Fahrzeugmasse in kg. Das Signal dient der Anpassung der Sollbeschleunigung vom ACC


";
CM_ SG_ 1631 TSK_Steigung_02 "Steigungin%Berg.DasSignaldientderAnpassungderSollbeschleunigungvomACC

Positive Werte > bergau";
CM_ SG_ 1648 MO_max_Ladedruck "maximalmöglicherLadedruck(zurAnpassungdesAnzeigebereichsbeiabsoluterLadedruckanzeige)";
CM_ SG_ 1648 MO_ANC_Kennfeld_Anf "AnforderungANCKennfeldumschaltung";
CM_ SG_ 1648 MO_Bremslicht_Reku "Bremslicht(ggf.beiRekuperationdurchE-Motor)wirdangesteuert";
CM_ SG_ 1648 MO_StartStopp_PopUp "DasSignalzeigtan,obderStSt-StatusmittelsDeaktivierungstastergeändertwurde.EinWechselaufdieWerte01oder10löstimKombieinentsprechendesPopUpaus.BeieinemStatuswechseldurchandereSignalquellen(z.B.Charisma,fehlerbedingteAbschal";
CM_ SG_ 1648 MO1_Sperr_Info_WFS "WFS-Sperrinformation";
CM_ SG_ 1648 MO1_Freigabe_Info_WFS "WFS-Freigabeinformation";
CM_ SG_ 1648 MO_EPCL "DieAnforderungderEPC-LampevomMSGansKombisolldurchdasBus-SignalMO_EPCLgemäßfolgenderLogikerfolgen:
MO_EPCL = 0 dez -> EPC Lampe aus, kein Text
MO_EPCL = 1 dez -> gelbe EPC-Symbolik, Text „Antrieb: Störung! Bitte Service aufsuchen“
MO_EPC";
CM_ SG_ 1648 MO_Zylabsch_Texte_02 "ZAS-AnzeigefürdenFahrerimKombi
0: kein ZAS (generell keinerlei ZAS-Anzeigen)  (Init für nicht ZAS-Motor)
1: ZAS im Vollmotorbetrieb  (Init für ZAS-Motor)
2: ZAS im Abschaltbetrieb: 1 Zyl aktiv
3: ZAS im Abschaltbetrieb: 2 Zyl aktiv
4: ZAS im Abs";
CM_ SG_ 1648 MO_Fahrzeugtyp "UnterscheidetdieFahrzeugtypenbzgl.derAntriebsart";
CM_ SG_ 1648 MO_NMAX_Schaltanzeige "MaximaldrehzahlfürSchaltanzeige";
CM_ SG_ 1648 MO_Abstellzeit "AbstelldauernachletztemKL15aus

Hinweis:
Ehemaliger Fehlerwert 0xFF wird senderseitig nicht unterstützt.
Diesen Wert aus Kompatibilitätsgründen nicht neu belegen!";
CM_ SG_ 1648 MO_Abstellzeit_Status "StatusinformationzurAbstellzeit
0: Die dem Status zugeordnete Variable konnte noch nicht berechnet werden.
1: Die dem Status zugehörige Variable wurde korrekt berechnet.
2: Der Wert der zugehörigen Variablen ist nur ein Minimalwert.
3: Der Wert d";
CM_ SG_ 1648 MO1_Freigabe_Verfallsinfo_WFS "WFS-Freigabeverfallsinformation";
CM_ SG_ 1648 MO_Hybrid_StartStopp_LED "AnsteuerungderFunktions-LEDderHybridTastebzw.Start/StopDeaktivierungstaste.
Der Start/Stopp-Master (derzeit im MSG) (oder ein künftiger Hybrid-Master) soll die Ansteuerung senden.";
CM_ SG_ 1648 MO_Fehler_Zylabsch "FehlerstatusderFunktionZylinderabschaltung";
CM_ SG_ 1648 MO_Anzahl_Abgesch_Zyl "GibtdieAnzahlderabgeschaltetenZylinderan.InÜbergangszuständenwirdderZielbetriebszustandangezeigt.";
CM_ SG_ 1648 MO_Zylabsch_Texte "ZylinderabschaltungmodeinKombi,fuerZylinderabschaltung";
CM_ SG_ 1648 MO_Ethanol_BS_Texte "EthanolBrennstoff-TexteimKombi

0 = kein Text
1 = E85 Warm_Up
2 = FlexFuel Warnung 3.Stufe (Too cold for ethanol)
3 = Warmfahrempfehlung MQB / FlexFuel Warnung 1.Stufe (Refuel with gasoline)
4 = FlexFuel Warnung 2. Stufe (Refuel with gasoline)
5";
CM_ SG_ 1648 MO_Drehzahl_Warnung "WarnhinweiszumKombiimFalleinerfehlerbehaftetenDrehzahlbegrenzung";
CM_ SG_ 1648 MO_obere_Drehzahlgrenze "obereDrehzahlgrenzedesMotors";
CM_ SG_ 967 MO_Kuehlerluefter_MUX "MultiplexerfürdasSignal'MO_Kuehlerlüfter'";
CM_ SG_ 967 MO_Kuehlerluefter_1 "Ansteuertastverhaeltnis(PWM)derKuehlerluefterendstufe1";
CM_ SG_ 967 MO_Kuehlerluefter_2 "Ansteuertastverhaeltnis(PWM)derKuehlerluefterendstufe2";
CM_ SG_ 967 MO_EFLEX_Lampe "UmeinStartenmitE100zuermöglichen,wirdKraftstoffggf.vorgeheizt.DasSignaldientderAnzeigedesHeizungsstatus.

Heizung aus -> Lampe aus
Heizung ein -> Lampe ein
Heizung ein und Startversuch -> Lampe blinkend
Heizung nicht möglich -> Lampe";
CM_ SG_ 967 MO_KJS_nicht_bereit "DiesesSignalzeigeneinenFehlerderKühlerjalousiemitunbekannterStellungderLamellen.";
CM_ SG_ 967 MO_ITM_Warnung_Pumpe "Textanzeige:'Motorsofortabstellen,geschalteteWasserpumpedefekt/klemmt'";
CM_ SG_ 967 WIV_Anzeige_aktiv "Peilstabsanzeigefunktionaktiv";
CM_ SG_ 967 WIV_Oelmin_Warn "SignalgibtanwennderÖlstanddieMin-Schwelleunterschrittenhat";
CM_ SG_ 967 WIV_Sensorfehler "Ölstand/Öltemperatursensor(TOG)defekt";
CM_ SG_ 967 WIV_Schieflage "Fahrzeugstehtnichtwaagerecht,Messungungenau";
CM_ SG_ 967 WIV_Oelstand "8SegmentezurBalkenanzeigedesÖlstands";
CM_ SG_ 967 MO_Zustand_HWP "RückmeldungdesAnsteuerzustandderHauptwasserpumpeandasKlima-SG.
Der Zustand 'HWP fördert' wird übermittelt, wenn die Schaufeln der Hauptwasserpumpe frei drehen können und die Motordrehzahl und damit die Wasserpumpendrehzahl größer als Null ist. B";
CM_ SG_ 967 OLEV_Systemstoerung "SystemstörungimÖlsystem";
CM_ SG_ 967 MO_Oelwarnung_max "ÖlstandswarnungmitderAufforderungzumÖlwechsel.
Hintergrund: Bei Kraftstoffeintrag (B20) ins Öl verbleibt der RME-Anteil irreversibel im Öl.";
CM_ SG_ 967 WIV_Oelsystem_aktiv "Gesamtölsystemaktiv(entsprichtÖlsensorverbaut)unddasÖlstand-UntermenuimMMIaktiv";
CM_ SG_ 967 WIV_nicht_betriebswarm "Motornichtbetriebswarm,Messungungenau";
CM_ SG_ 967 WIV_Ueberfuell_Warn "ÖlstandhatdieÜberfüllschwelleüberschritten";
CM_ SG_ 967 WIV_laufender_Motor "MessungbeilaufendemMotornichtmöglich";
CM_ SG_ 967 MO_E_Warnungen "AnforderungvonWarnanzeigendesE-SystemsseparatfürHEV/BEVbzw.erweiterbarfürPHEV";
CM_ SG_ 967 MO_Text_Motorstart "AnzeigetextefürStart/StoppundMotor-Start
0xB Fehler_Kupplungsschalter nur für PAG-MLB";
CM_ SG_ 967 MO_E_Texte "AnforderungvonHinweistextendesE-SystemsseparatfürHEV/BEVbzw.erweiterbarfürPHEV";
CM_ SG_ 967 WIV_Oeldyn_avl "ÖlstandausdynamischerMessungvorhanden";
CM_ SG_ 967 MO_Text_Partikelfil_Reg "ÜberdiesesBitimKombiwirdeinKlartextanzeigeerzeugtwerden:'PartikelfilterbenötigtRegeneration'.
";
CM_ SG_ 967 OLEV_Oelstand_nicht_vorhanden "KeinaktuellerÖlstandvorhanden";
CM_ SG_ 967 WIV_Oelmenge "ÖlmengezwischenMinundMax";
CM_ SG_ 967 MO_Systemlampe "EGasSystemlampe(EPC)oderVorglühlampeimKombi,Kombisteuertimmergleiche
LED an, nur über Ziffernblatt wird die EPC von der Vorglühlampe differenziert";
CM_ SG_ 967 MO_OBD2_Lampe "OBDbzw.MIL-LampewirdvomMotorsteuergerätangesteuert,dieInformationimSignalGE_OBD_StatuswirdvomMotorsteuergerätandasKombiweitergereicht";
CM_ SG_ 967 MO_Heissleuchte "AnsteuerungderKühlwassertemperatur-Heißleuchte(SensornurnochamMotorsteuergerät):TemperaturschaltschwellenmitHysterese(beiVWD1/ColoradoKombiderzeitnochnichtgenutzt).";
CM_ SG_ 967 MO_Partikel_Lampe "Partikelfilter-Lampewirdeingeschaltet";
CM_ SG_ 967 MO_RedFahrleistung_Lampe "AnsteuerungderTurtle-ModeLampefürE-TraktionFahrzeuge";
CM_ SG_ 967 WIV_Oelstand_nicht_vorhanden "KeinaktuellerÖlstandvorhanden";
CM_ SG_ 967 WIV_nachfuellanzeige_ein "SteuertdasAufblendenderNachfüllanzeigeimKombi,nachKlemme15einundgeöffneterMotorhaube";
CM_ SG_ 967 WIV_Ueberfuell_deaktiv "UnterdrückungderWarnungimKombidiedurchSignalWIV_Ueberfuel_Warnausgelöstwird";
CM_ SG_ 967 WIV_Unterfuell_Warn "ÖlstandhatdieUnterfüllschwelleunterschritten";
CM_ SG_ 967 MO_Tankdeckel_Lampe "AnsteuerungTankdeckel-WarnlampeKombiinstrument(nurOttomotoren)z.Zt.VorhaltVW";
CM_ SG_ 967 MO_Text_Tankdeckelwarn "TextbitderTankdeckelwarnung,z.Zt.VorhaltVW";
CM_ SG_ 967 MO_Vorglueh_Lampe "VorglühlampeimKombi,KombisteuertimmergleicheLEDan.
Mit Einführung des Einheits-Kombis sind getrennte Signalwege für Vorglühlampe und EPCL notwendig.";
CM_ SG_ 967 WIV_Oeldr_Warn_Motor "LöstimKombiinstrumentdierotePrio1-Öldruckwarnung(inkl.3xBeep)aus.
nur MLB: die Warnauslösung erfolgt nur bei gleichzeitig gesetztem 'WIV_Enable_Oeldr_Motor'";
CM_ SG_ 967 MO_E_Mode "AnforderungderE-ModeStatusanzeige";
BA_DEF_ BO_ "DiagRequest" ENUM "No", "Yes";
BA_DEF_ BO_ "DiagResponse" ENUM "No", "Yes";
BA_DEF_ BO_ "DiagState" ENUM "No", "Yes";
BA_DEF_ BO_ "GenMsgChkConstant" HEX 0 4095;
BA_DEF_ BO_ "GenMsgCycleTime" INT 0 65535;
BA_DEF_ BO_ "GenMsgCycleTimeFast" INT 0 65535;
BA_DEF_ BO_ "GenMsgDelayTime" INT 0 100000;
BA_DEF_ BO_ "GenMsgILSupport" ENUM "No", "Yes";
BA_DEF_ BO_ "GenMsgNrOfRepetition" INT 0 100;
BA_DEF_ BO_ "GenMsgPDUConstants" STRING;
BA_DEF_ BO_ "GenMsgSendType" ENUM "Cyclic", "not_used", "not_used", "not_used", "not_used", "not_used", "not_used", "IfActive", "NoMsgSendType";
BA_DEF_ BO_ "GenMsgStartDelayTime" INT 0 100000;
BA_DEF_ BO_ "NmMessage" ENUM "No", "Yes";
BA_DEF_ BO_ "NmhMessage" ENUM "No", "Yes";
BA_DEF_ BO_ "MsgType" ENUM "Application", "NM", "NMH", "TP2.0", "ISO-TP", "BAP", "EID", "KS";
BA_DEF_ BO_ "VAGTP20_API" HEX 0 255;
BA_DEF_ BO_ "VAGTP20_DynConnection" ENUM "No", "Yes";
BA_DEF_ BO_ "VAGTP20_DynSetup" ENUM "No", "Yes";
BA_DEF_ BO_ "VAGTP20_StatConnection" ENUM "No", "Yes";
BA_DEF_ BO_ "CANFD_BRS" ENUM "0", "1";
BA_DEF_ BO_ "VFrameFormat" ENUM "StandardCAN", "ExtendedCAN", "reserved", "reserved", "reserved", "reserved", "reserved", "reserved", "reserved", "reserved", "reserved", "reserved", "reserved", "reserved", "StandardCAN_FD", "ExtendedCAN_FD";
BA_DEF_ SG_ "GenSigSendType" ENUM "Cyclic", "OnWrite", "OnWriteWithRepetition", "OnChange", "OnChangeWithRepetition", "IfActive", "IfActiveWithRepetition", "NoSigSendType", "OnChangeAndIfActive", "OnChangeAndIfActiveWithRepetition";
BA_DEF_ SG_ "GenSigFuncType" ENUM "NoFunction", "MsgCounter", "CRC-8", "XOR", "XOR-2", "DatedBit", "SW-Kl15", "CHK", "Constant", "Protocol", "CRC-8-SAE_J1850";
BA_DEF_ SG_ "GenSigSwitchedByIgnition" ENUM "No", "Yes";
BA_DEF_DEF_  "DiagRequest" "No";
BA_DEF_DEF_  "DiagResponse" "No";
BA_DEF_DEF_  "DiagState" "No";
BA_DEF_DEF_  "GenMsgChkConstant" 0;
BA_DEF_DEF_  "GenMsgCycleTime" 0;
BA_DEF_DEF_  "GenMsgCycleTimeFast" 0;
BA_DEF_DEF_  "GenMsgDelayTime" 0;
BA_DEF_DEF_  "GenMsgILSupport" "No";
BA_DEF_DEF_  "GenMsgNrOfRepetition" 0;
BA_DEF_DEF_  "GenMsgPDUConstants" "";
BA_DEF_DEF_  "GenMsgSendType" "NoMsgSendType";
BA_DEF_DEF_  "GenMsgStartDelayTime" 0;
BA_DEF_DEF_  "NmMessage" "No";
BA_DEF_DEF_  "NmhMessage" "No";
BA_DEF_DEF_  "MsgType" "Application";
BA_DEF_DEF_  "VAGTP20_API" 0;
BA_DEF_DEF_  "VAGTP20_DynConnection" "No";
BA_DEF_DEF_  "VAGTP20_DynSetup" "No";
BA_DEF_DEF_  "VAGTP20_StatConnection" "No";
BA_DEF_DEF_  "CANFD_BRS" "1";
BA_DEF_DEF_  "VFrameFormat" "StandardCAN";
BA_DEF_DEF_  "GenSigSendType" "NoSigSendType";
BA_DEF_DEF_  "GenSigFuncType" "NoFunction";
BA_DEF_DEF_  "GenSigSwitchedByIgnition" "Yes";
BA_ "GenMsgCycleTime" BO_ 299 30;
BA_ "GenMsgILSupport" BO_ 299 "Yes";
BA_ "GenMsgPDUConstants" BO_ 299 "0x6a,0x38,0xb4,0x27,0x22,0xef,0xe1,0xbb,0xf8,0x80,0x84,0x49,0xc7,0x9e,0x1e,0x2b";
BA_ "GenMsgSendType" BO_ 299 "Cyclic";
BA_ "VFrameFormat" BO_ 299 "StandardCAN_FD";
BA_ "GenMsgCycleTime" BO_ 1452 100;
BA_ "GenMsgILSupport" BO_ 1452 "Yes";
BA_ "GenMsgSendType" BO_ 1452 "Cyclic";
BA_ "VFrameFormat" BO_ 1452 "StandardCAN_FD";
BA_ "GenMsgCycleTime" BO_ 1385 500;
BA_ "GenMsgDelayTime" BO_ 1385 50;
BA_ "GenMsgILSupport" BO_ 1385 "Yes";
BA_ "GenMsgSendType" BO_ 1385 "Cyclic";
BA_ "VFrameFormat" BO_ 1385 "StandardCAN_FD";
BA_ "GenMsgCycleTime" BO_ 1283 100;
BA_ "GenMsgDelayTime" BO_ 1283 10;
BA_ "GenMsgILSupport" BO_ 1283 "Yes";
BA_ "GenMsgPDUConstants" BO_ 1283 "0xed,0xd6,0x96,0x63,0xa5,0x12,0xd5,0x9a,0x1e,0x0d,0x24,0xcd,0x8c,0xa6,0x2f,0x41";
BA_ "GenMsgSendType" BO_ 1283 "Cyclic";
BA_ "VFrameFormat" BO_ 1283 "StandardCAN_FD";
BA_ "GenMsgCycleTime" BO_ 2463978813 100;
BA_ "GenMsgDelayTime" BO_ 2463978813 10;
BA_ "GenMsgILSupport" BO_ 2463978813 "Yes";
BA_ "GenMsgPDUConstants" BO_ 2463978813 "0x1d,0x82,0x7b,0x79,0xa5,0xee,0x3a,0xb9,0xb7,0xf9,0xe4,0x67,0x7f,0x97,0x11,0xad";
BA_ "GenMsgSendType" BO_ 2463978813 "Cyclic";
BA_ "VFrameFormat" BO_ 2463978813 "ExtendedCAN_FD";
BA_ "GenMsgCycleTime" BO_ 626 100;
BA_ "GenMsgDelayTime" BO_ 626 10;
BA_ "GenMsgILSupport" BO_ 626 "Yes";
BA_ "GenMsgSendType" BO_ 626 "Cyclic";
BA_ "VFrameFormat" BO_ 626 "StandardCAN_FD";
BA_ "GenMsgILSupport" BO_ 268 "Yes";
BA_ "VFrameFormat" BO_ 268 "StandardCAN_FD";
BA_ "GenMsgILSupport" BO_ 23 "Yes";
BA_ "VFrameFormat" BO_ 23 "StandardCAN_FD";
BA_ "GenMsgILSupport" BO_ 25 "Yes";
BA_ "VFrameFormat" BO_ 25 "StandardCAN_FD";
BA_ "GenMsgCycleTime" BO_ 2527679583 1000;
BA_ "GenMsgCycleTimeFast" BO_ 2527679583 100;
BA_ "GenMsgDelayTime" BO_ 2527679583 50;
BA_ "GenMsgILSupport" BO_ 2527679583 "Yes";
BA_ "GenMsgNrOfRepetition" BO_ 2527679583 5;
BA_ "GenMsgSendType" BO_ 2527679583 "Cyclic";
BA_ "VFrameFormat" BO_ 2527679583 "ExtendedCAN_FD";
BA_ "DiagRequest" BO_ 1813 "Yes";
BA_ "MsgType" BO_ 1813 "ISO-TP";
BA_ "VFrameFormat" BO_ 1813 "StandardCAN_FD";
BA_ "DiagResponse" BO_ 1919 "Yes";
BA_ "MsgType" BO_ 1919 "ISO-TP";
BA_ "VFrameFormat" BO_ 1919 "StandardCAN_FD";
BA_ "DiagState" BO_ 1792 "Yes";
BA_ "MsgType" BO_ 1792 "ISO-TP";
BA_ "VFrameFormat" BO_ 1792 "StandardCAN_FD";
BA_ "DiagRequest" BO_ 2621440021 "Yes";
BA_ "MsgType" BO_ 2621440021 "ISO-TP";
BA_ "VFrameFormat" BO_ 2621440021 "ExtendedCAN_FD";
BA_ "DiagResponse" BO_ 2621571093 "Yes";
BA_ "MsgType" BO_ 2621571093 "ISO-TP";
BA_ "VFrameFormat" BO_ 2621571093 "ExtendedCAN_FD";
BA_ "DiagRequest" BO_ 2549874812 "Yes";
BA_ "MsgType" BO_ 2549874812 "ISO-TP";
BA_ "VFrameFormat" BO_ 2549874812 "ExtendedCAN_FD";
BA_ "DiagRequest" BO_ 2621440124 "Yes";
BA_ "MsgType" BO_ 2621440124 "ISO-TP";
BA_ "VFrameFormat" BO_ 2621440124 "ExtendedCAN_FD";
BA_ "DiagResponse" BO_ 2550005884 "Yes";
BA_ "MsgType" BO_ 2550005884 "ISO-TP";
BA_ "VFrameFormat" BO_ 2550005884 "ExtendedCAN_FD";
BA_ "DiagResponse" BO_ 2621571196 "Yes";
BA_ "MsgType" BO_ 2621571196 "ISO-TP";
BA_ "VFrameFormat" BO_ 2621571196 "ExtendedCAN_FD";
BA_ "DiagRequest" BO_ 2549874872 "Yes";
BA_ "MsgType" BO_ 2549874872 "ISO-TP";
BA_ "VFrameFormat" BO_ 2549874872 "ExtendedCAN_FD";
BA_ "DiagRequest" BO_ 2621440184 "Yes";
BA_ "MsgType" BO_ 2621440184 "ISO-TP";
BA_ "VFrameFormat" BO_ 2621440184 "ExtendedCAN_FD";
BA_ "DiagResponse" BO_ 2550005944 "Yes";
BA_ "MsgType" BO_ 2550005944 "ISO-TP";
BA_ "VFrameFormat" BO_ 2550005944 "ExtendedCAN_FD";
BA_ "DiagResponse" BO_ 2621571256 "Yes";
BA_ "MsgType" BO_ 2621571256 "ISO-TP";
BA_ "VFrameFormat" BO_ 2621571256 "ExtendedCAN_FD";
BA_ "DiagState" BO_ 2621505536 "Yes";
BA_ "MsgType" BO_ 2621505536 "ISO-TP";
BA_ "VFrameFormat" BO_ 2621505536 "ExtendedCAN_FD";
BA_ "DiagRequest" BO_ 2549874806 "Yes";
BA_ "MsgType" BO_ 2549874806 "ISO-TP";
BA_ "VFrameFormat" BO_ 2549874806 "ExtendedCAN_FD";
BA_ "DiagRequest" BO_ 2621440118 "Yes";
BA_ "MsgType" BO_ 2621440118 "ISO-TP";
BA_ "VFrameFormat" BO_ 2621440118 "ExtendedCAN_FD";
BA_ "DiagResponse" BO_ 2550005878 "Yes";
BA_ "MsgType" BO_ 2550005878 "ISO-TP";
BA_ "VFrameFormat" BO_ 2550005878 "ExtendedCAN_FD";
BA_ "DiagResponse" BO_ 2621571190 "Yes";
BA_ "MsgType" BO_ 2621571190 "ISO-TP";
BA_ "VFrameFormat" BO_ 2621571190 "ExtendedCAN_FD";
BA_ "GenMsgCycleTime" BO_ 2527679684 2000;
BA_ "GenMsgDelayTime" BO_ 2527679684 100;
BA_ "GenMsgILSupport" BO_ 2527679684 "Yes";
BA_ "GenMsgSendType" BO_ 2527679684 "Cyclic";
BA_ "VFrameFormat" BO_ 2527679684 "ExtendedCAN_FD";
BA_ "GenMsgChkConstant" BO_ 960 195;
BA_ "GenMsgCycleTime" BO_ 960 100;
BA_ "GenMsgDelayTime" BO_ 960 10;
BA_ "GenMsgILSupport" BO_ 960 "Yes";
BA_ "GenMsgPDUConstants" BO_ 960 "0xc3,0xc3,0xc3,0xc3,0xc3,0xc3,0xc3,0xc3,0xc3,0xc3,0xc3,0xc3,0xc3,0xc3,0xc3,0xc3";
BA_ "GenMsgSendType" BO_ 960 "Cyclic";
BA_ "VFrameFormat" BO_ 960 "StandardCAN_FD";
BA_ "GenMsgCycleTime" BO_ 2463978753 1000;
BA_ "GenMsgCycleTimeFast" BO_ 2463978753 100;
BA_ "GenMsgDelayTime" BO_ 2463978753 100;
BA_ "GenMsgILSupport" BO_ 2463978753 "Yes";
BA_ "GenMsgNrOfRepetition" BO_ 2463978753 5;
BA_ "GenMsgSendType" BO_ 2463978753 "Cyclic";
BA_ "VFrameFormat" BO_ 2463978753 "ExtendedCAN_FD";
BA_ "GenMsgCycleTime" BO_ 1420 1000;
BA_ "GenMsgCycleTimeFast" BO_ 1420 20;
BA_ "GenMsgDelayTime" BO_ 1420 10;
BA_ "GenMsgILSupport" BO_ 1420 "Yes";
BA_ "GenMsgNrOfRepetition" BO_ 1420 5;
BA_ "GenMsgPDUConstants" BO_ 1420 "0x9b,0xb5,0x9d,0x06,0x01,0xe7,0x8f,0xc1,0xd0,0x10,0x47,0xe9,0xd3,0xca,0x05,0xf0";
BA_ "GenMsgSendType" BO_ 1420 "Cyclic";
BA_ "VFrameFormat" BO_ 1420 "StandardCAN_FD";
BA_ "GenMsgCycleTime" BO_ 949 100;
BA_ "GenMsgILSupport" BO_ 949 "Yes";
BA_ "GenMsgSendType" BO_ 949 "Cyclic";
BA_ "VFrameFormat" BO_ 949 "StandardCAN_FD";
BA_ "GenMsgCycleTime" BO_ 1511 200;
BA_ "GenMsgILSupport" BO_ 1511 "Yes";
BA_ "GenMsgSendType" BO_ 1511 "Cyclic";
BA_ "VFrameFormat" BO_ 1511 "StandardCAN_FD";
BA_ "GenMsgCycleTime" BO_ 1505 200;
BA_ "GenMsgILSupport" BO_ 1505 "Yes";
BA_ "GenMsgSendType" BO_ 1505 "Cyclic";
BA_ "VFrameFormat" BO_ 1505 "StandardCAN_FD";
BA_ "GenMsgCycleTime" BO_ 2549088277 500;
BA_ "GenMsgILSupport" BO_ 2549088277 "Yes";
BA_ "GenMsgSendType" BO_ 2549088277 "Cyclic";
BA_ "CANFD_BRS" BO_ 2549088277 "0";
BA_ "VFrameFormat" BO_ 2549088277 "ExtendedCAN";
BA_ "GenMsgCycleTime" BO_ 2549088380 500;
BA_ "GenMsgILSupport" BO_ 2549088380 "Yes";
BA_ "GenMsgSendType" BO_ 2549088380 "Cyclic";
BA_ "VFrameFormat" BO_ 2549088380 "ExtendedCAN_FD";
BA_ "GenMsgCycleTime" BO_ 2549088272 500;
BA_ "GenMsgILSupport" BO_ 2549088272 "Yes";
BA_ "GenMsgSendType" BO_ 2549088272 "Cyclic";
BA_ "VFrameFormat" BO_ 2549088272 "ExtendedCAN_FD";
BA_ "GenMsgCycleTime" BO_ 2549088440 500;
BA_ "GenMsgILSupport" BO_ 2549088440 "Yes";
BA_ "GenMsgSendType" BO_ 2549088440 "Cyclic";
BA_ "VFrameFormat" BO_ 2549088440 "ExtendedCAN_FD";
BA_ "GenMsgCycleTime" BO_ 2549088374 500;
BA_ "GenMsgILSupport" BO_ 2549088374 "Yes";
BA_ "GenMsgSendType" BO_ 2549088374 "Cyclic";
BA_ "VFrameFormat" BO_ 2549088374 "ExtendedCAN_FD";
BA_ "MsgType" BO_ 2621440277 "ISO-TP";
BA_ "VFrameFormat" BO_ 2621440277 "ExtendedCAN_FD";
BA_ "MsgType" BO_ 2621571349 "ISO-TP";
BA_ "VFrameFormat" BO_ 2621571349 "ExtendedCAN_FD";
BA_ "GenMsgCycleTime" BO_ 982 100;
BA_ "GenMsgDelayTime" BO_ 982 20;
BA_ "GenMsgILSupport" BO_ 982 "Yes";
BA_ "GenMsgSendType" BO_ 982 "Cyclic";
BA_ "VFrameFormat" BO_ 982 "StandardCAN_FD";
BA_ "GenMsgChkConstant" BO_ 134 134;
BA_ "GenMsgCycleTime" BO_ 134 5;
BA_ "GenMsgILSupport" BO_ 134 "Yes";
BA_ "GenMsgPDUConstants" BO_ 134 "0x86,0x86,0x86,0x86,0x86,0x86,0x86,0x86,0x86,0x86,0x86,0x86,0x86,0x86,0x86,0x86";
BA_ "GenMsgSendType" BO_ 134 "Cyclic";
BA_ "VFrameFormat" BO_ 134 "StandardCAN_FD";
BA_ "GenMsgCycleTime" BO_ 817 500;
BA_ "GenMsgCycleTimeFast" BO_ 817 30;
BA_ "GenMsgILSupport" BO_ 817 "Yes";
BA_ "GenMsgSendType" BO_ 817 "Cyclic";
BA_ "VFrameFormat" BO_ 817 "StandardCAN_FD";
BA_ "GenMsgCycleTimeFast" BO_ 15 10;
BA_ "GenMsgILSupport" BO_ 15 "Yes";
BA_ "GenMsgSendType" BO_ 15 "IfActive";
BA_ "VFrameFormat" BO_ 15 "StandardCAN_FD";
BA_ "GenMsgCycleTime" BO_ 1600 500;
BA_ "GenMsgILSupport" BO_ 1600 "Yes";
BA_ "GenMsgSendType" BO_ 1600 "Cyclic";
BA_ "VFrameFormat" BO_ 1600 "StandardCAN_FD";
BA_ "GenMsgCycleTime" BO_ 167 10;
BA_ "GenMsgILSupport" BO_ 167 "Yes";
BA_ "GenMsgPDUConstants" BO_ 167 "0xd2,0x3d,0xcd,0x28,0x4c,0x14,0x22,0x4b,0x24,0xac,0xfa,0x55,0x66,0x80,0x0d,0x6c";
BA_ "GenMsgSendType" BO_ 167 "Cyclic";
BA_ "VFrameFormat" BO_ 167 "StandardCAN_FD";
BA_ "GenMsgCycleTime" BO_ 168 10;
BA_ "GenMsgILSupport" BO_ 168 "Yes";
BA_ "GenMsgPDUConstants" BO_ 168 "0x52,0x8c,0x50,0xee,0x4f,0xa6,0xcc,0xcf,0x7d,0x2f,0x98,0x6b,0x27,0x41,0x9f,0x93";
BA_ "GenMsgSendType" BO_ 168 "Cyclic";
BA_ "VFrameFormat" BO_ 168 "StandardCAN_FD";
BA_ "GenMsgCycleTime" BO_ 958 100;
BA_ "GenMsgDelayTime" BO_ 958 10;
BA_ "GenMsgILSupport" BO_ 958 "Yes";
BA_ "GenMsgPDUConstants" BO_ 958 "0x1f,0x28,0xc6,0x85,0xe6,0xf8,0xb0,0x19,0x5b,0x64,0x35,0x21,0xe4,0xf7,0x9c,0x24";
BA_ "GenMsgSendType" BO_ 958 "Cyclic";
BA_ "VFrameFormat" BO_ 958 "StandardCAN_FD";
BA_ "GenMsgCycleTime" BO_ 1631 500;
BA_ "GenMsgILSupport" BO_ 1631 "Yes";
BA_ "GenMsgSendType" BO_ 1631 "Cyclic";
BA_ "VFrameFormat" BO_ 1631 "StandardCAN_FD";
BA_ "GenMsgCycleTime" BO_ 1648 500;
BA_ "GenMsgDelayTime" BO_ 1648 20;
BA_ "GenMsgILSupport" BO_ 1648 "Yes";
BA_ "GenMsgSendType" BO_ 1648 "Cyclic";
BA_ "VFrameFormat" BO_ 1648 "StandardCAN_FD";
BA_ "GenMsgCycleTime" BO_ 967 100;
BA_ "GenMsgILSupport" BO_ 967 "Yes";
BA_ "GenMsgSendType" BO_ 967 "Cyclic";
BA_ "VFrameFormat" BO_ 967 "StandardCAN_FD";
BA_ "GenMsgCycleTime" BO_ 299 30;
BA_ "GenMsgILSupport" BO_ 299 "Yes";
BA_ "GenMsgPDUConstants" BO_ 299 "0x6a,0x38,0xb4,0x27,0x22,0xef,0xe1,0xbb,0xf8,0x80,0x84,0x49,0xc7,0x9e,0x1e,0x2b";
BA_ "GenMsgSendType" BO_ 299 "Cyclic";
BA_ "VFrameFormat" BO_ 299 "StandardCAN_FD";
BA_ "GenMsgCycleTime" BO_ 1452 100;
BA_ "GenMsgILSupport" BO_ 1452 "Yes";
BA_ "GenMsgSendType" BO_ 1452 "Cyclic";
BA_ "VFrameFormat" BO_ 1452 "StandardCAN_FD";
BA_ "GenMsgCycleTime" BO_ 1385 500;
BA_ "GenMsgDelayTime" BO_ 1385 50;
BA_ "GenMsgILSupport" BO_ 1385 "Yes";
BA_ "GenMsgSendType" BO_ 1385 "Cyclic";
BA_ "VFrameFormat" BO_ 1385 "StandardCAN_FD";
BA_ "GenMsgCycleTime" BO_ 1283 100;
BA_ "GenMsgDelayTime" BO_ 1283 10;
BA_ "GenMsgILSupport" BO_ 1283 "Yes";
BA_ "GenMsgPDUConstants" BO_ 1283 "0xed,0xd6,0x96,0x63,0xa5,0x12,0xd5,0x9a,0x1e,0x0d,0x24,0xcd,0x8c,0xa6,0x2f,0x41";
BA_ "GenMsgSendType" BO_ 1283 "Cyclic";
BA_ "VFrameFormat" BO_ 1283 "StandardCAN_FD";
BA_ "GenMsgCycleTime" BO_ 2463978813 100;
BA_ "GenMsgDelayTime" BO_ 2463978813 10;
BA_ "GenMsgILSupport" BO_ 2463978813 "Yes";
BA_ "GenMsgPDUConstants" BO_ 2463978813 "0x1d,0x82,0x7b,0x79,0xa5,0xee,0x3a,0xb9,0xb7,0xf9,0xe4,0x67,0x7f,0x97,0x11,0xad";
BA_ "GenMsgSendType" BO_ 2463978813 "Cyclic";
BA_ "VFrameFormat" BO_ 2463978813 "ExtendedCAN_FD";
BA_ "GenMsgCycleTime" BO_ 626 100;
BA_ "GenMsgDelayTime" BO_ 626 10;
BA_ "GenMsgILSupport" BO_ 626 "Yes";
BA_ "GenMsgSendType" BO_ 626 "Cyclic";
BA_ "VFrameFormat" BO_ 626 "StandardCAN_FD";
BA_ "GenMsgILSupport" BO_ 268 "Yes";
BA_ "VFrameFormat" BO_ 268 "StandardCAN_FD";
BA_ "GenMsgILSupport" BO_ 23 "Yes";
BA_ "VFrameFormat" BO_ 23 "StandardCAN_FD";
BA_ "GenMsgILSupport" BO_ 25 "Yes";
BA_ "VFrameFormat" BO_ 25 "StandardCAN_FD";
BA_ "GenMsgCycleTime" BO_ 2527679583 1000;
BA_ "GenMsgCycleTimeFast" BO_ 2527679583 100;
BA_ "GenMsgDelayTime" BO_ 2527679583 50;
BA_ "GenMsgILSupport" BO_ 2527679583 "Yes";
BA_ "GenMsgNrOfRepetition" BO_ 2527679583 5;
BA_ "GenMsgSendType" BO_ 2527679583 "Cyclic";
BA_ "VFrameFormat" BO_ 2527679583 "ExtendedCAN_FD";
BA_ "DiagRequest" BO_ 1813 "Yes";
BA_ "MsgType" BO_ 1813 "ISO-TP";
BA_ "VFrameFormat" BO_ 1813 "StandardCAN_FD";
BA_ "DiagResponse" BO_ 1919 "Yes";
BA_ "MsgType" BO_ 1919 "ISO-TP";
BA_ "VFrameFormat" BO_ 1919 "StandardCAN_FD";
BA_ "DiagState" BO_ 1792 "Yes";
BA_ "MsgType" BO_ 1792 "ISO-TP";
BA_ "VFrameFormat" BO_ 1792 "StandardCAN_FD";
BA_ "DiagRequest" BO_ 2621440021 "Yes";
BA_ "MsgType" BO_ 2621440021 "ISO-TP";
BA_ "VFrameFormat" BO_ 2621440021 "ExtendedCAN_FD";
BA_ "DiagResponse" BO_ 2621571093 "Yes";
BA_ "MsgType" BO_ 2621571093 "ISO-TP";
BA_ "VFrameFormat" BO_ 2621571093 "ExtendedCAN_FD";
BA_ "DiagRequest" BO_ 2549874812 "Yes";
BA_ "MsgType" BO_ 2549874812 "ISO-TP";
BA_ "VFrameFormat" BO_ 2549874812 "ExtendedCAN_FD";
BA_ "DiagRequest" BO_ 2621440124 "Yes";
BA_ "MsgType" BO_ 2621440124 "ISO-TP";
BA_ "VFrameFormat" BO_ 2621440124 "ExtendedCAN_FD";
BA_ "DiagResponse" BO_ 2550005884 "Yes";
BA_ "MsgType" BO_ 2550005884 "ISO-TP";
BA_ "VFrameFormat" BO_ 2550005884 "ExtendedCAN_FD";
BA_ "DiagResponse" BO_ 2621571196 "Yes";
BA_ "MsgType" BO_ 2621571196 "ISO-TP";
BA_ "VFrameFormat" BO_ 2621571196 "ExtendedCAN_FD";
BA_ "DiagRequest" BO_ 2549874872 "Yes";
BA_ "MsgType" BO_ 2549874872 "ISO-TP";
BA_ "VFrameFormat" BO_ 2549874872 "ExtendedCAN_FD";
BA_ "DiagRequest" BO_ 2621440184 "Yes";
BA_ "MsgType" BO_ 2621440184 "ISO-TP";
BA_ "VFrameFormat" BO_ 2621440184 "ExtendedCAN_FD";
BA_ "DiagResponse" BO_ 2550005944 "Yes";
BA_ "MsgType" BO_ 2550005944 "ISO-TP";
BA_ "VFrameFormat" BO_ 2550005944 "ExtendedCAN_FD";
BA_ "DiagResponse" BO_ 2621571256 "Yes";
BA_ "MsgType" BO_ 2621571256 "ISO-TP";
BA_ "VFrameFormat" BO_ 2621571256 "ExtendedCAN_FD";
BA_ "DiagState" BO_ 2621505536 "Yes";
BA_ "MsgType" BO_ 2621505536 "ISO-TP";
BA_ "VFrameFormat" BO_ 2621505536 "ExtendedCAN_FD";
BA_ "DiagRequest" BO_ 2549874806 "Yes";
BA_ "MsgType" BO_ 2549874806 "ISO-TP";
BA_ "VFrameFormat" BO_ 2549874806 "ExtendedCAN_FD";
BA_ "DiagRequest" BO_ 2621440118 "Yes";
BA_ "MsgType" BO_ 2621440118 "ISO-TP";
BA_ "VFrameFormat" BO_ 2621440118 "ExtendedCAN_FD";
BA_ "DiagResponse" BO_ 2550005878 "Yes";
BA_ "MsgType" BO_ 2550005878 "ISO-TP";
BA_ "VFrameFormat" BO_ 2550005878 "ExtendedCAN_FD";
BA_ "DiagResponse" BO_ 2621571190 "Yes";
BA_ "MsgType" BO_ 2621571190 "ISO-TP";
BA_ "VFrameFormat" BO_ 2621571190 "ExtendedCAN_FD";
BA_ "GenMsgCycleTime" BO_ 2527679684 2000;
BA_ "GenMsgDelayTime" BO_ 2527679684 100;
BA_ "GenMsgILSupport" BO_ 2527679684 "Yes";
BA_ "GenMsgSendType" BO_ 2527679684 "Cyclic";
BA_ "VFrameFormat" BO_ 2527679684 "ExtendedCAN_FD";
BA_ "GenMsgChkConstant" BO_ 960 195;
BA_ "GenMsgCycleTime" BO_ 960 100;
BA_ "GenMsgDelayTime" BO_ 960 10;
BA_ "GenMsgILSupport" BO_ 960 "Yes";
BA_ "GenMsgPDUConstants" BO_ 960 "0xc3,0xc3,0xc3,0xc3,0xc3,0xc3,0xc3,0xc3,0xc3,0xc3,0xc3,0xc3,0xc3,0xc3,0xc3,0xc3";
BA_ "GenMsgSendType" BO_ 960 "Cyclic";
BA_ "VFrameFormat" BO_ 960 "StandardCAN_FD";
BA_ "GenMsgCycleTime" BO_ 2463978753 1000;
BA_ "GenMsgCycleTimeFast" BO_ 2463978753 100;
BA_ "GenMsgDelayTime" BO_ 2463978753 100;
BA_ "GenMsgILSupport" BO_ 2463978753 "Yes";
BA_ "GenMsgNrOfRepetition" BO_ 2463978753 5;
BA_ "GenMsgSendType" BO_ 2463978753 "Cyclic";
BA_ "VFrameFormat" BO_ 2463978753 "ExtendedCAN_FD";
BA_ "GenMsgCycleTime" BO_ 1420 1000;
BA_ "GenMsgCycleTimeFast" BO_ 1420 20;
BA_ "GenMsgDelayTime" BO_ 1420 10;
BA_ "GenMsgILSupport" BO_ 1420 "Yes";
BA_ "GenMsgNrOfRepetition" BO_ 1420 5;
BA_ "GenMsgPDUConstants" BO_ 1420 "0x9b,0xb5,0x9d,0x06,0x01,0xe7,0x8f,0xc1,0xd0,0x10,0x47,0xe9,0xd3,0xca,0x05,0xf0";
BA_ "GenMsgSendType" BO_ 1420 "Cyclic";
BA_ "VFrameFormat" BO_ 1420 "StandardCAN_FD";
BA_ "GenMsgCycleTime" BO_ 949 100;
BA_ "GenMsgILSupport" BO_ 949 "Yes";
BA_ "GenMsgSendType" BO_ 949 "Cyclic";
BA_ "VFrameFormat" BO_ 949 "StandardCAN_FD";
BA_ "GenMsgCycleTime" BO_ 1511 200;
BA_ "GenMsgILSupport" BO_ 1511 "Yes";
BA_ "GenMsgSendType" BO_ 1511 "Cyclic";
BA_ "VFrameFormat" BO_ 1511 "StandardCAN_FD";
BA_ "GenMsgCycleTime" BO_ 1505 200;
BA_ "GenMsgILSupport" BO_ 1505 "Yes";
BA_ "GenMsgSendType" BO_ 1505 "Cyclic";
BA_ "VFrameFormat" BO_ 1505 "StandardCAN_FD";
BA_ "GenMsgCycleTime" BO_ 2549088277 500;
BA_ "GenMsgILSupport" BO_ 2549088277 "Yes";
BA_ "GenMsgSendType" BO_ 2549088277 "Cyclic";
BA_ "CANFD_BRS" BO_ 2549088277 "0";
BA_ "VFrameFormat" BO_ 2549088277 "ExtendedCAN";
BA_ "GenMsgCycleTime" BO_ 2549088380 500;
BA_ "GenMsgILSupport" BO_ 2549088380 "Yes";
BA_ "GenMsgSendType" BO_ 2549088380 "Cyclic";
BA_ "VFrameFormat" BO_ 2549088380 "ExtendedCAN_FD";
BA_ "GenMsgCycleTime" BO_ 2549088272 500;
BA_ "GenMsgILSupport" BO_ 2549088272 "Yes";
BA_ "GenMsgSendType" BO_ 2549088272 "Cyclic";
BA_ "VFrameFormat" BO_ 2549088272 "ExtendedCAN_FD";
BA_ "GenMsgCycleTime" BO_ 2549088440 500;
BA_ "GenMsgILSupport" BO_ 2549088440 "Yes";
BA_ "GenMsgSendType" BO_ 2549088440 "Cyclic";
BA_ "VFrameFormat" BO_ 2549088440 "ExtendedCAN_FD";
BA_ "GenMsgCycleTime" BO_ 2549088374 500;
BA_ "GenMsgILSupport" BO_ 2549088374 "Yes";
BA_ "GenMsgSendType" BO_ 2549088374 "Cyclic";
BA_ "VFrameFormat" BO_ 2549088374 "ExtendedCAN_FD";
BA_ "MsgType" BO_ 2621440277 "ISO-TP";
BA_ "VFrameFormat" BO_ 2621440277 "ExtendedCAN_FD";
BA_ "MsgType" BO_ 2621571349 "ISO-TP";
BA_ "VFrameFormat" BO_ 2621571349 "ExtendedCAN_FD";
BA_ "GenMsgCycleTime" BO_ 982 100;
BA_ "GenMsgDelayTime" BO_ 982 20;
BA_ "GenMsgILSupport" BO_ 982 "Yes";
BA_ "GenMsgSendType" BO_ 982 "Cyclic";
BA_ "VFrameFormat" BO_ 982 "StandardCAN_FD";
BA_ "GenMsgChkConstant" BO_ 134 134;
BA_ "GenMsgCycleTime" BO_ 134 5;
BA_ "GenMsgILSupport" BO_ 134 "Yes";
BA_ "GenMsgPDUConstants" BO_ 134 "0x86,0x86,0x86,0x86,0x86,0x86,0x86,0x86,0x86,0x86,0x86,0x86,0x86,0x86,0x86,0x86";
BA_ "GenMsgSendType" BO_ 134 "Cyclic";
BA_ "VFrameFormat" BO_ 134 "StandardCAN_FD";
BA_ "GenMsgCycleTime" BO_ 817 500;
BA_ "GenMsgCycleTimeFast" BO_ 817 30;
BA_ "GenMsgILSupport" BO_ 817 "Yes";
BA_ "GenMsgSendType" BO_ 817 "Cyclic";
BA_ "VFrameFormat" BO_ 817 "StandardCAN_FD";
BA_ "GenMsgCycleTimeFast" BO_ 15 10;
BA_ "GenMsgILSupport" BO_ 15 "Yes";
BA_ "GenMsgSendType" BO_ 15 "IfActive";
BA_ "VFrameFormat" BO_ 15 "StandardCAN_FD";
BA_ "GenMsgCycleTime" BO_ 1600 500;
BA_ "GenMsgILSupport" BO_ 1600 "Yes";
BA_ "GenMsgSendType" BO_ 1600 "Cyclic";
BA_ "VFrameFormat" BO_ 1600 "StandardCAN_FD";
BA_ "GenMsgCycleTime" BO_ 167 10;
BA_ "GenMsgILSupport" BO_ 167 "Yes";
BA_ "GenMsgPDUConstants" BO_ 167 "0xd2,0x3d,0xcd,0x28,0x4c,0x14,0x22,0x4b,0x24,0xac,0xfa,0x55,0x66,0x80,0x0d,0x6c";
BA_ "GenMsgSendType" BO_ 167 "Cyclic";
BA_ "VFrameFormat" BO_ 167 "StandardCAN_FD";
BA_ "GenMsgCycleTime" BO_ 168 10;
BA_ "GenMsgILSupport" BO_ 168 "Yes";
BA_ "GenMsgPDUConstants" BO_ 168 "0x52,0x8c,0x50,0xee,0x4f,0xa6,0xcc,0xcf,0x7d,0x2f,0x98,0x6b,0x27,0x41,0x9f,0x93";
BA_ "GenMsgSendType" BO_ 168 "Cyclic";
BA_ "VFrameFormat" BO_ 168 "StandardCAN_FD";
BA_ "GenMsgCycleTime" BO_ 958 100;
BA_ "GenMsgDelayTime" BO_ 958 10;
BA_ "GenMsgILSupport" BO_ 958 "Yes";
BA_ "GenMsgPDUConstants" BO_ 958 "0x1f,0x28,0xc6,0x85,0xe6,0xf8,0xb0,0x19,0x5b,0x64,0x35,0x21,0xe4,0xf7,0x9c,0x24";
BA_ "GenMsgSendType" BO_ 958 "Cyclic";
BA_ "VFrameFormat" BO_ 958 "StandardCAN_FD";
BA_ "GenMsgCycleTime" BO_ 1631 500;
BA_ "GenMsgILSupport" BO_ 1631 "Yes";
BA_ "GenMsgSendType" BO_ 1631 "Cyclic";
BA_ "VFrameFormat" BO_ 1631 "StandardCAN_FD";
BA_ "GenMsgCycleTime" BO_ 1648 500;
BA_ "GenMsgDelayTime" BO_ 1648 20;
BA_ "GenMsgILSupport" BO_ 1648 "Yes";
BA_ "GenMsgSendType" BO_ 1648 "Cyclic";
BA_ "VFrameFormat" BO_ 1648 "StandardCAN_FD";
BA_ "GenMsgCycleTime" BO_ 967 100;
BA_ "GenMsgILSupport" BO_ 967 "Yes";
BA_ "GenMsgSendType" BO_ 967 "Cyclic";
BA_ "VFrameFormat" BO_ 967 "StandardCAN_FD";
VAL_ 299 GRA_Hauptschalter 0 "Hauptschalter_aus__Taster_nicht_betaetigt" 1 "Hauptschalter_ein__Taster_betaetigt";
VAL_ 299 GRA_Abbrechen 0 "nicht_betaetigt" 1 "betaetigt";
VAL_ 299 GRA_Typ_Hauptschalter 0 "gerasteter_Lenkstockschalter" 1 "getasteter_Lenkstockschalter";
VAL_ 299 GRA_Limiter 0 "nicht_betaetigt" 1 "betaetigt";
VAL_ 299 GRA_Tip_Setzen 0 "nicht_betaetigt" 1 "betaetigt";
VAL_ 299 GRA_Tip_Hoch 0 "nicht_betaetigt" 1 "betaetigt";
VAL_ 299 GRA_Tip_Runter 0 "nicht_betaetigt" 1 "betaetigt";
VAL_ 299 GRA_Tip_Wiederaufnahme 0 "nicht_betaetigt" 1 "betaetigt";
VAL_ 299 GRA_Verstellung_Zeitluecke 0 "Taste_nicht_betaetigt" 1 "Dist_minus_1" 2 "Dist_plus_1" 3 "Dist_Toggle";
VAL_ 299 GRA_Codierung 0 "kein_Hebel" 1 "GRA_Hebel" 2 "ACC_Hebel" 3 "Limiter_Only";
VAL_ 299 GRA_Fehler 0 "kein_Fehler" 1 "Fehler";
VAL_ 299 GRA_LIM_Taste_verfuegbar 0 "Limiter_Taste_nicht_vorhanden" 1 "Limiter_Taste_vorhanden";
VAL_ 299 GRA_Tip_Stufe_2 0 "Tip_Stufe_1__keine_Betaetigung" 1 "Tip_Stufe_2";
VAL_ 299 GRA_Typ_Bedienteil 0 "Init" 1 "4_Positions_Bedienteil" 2 "6_Positions_Bedienteil" 3 "8_Positions_Bedienteil" 4 "PAG_5_Positions_Bedienteil" 5 "VW_MFL_Gen2" 6 "VW_MFL_Gen3" 7 "reserviert";
VAL_ 299 GRA_TravelAssist 0 "nicht_betaetigt" 1 "betaetigt";
VAL_ 1452 HVEM_IstStrom_HVVerbraucher 4094 "Init" 4095 "Fehler";
VAL_ 1452 HVEM_Energie_Klima_Vorgabe_HighR 6 "Init" 7 "Fehler";
VAL_ 1452 HVEM_IstLeistungNA 510 "Init" 511 "Fehler";
VAL_ 1452 HVEM_Leistung_Klima_Vorgabe 254 "Init" 255 "Fehler";
VAL_ 1452 HVEM_Nutzbare_Energie 2045 "Max" 2046 "Init" 2047 "Fehler";
VAL_ 1452 HVEM_Energie_Klima_Vorgabe 254 "Init" 255 "Fehler";
VAL_ 1452 HVEM_HVK_Aktivitaet 0 "keine_Aktivitaet" 1 "Aktivitaet" 2 "Init";
VAL_ 1452 HVEM_Pruefpuls_Anf 0 "Keine_Anforderung" 1 "Anforderung" 2 "Reserved" 3 "Init";
VAL_ 1452 HVEM_HV_Anf 0 "keine_Anforderung" 1 "HV_angefordert";
VAL_ 1452 HVEM_MO_MaxLeistungIgnoriert 0 "Max_Leistung_nicht_ignoriert" 1 "Max_Leistung_ignoriert";
VAL_ 1385 HVEM_DCDC_Freigabe 0 "keine_Freigabe" 1 "Freigabe";
VAL_ 1385 HVEM_Ladesteckerentr_Anf 0 "keine_Anforderung" 1 "Anf_Ladestecker_Entr";
VAL_ 1385 HVEM_LeistungsAnf 0 "nicht_angefordert" 1 "angefordert";
VAL_ 1385 HVEM_Nachlad_Status 0 "nicht_moeglich__Fehler" 1 "moeglich__begonnen" 2 "Beendet" 3 "Init";
VAL_ 1385 HVEM_Abschaltstatus 0 "100" 1 "75" 2 "50" 3 "25" 7 "Init";
VAL_ 1385 HVEM_Anf_ReichweiteNV 0 "keine_Massnahme_notwendig" 1 "Reduktion_Stufe_1" 2 "Reduktion_Stufe_2" 3 "Fehler";
VAL_ 1385 HVEM_LadeklappenVerr_Anf 0 "Init" 1 "Ladeklappe_verriegeln" 2 "Ladeklappe_entriegeln";
VAL_ 1385 HVEM_Max_VK_Betriebsdauer 62 "Init" 63 "Fehler";
VAL_ 1385 HVEM_HV_Anf 0 "keine_Anforderung" 1 "HV_angefordert";
VAL_ 1385 HVEM_Text_1 0 "kein_Text" 1 "Text";
VAL_ 1385 HVEM_Nachladen_Anf 0 "keine_Anforderung" 1 "Nachladen_angefordert";
VAL_ 1385 HVEM_FreigabeKlimatisierung 0 "keine_Freigabe" 1 "Freigabe" 2 "Init" 3 "Fehler";
VAL_ 1385 HVEM_Leistung_Bat_Kond_Vorgabe 254 "Init";
VAL_ 1283 HVK_Istmodus_Anf 0 "nicht_angefordert" 1 "angefordert";
VAL_ 1283 HVK_TN1_Sollmodus 0 "HV_Off" 1 "HV_On" 2 "reserviert" 3 "Initialisierung";
VAL_ 1283 HVK_Vorladung_aktiv 0 "Vorladung_nicht_aktiv" 1 "Vorladung_aktiv";
VAL_ 1283 HVK_BMS_Sollmodus 0 "HV_Off" 1 "HV_On" 3 "AC_Laden_erw" 4 "AC_Laden" 6 "DC_Laden" 7 "Init";
VAL_ 1283 HVK_DCDC_Sollmodus 0 "Standby" 1 "HV_On_Vorladen" 2 "Tiefsetzen" 3 "Hochsetzen" 4 "Pruefpuls_12V" 7 "Initialisierung";
VAL_ 1283 HVK_EKK_Sollmodus 0 "Keine_Freigabe" 1 "Freigabe" 2 "Freigabe_ausgesetzt" 7 "Init";
VAL_ 1283 HVK_HVPTC_Sollmodus 0 "Keine_Freigabe" 1 "Freigabe" 2 "Freigabe_ausgesetzt" 7 "Init";
VAL_ 1283 HVK_HVLM_Sollmodus 0 "keine_Freigabe" 1 "Freigabe_Lademanager" 7 "Init";
VAL_ 1283 HVK_HV_Netz_Warnungen 0 "Keine_Warnung" 1 "Warntext_HV_Netz_Anf" 2 "Fehlertext_HV_Netz_Anf" 3 "Warnung_Kein_Wiederstart_moeglich";
VAL_ 1283 HV_Bordnetz_aktiv 0 "inaktiv" 1 "aktiv";
VAL_ 1283 HV_Bordnetz_Fehler 0 "kein_Fehler" 1 "Fehler";
VAL_ 1283 HVK_Gesamtst_Spgfreiheit 0 "Funktion_Init__ohne_Funktion" 1 "HV_System_spannungsfrei" 2 "HV_System_nicht_spannungsfrei" 3 "Fehler";
VAL_ 1283 HVK_AktiveEntladung_Anf 0 "nicht_angefordert" 1 "angefordert";
VAL_ 1283 HVK_HVEM_Freigabe 0 "keine_Freigabe" 1 "Freigabe" 2 "Init";
VAL_ 1283 HVK_Notentladung_Anf 0 "keine_Anforderung_Notentladung" 1 "Anforderung_Notentladung" 2 "Reserve" 3 "INIT_keine_HV_Zuschaltung";
VAL_ 1283 HVK_Iso_Messung_Start 0 "keine_Messung" 1 "Messung_HV_Netz_1" 2 "Messung_HV_Netz_2" 4 "deaktiviert";
VAL_ 1283 HVK_Ladebereit 0 "Init_oder_nicht_Ladebereit" 1 "AC_Ladebereit" 2 "DC_Ladebereit" 3 "AC_und_DC_Ladebereit" 4 "Induktiv_Ladebereit" 5 "AC_und_Induktiv_Ladebereit" 6 "DC_und_Induktiv_Ladebereit" 7 "AC_DC_und_Induktiv_Ladebereit";
VAL_ 1283 HVK_PPulsFreigabe 0 "keine_Freigabe" 1 "Freigabe" 2 "Reserve" 3 "Init";
VAL_ 2463978813 HVL_Steckerstatus 0 "Init" 1 "kein_Stecker_erkannt" 2 "Stecker_erkannt" 3 "Fehler";
VAL_ 2463978813 HVL_LadeAnforderung 0 "Laden_nicht_angefordert" 1 "AC_Laden_Angefordert" 2 "DC_Laden_Angefordert" 3 "AC_und_DC_Angefordert" 4 "Induktiv_Laden_Angef" 5 "AC_und_Induktiv_Angef" 6 "DC_und_Induktiv_Angef" 7 "Fehler";
VAL_ 626 HVLM_Anforderung_HMS 0 "keine_Anforderung" 1 "halten" 2 "parken" 3 "halten_Standby" 4 "anfahren" 5 "Loesen_ueber_Rampe";
VAL_ 626 HVLM_Parken_beibehalten_HMS 0 "Parken_nicht_beibehalten" 1 "Parken_beibehalten" 2 "Init" 3 "Fehler";
VAL_ 626 HVLM_WakeUpZaehlerResetAnf 0 "keine_Anforderung" 1 "Reset_Zaehler";
VAL_ 626 HVLM_AWC_VerbautStatus 0 "Init" 1 "nicht_verbaut" 2 "verbaut" 3 "Fehler";
VAL_ 626 HVLM_Steckerstatus_A 0 "Init" 1 "kein_Stecker_erkannt" 2 "Stecker_steckt_nicht_verriegelt" 3 "Stecker_steckt_und_verriegelt" 7 "Fehler";
VAL_ 626 HVLM_Steckerstatus_B 0 "Init" 1 "kein_Stecker_erkannt" 2 "Stecker_steckt_nicht_verriegelt" 3 "Stecker_steckt_und_verriegelt" 7 "Fehler";
VAL_ 626 HVLM_Start_Pulserkennung 0 "keine_Anforderung" 1 "Pulserkennung_starten";
VAL_ 626 HVLM_ZustandLadeablauf 8 "Erhaltungsladen" 0 "Init" 1 "Stby_Ladevorbed_erfuellt" 2 "Stby_Ladevorbed_nicht_erfuellt" 4 "Laden_starten" 5 "Laden_beenden" 6 "HVBatterie_Laden" 7 "HVBatterie_Entladen";
VAL_ 626 HVLM_DC_Aufstartmodus 0 "keine_Anforderung" 1 "Angleich_Fahrzeug" 2 "Angleich_LS_1" 3 "Angleich_LS_2";
VAL_ 626 HVLM_Ladeszenario 0 "Aus" 1 "Timerladen_abgeschlossen" 2 "Sofortladen_abgeschlossen" 3 "Optimiertes_Laden_abgeschlossen" 4 "Timerladen_aktiv" 5 "Sofortladen_aktiv" 6 "Optimiertes_Laden_aktiv" 7 "Timerladen_warten" 8 "Optimiertes_Laden_warten" 9 "Keine_Netzspannung" 10 "Fehler_Verriegelung" 11 "Fehler_Ladesytem" 12 "Init_Ladekommunikation" 30 "Init" 31 "Fehler";
VAL_ 626 HVLM_Ladevorgang_Anf 0 "Laden_nicht_angefordert" 1 "AC_Laden_Angefordert" 2 "DC_Laden_Angefordert" 3 "AC_und_DC_Angefordert" 4 "Induktiv_Laden_Angef" 5 "AC_und_Induktiv_Angef" 6 "DC_und_Induktiv_Angef" 7 "AC_DC_und_Induktiv_Angef";
VAL_ 626 HVLM_Intensitaet 126 "Init" 127 "Fehler";
VAL_ 626 HVLM_Laden_ISO_Messung_Anf 0 "Anforderung" 1 "keine_Anforderung";
VAL_ 268 ImoCord_Auth_Aufforderung_WFS 0 "nicht_anfordern" 1 "anfordern";
VAL_ 2527679583 Parken_Seitenspiegel_Anf 0 "Keine_Anforderung" 1 "Seitenspiegel_anklappen" 2 "Seitenspiegel_abklappen";
VAL_ 2527679583 Parken_ZV_Schliessen 0 "Keine_Anforderung" 1 "ZV_verriegeln" 2 "ZV_safen";
VAL_ 2527679583 Parken_aktives_System_02 0 "Init" 1 "Keine_Aktivitaet" 2 "RPA" 3 "IPA" 4 "MA" 5 "TP" 6 "rTP" 7 "AAA" 8 "rAAA" 9 "ARA_1" 10 "PLA" 11 "RBF" 12 "PHP";
VAL_ 2527679583 Parken_ZR_Sondermodus_Anf 0 "Init" 1 "Keine_Anforderung" 2 "Anforderung_Sondermodus";
VAL_ 2527679583 Parken_Schluesselsuche_Anf 0 "keine_Anforderung" 1 "Anforderung_Schluesselsuche";
VAL_ 2527679583 Parken_FFB_LED_Anf 0 "keine_Anforderung" 1 "Abbruch_Fehler" 2 "Bereit_OK" 3 "Beendet";
VAL_ 2527679583 Parken_Wegfahrsperren_Anf 0 "keine_Anforderung" 1 "Anforderung_Fahreruebernahme" 2 "Anforderung_Fahreruebergabe";
VAL_ 2527679583 Parken_Aktivierungslicht_Anf 0 "keine_Anforderung" 1 "Aktivierungslicht";
VAL_ 2527679583 Parken_Fahrtrichtungslicht_Anf 0 "keine_Anforderung" 1 "Vorwaerts" 2 "Rueckwaerts";
VAL_ 2527679583 Parken_Lichtnachlauf_Anf 0 "keine_Anforderung" 1 "Anforderung_Lichtnachlauf";
VAL_ 2527679583 Parken_Fahrerhinweise_Anf 0 "keine_Anforderung" 1 "Fahrerhinweise_anzeigen";
VAL_ 2527679583 Parken_Bestaetigungsblinken_Anf 0 "keine_Anforderung" 1 "Erfolgsblinken_Einparken" 2 "Abbruchsblinken" 3 "Erfolgsblinken_Ausparken";
VAL_ 2527679583 Parken_Fahrbereitschaftlicht_Anf 0 "keine_Anforderung" 1 "Fahrbereitschaftslicht";
VAL_ 2527679583 Parken_Lichtsteuerung_Anf 0 "keine_Anforderung" 1 "Automatik_Lichtmodus_aktivieren";
VAL_ 2527679583 IPA_Anf_Meldungen 136 "Disclaimer_Bremse_loesen" 8 "Fahrinf_PaLueSu_aufschalten" 128 "Disclaimer_LP_rechts" 0 "keine Meldung" 129 "Disclaimer_LP_links" 1 "beendet" 130 "Disclaimer_RQ_rechts" 2 "Fahrinf_Bremse_FT_betaetigen" 131 "Disclaimer_RQ_links" 3 "Suche_fortsetzen_ESC_Eingriff" 132 "Disclaimer_VQ_rechts" 4 "n_a_temp_ESC_deaktiviert" 133 "Disclaimer_VQ_links" 5 "n_a_temp_Anhaengerbetrieb" 134 "Disclaimer_AP_rechts" 6 "Suche_Zeitlimit_ueberschritten" 137 "Abbruch_Lenkeingriff_Fahrer" 9 "Stby_Bremse_u_FT_druecken" 138 "Abbruch_Anhaenger_erkannt" 10 "PosOK_Stillstandszeit" 139 "Abbruch_max_Rangierzuege" 11 "Stby_FT_druecken" 140 "Abbruch_Zeitlimit_ueberschritten" 12 "AP_nicht_moeglich" 141 "Beendet_Bitte_uebernehmen" 13 "Fahrinf_Bremse_loesen_Umfeld" 142 "Beendet" 14 "n_a_temp_Tuer_Heckklappe_offen" 15 "Stby_Tuer_Heckklappe_schliessen" 16 "PP_aktiv_nur_aussen_bedienbar" 17 "PP_Fzg_verlassen" 18 "n_a_Offroad_Modus" 19 "PP_Schluessel_oder_App_bedienen" 20 "PP_App_bedienen" 21 "PP_Schluessel_bedienen" 22 "n_a_temp" 23 "Systemstoerung_Service" 24 "n_a_temp_Sensorsicht" 25 "n_a_temp_Spiegel_ausklappen" 26 "GP_Stoerung_Service" 27 "n_a_temp_FAS_aktiv" 28 "PP_BT_unterbrochen" 29 "Hindernis_in_Fahrtrichtung" 30 "Ausparken_Fahrtrichtung_vorgeben" 32 "Suche_Rangierflaeche_zu_klein" 33 "n_a_temp_Drive_Select" 34 "Fahrinf_Bremse_loesen" 35 "Fahrinf_Fahrtrichtungswechsel" 36 "Fahrinf_Bremse_FT_RT_betaetigen" 37 "GP_Fzgposition_vor_Garage" 38 "GP_RT_Garage_oeffnen" 39 "GP_Kein_Zuparken" 40 "Suche_Fahrinfo_beachten" 41 "GP_Fzgposition_freie_Parkflaeche" 42 "GP_n_a_temp_Laser" 43 "Geschwindigkeitsueberschreitung" 44 "Fahrinf_Weiter_vorfahren" 45 "Fahrinf_Bremsbetaetigug" 46 "Fahrinf_Anhalten" 47 "GP_AP_nicht_moeglich_Fahrweg" 48 "PP_Gang_Schluesselauthentifizier" 49 "Fahrhinweis_FT_betaetigen" 50 "PP_aktiv_Hinweis_FUEN" 135 "Disclaimer_AP_links" 143 "Abbruch_Fahrpedaleingriff" 144 "Abbruch_ESC_Eingriff" 145 "Stby_Verkehr_erkannt" 146 "Abbruch_Spiegel_ausklappen" 147 "Abbruch_Waehlhebeleingriff" 148 "Abbruch_AP_Luecke_zu_klein" 149 "Abbruch_Rangierflaeche_zu_klein" 150 "Abbruch_Sensorsicht" 151 "Beendet_Stoerung_Fzgverbindung" 152 "Beendet_selbst_bremsen" 153 "Abbruch_Hindernis_erkannt" 154 "Abbruch_bitte_uebernehmen" 155 "Beendet_Fortsetzung_moeglich" 156 "Stby_Hindernis_erkannt" 157 "FUEN_moeglich" 158 "Abbruch_FUEN_Motor_abgestellt" 159 "Abbruch_Drive_Select" 160 "Abbruch_AP_Seite_versperrt" 161 "PP_Fehler_Schluesselautorisier" 162 "PP_Hinweis_ZV" 163 "PP_Hinweis_Motorabschaltung" 164 "Stby_FT_oder_RT_betaetigen" 165 "Stby_Hindernis_Richtungswechsel" 166 "Stby_erhoehter_Fahrwiderstand" 167 "Abbruch_EPB_aktiviert" 168 "Abbruch_MO_nicht_bereit" 169 "Abbruch_Stoerung_Service" 170 "Abbruch_Gurtschloss_gesteckt" 171 "PP_Abbruch_Rangierbereich" 172 "PP_Abbruch_Verdeckaktivierung" 173 "Abbruch_Bremseingriff_FAS_System" 174 "PP_eingeschraenkt_verfuegbar" 175 "Abbruch" 176 "PosOK_Lenkrad_loslassen_Bremse" 177 "PosOK_Lenkrad_loslassen_FT" 178 "Wiederaufnahme_FT_betaetigen" 179 "PP_beendet_FUEN_moeglich" 180 "Lenkeingriff_beendet" 181 "PP_Abbruch_Zeitlimit" 192 "TPA_aborted_deviated_from_trajec" 193 "TPA_aborted_limited_visibility" 194 "TPA_aborted_localization_failure" 195 "TPA_aborted_System_error" 196 "TPA_aborted_TPA_canceled" 197 "TPA_DNH_Platzhalter" 198 "TPA_DNH_Platzhalter" 199 "TPA_DNH_Platzhalter" 200 "TPA_DNH_Platzhalter" 201 "TPA_DNH_Platzhalter" 202 "TPA_DNH_Platzhalter" 203 "TPA_DNH_Platzhalter" 204 "TPA_DNH_Platzhalter" 205 "TPA_DNH_Platzhalter" 206 "TPA_DNH_Platzhalter" 207 "TPA_DNH_Platzhalter";
VAL_ 2527679684 Kamera_ASM_Ereignis 0 "No_Event" 255 "ASM_Trigger";
VAL_ 2527679684 Kamera_ASM_Zeitstempel 255 "Init";
VAL_ 960 RSt_Fahrerhinweise 0 "Init" 1 "Fahreruebernahme_Hinweis_ZAT_Automat_ohne_Gong" 2 "Fahreruebernahme_Hinweis_ZAT_Automat_mit_Gong" 3 "Fahreruebernahme_Hinweis_ZAT_Handschalter_ohne_Gong" 4 "Fahreruebernahme_Hinweis_ZAT_Handschalter_mit_Gong" 5 "Fahreruebernahme_Hinweis_ZAS_Automat_ohne_Gong" 6 "Fahreruebernahme_Hinweis_ZAS_Automat_mit_Gong" 7 "Fahreruebernahme_Hinweis_ZAS_Handschalter_ohne_Gong" 8 "Fahreruebernahme_Hinweis_ZAS_Handschalter_mit_Gong" 9 "RemoteStart_aktiv_ohne_Gong" 10 "RemoteStart_aktiv_mit_Gong" 11 "void" 12 "void" 13 "void" 14 "void" 15 "void";
VAL_ 960 ZAS_Kl_S 0 "aus" 1 "S_Kontakt_ein";
VAL_ 960 ZAS_Kl_15 0 "aus" 1 "ein";
VAL_ 960 ZAS_Kl_X 0 "aus" 1 "ein";
VAL_ 960 ZAS_Kl_50_Startanforderung 0 "aus" 1 "KL50_ein_Startwunsch_Fahrer";
VAL_ 960 BCM_Remotestart_Betrieb 0 "kein_RS_Betrieb" 1 "RS_Betrieb";
VAL_ 960 ZAS_Kl_Infotainment 0 "inaktiv" 1 "aktiv";
VAL_ 960 BCM_Remotestart_KL15_Anf 0 "inaktiv" 1 "aktiv";
VAL_ 960 BCM_Remotestart_MO_Start 0 "nicht_angefordert" 1 "angefordert";
VAL_ 960 KST_Warn_P1_ZST_def 0 "nicht_defekt" 1 "defekt";
VAL_ 960 KST_Warn_P2_ZST_def 0 "nicht_defekt" 1 "defekt";
VAL_ 960 KST_Fahrerhinweis_1 0 "inaktiv" 1 "aktiv";
VAL_ 960 KST_Fahrerhinweis_2 0 "inaktiv" 1 "aktiv";
VAL_ 960 BCM_Ausparken_Betrieb 0 "kein_Betrieb" 1 "Ausparkvorgang_aktiv";
VAL_ 960 KST_Fahrerhinweis_4 0 "inaktiv" 1 "aktiv";
VAL_ 960 KST_Fahrerhinweis_5 0 "inaktiv" 1 "aktiv";
VAL_ 960 KST_Fahrerhinweis_6 0 "inaktiv" 1 "aktiv";
VAL_ 2463978753 KST_WFS_Fahrfreigabe_Anforderung 0 "Keine" 1 "Uneingeschraenkt" 2 "Eingeschraenkt";
VAL_ 2463978753 KST_Sonderzustand_Status 0 "Init" 1 "Uebergang_neue_Anforderung" 2 "Aktiv" 3 "Fehler";
VAL_ 2463978753 KST_Sonderzustand_Anforderung 0 "Init" 1 "RemoteStart" 2 "RemoteParkAssist" 3 "IntelligentParkAssist" 4 "TrainiertesParken" 5 "OnlineRemoteUpdate" 6 "Einfrierschutz" 7 "Klemme15ViaDiagnose" 8 "RueckwandklappenSicherungPDC" 9 "ParkHausPilot" 31 "Fehler";
VAL_ 1420 KST_Anf_Klemme_15 0 "nicht_angefordert" 1 "angefordert";
VAL_ 1420 KST_Anf_Klemme_50 0 "nicht_angefordert" 1 "angefordert";
VAL_ 1420 KST_Anf_Klemme_S 0 "nicht_angefordert" 1 "angefordert";
VAL_ 1420 KST_Txt_Werkstatt 0 "Aus" 1 "Ein";
VAL_ 1420 KST_Txt_P_Gang 0 "Aus" 1 "Ein";
VAL_ 1420 KST_Txt_Panikabschaltung 0 "Aus" 1 "Ein";
VAL_ 1420 KST_Anf_Klemmenfreigabe_ELV 0 "nicht_angefordert" 1 "angefordert";
VAL_ 1420 KST_Txt_Komfortabschaltung 0 "inaktiv" 1 "aktiv";
VAL_ 1420 KST_Unterdr_Zuendungsmeldung 0 "keine_Unterdr_der_Zuendungsmeldung" 1 "Unterdr_der_Zuendungsmeldung_aktiv";
VAL_ 1420 KST_aut_Abschaltung_Zuendung 0 "Zuendung_wird_bei_Verl_nicht_deaktiviert" 1 "Zuendung_wird_bei_Verl_deaktiviert";
VAL_ 1420 KST_Anf_Klemmenfreigabe_WFS 0 "nicht_angefordert" 1 "angefordert";
VAL_ 1420 KST_Anf_ZV_Verriegelung 0 "inaktiv" 1 "aktiv";
VAL_ 1420 Relais_VoKo_angesteuert 0 "nicht_angesteuert" 1 "angesteuert";
VAL_ 1420 RSt_Anforderung_HMS 0 "keine_Anforderung" 1 "halten" 2 "parken" 3 "halten_Standby" 4 "anfahren" 5 "Loesen_ueber_Rampe" 6 "Parken_mit_P";
VAL_ 1420 KST_Zuendungswarnung 0 "keine_Ausgabe_Zuendungswarnung" 1 "Ausg_Zuendungswarnung_Stillstand" 2 "Ausg_Zuendungswarnung_Fahrt" 3 "reserved";
VAL_ 1420 KST_Fahrer_Info_Text 0 "nicht_Aktiv" 1 "Fahrerhinweis_1" 2 "Fahrerhinweis_2";
VAL_ 949 KL_Drehz_Anh 0 "keine_Anhebung" 1 "Drehzahlanhebung_vom_Motor_angefordert";
VAL_ 949 KL_Vorwarn_Komp_ein 0 "Init" 1 "Vorwarnung_Kompressor_ein";
VAL_ 949 KL_AC_Schalter 0 "aus" 1 "ein";
VAL_ 949 KL_Komp_Moment_alt 1 "veraltet_bzw_Ermittlung_des_Moments_nicht_moeglich__zB_keine_Drehzahl_kein_Kaeltemitteldruck";
VAL_ 949 KL_Vorwarn_Zuheizer_ein 0 "keine_Vorwarnung" 1 "Vorwarnung_Zuheizer_ein";
VAL_ 949 KL_Zustand 0 "Aus" 1 "Ein";
VAL_ 949 KL_Kompressorkupplung_linear 253 "volle_Ansteuerung" 254 "Init__nicht_bedient";
VAL_ 949 KL_Charisma_FahrPr 0 "keine_Funktion" 1 "Programm_1" 2 "Programm_2" 3 "Programm_3" 4 "Programm_4" 5 "Programm_5" 6 "Programm_6" 7 "Programm_7" 8 "Programm_8" 9 "Programm_9" 10 "Programm_10" 11 "Programm_11" 12 "Programm_12" 13 "Programm_13" 14 "Programm_14" 15 "Programm_15";
VAL_ 949 KL_Charisma_Status 0 "Init" 1 "verfuegbar" 2 "nicht_verfuegbar" 3 "asynchron_durch_Fahrerwunsch";
VAL_ 949 KL_nachtr_Stopp_Anf 0 "nicht_angefordert" 1 "angefordert";
VAL_ 949 KL_T_Charge 0 "Taster_nicht_betaetigt" 1 "Taster_betaetigt";
VAL_ 949 KL_Last_Kompr 255 "Fehler";
VAL_ 949 KL_Spannungs_Anf 0 "keine_Anforderung" 1 "Anforderung_Stufe_1" 2 "Anforderung_Stufe_2" 3 "Anforderung_Stufe_3";
VAL_ 949 KL_Thermomanagement 0 "keine_Freigabe_TMM__max_Heizbedarf" 1 "kleine_Freigabe_TMM" 2 "mittlere_Freigabe_TMM" 3 "volle_Freigabe_TMM__kein_Heizbedarf";
VAL_ 949 KL_StartStopp_Info 0 "Motorlauf_nicht_notwendig_(Stoppfreigabe)" 1 "Motoranlauf_nicht_zwingend_notwendig_(Stoppverbot,keine_Startanforderung)" 2 "Motoranlauf_zwingend_notwendig_(Startanforderung)" 3 "Systemfehler";
VAL_ 949 KL_Freilauf_Info 0 "Freilauf_freigegeben" 1 "Uebergang_in_Freilauf_unzulaessig" 2 "Freilauf_nicht_freigegeben_Abbruch" 3 "Freilauf_Anforderung";
VAL_ 949 KL_Anf_KL 255 "Fehler";
VAL_ 949 KL_el_Zuheizer_Stufe 0 "Aus" 1 "Stufe_1" 2 "Stufe_2" 3 "Stufe_3";
VAL_ 949 KL_Ausstattung_Klima 0 "Heizung_elektrisch" 1 "Klimamanuell_elektrisch" 2 "Climatic__1_Zone" 3 "Climatronic__1_Zone" 4 "Climatronic__2_Zonen" 5 "Climatronic__3_Zonen" 6 "Climatronic__4_Zonen" 7 "reserviert";
VAL_ 949 KL_Variante_Standheizung 0 "Wasserstandheizung_60_min_Laufzeit" 1 "Luftstandheizung_120_min_Laufzeit" 2 "Wasserstandheizung_120_min_Laufzeit" 3 "Wasser_und_Luftstandheizung_120_min_Laufzeit";
VAL_ 949 KL_Anf_KV 126 "Init";
VAL_ 1511 KL_HV_Heizer_Strom 255 "Init";
VAL_ 1511 KL_EKK_Strom 255 "Init";
VAL_ 1511 KL_Pumpe_02_Soll 126 "Init" 127 "Fehler";
VAL_ 1511 KL_Ventil_03_Soll 0 "nicht_ansteuern" 1 "Ventil_ansteuern";
VAL_ 1511 KL_Ventil_10_Status 0 "Ventil_nicht_angesteuert" 1 "Ventil_angesteuert" 2 "reserviert" 3 "reserviert" 4 "reserviert" 5 "Ventil_nicht_verbaut" 6 "Init" 7 "Fehler";
VAL_ 1511 KL_Senderkennung 0 "Sender Climatronic SG" 1 "Sender Waermepumpen SG";
VAL_ 1511 WP_KJ_Soll 0 "Init_Keine_Anforderung" 1 "KJ_oeffnen" 2 "KJ_schliessen" 3 "Fehler";
VAL_ 1511 KL_Fehler_HV_EKK 0 "Init" 1 "Kein HV Fehler am EKK erkannt" 2 "HV Fehler am EKK erkannt" 3 "Fehler";
VAL_ 1511 KL_Fehler_HV_Heizer 0 "Init" 1 "Kein HV Fehler am HV Heizer erkannt" 2 "HV Fehler am HV Heizer erkannt" 3 "Fehler";
VAL_ 1511 KL_BattKond_WaPu_DZMax 62 "Init" 63 "Fehler";
VAL_ 1511 WP_Kuehlerluefter_Anf 255 "Fehler";
VAL_ 1511 KL_KM_ASV_01_Status 0 "Ventil nicht geschaltet" 1 "Ventil geschaltet" 2 "Ventil nicht verbaut" 3 "Fehler";
VAL_ 1511 KL_KM_ASV_02_Status 0 "Ventil nicht geschaltet" 1 "Ventil geschaltet" 2 "Ventil nicht verbaut" 3 "Fehler";
VAL_ 1511 KL_Vorwarn_HVHeizer_Leistung 0 "Init_Aus" 1 "500W" 2 "1000W" 3 "1500W" 4 "2000W" 5 "2500W" 6 "3000W" 7 "3500W" 8 "4000W" 9 "4500W" 10 "5000W" 11 "5500W" 12 "6000W" 13 "6500W" 14 "7000W" 15 "Fehler";
VAL_ 1511 KL_Status_EoHVL_EKK 0 "Init" 1 "Keine_offene_HV_Leitung_erkannt" 2 "offene_HV_Leitung_erkannt" 3 "Fehler";
VAL_ 1511 KL_Status_EoHVL_Heizer 0 "Init" 1 "Keine_offene_HV_Leitung_erkannt" 2 "offene_HV_Leitung_erkannt" 3 "Fehler";
VAL_ 1505 BCM1_Aussen_Temp_ungef 253 "nicht_verbaut" 254 "Initwert" 255 "Fehler";
VAL_ 1505 BCM_Heizungsabsperrventil_Status 0 "HAV_offen" 1 "HAV_geschlossen" 2 "Init_oder_nicht_verbaut" 3 "Fehler";
VAL_ 1505 BCM_Heizungspumpe_Status 0 "Pumpe_aus" 1 "Pumpe_aktiv_und_Stauts_iO" 2 "Init_oder_nicht_verbaut" 3 "Fehler";
VAL_ 1505 BCM_Kompressorkupplung_Status 0 "Kupplung_offen" 1 "Kupplung_geschlossen" 2 "Init_oder_nicht_verbaut" 3 "Fehler";
VAL_ 1505 BCM1_PTC_stufig_Status 0 "Aus" 1 "Stufe_1_aktiv" 2 "Stufe_2_aktiv" 3 "Stufe_3_aktiv" 6 "Init_oder_nicht_verbaut" 7 "Fehler";
VAL_ 1505 BCM1_FStatus_Aussentemp_ungef 0 "iO" 1 "niO";
VAL_ 1505 BCM1_Kompressorstrom_ist 254 "Init, bzw. nicht verfuegbar" 255 "Fehler";
VAL_ 1505 BCM1_OBD_FStatus_ATemp 0 "kein Fehler / Init / nicht verbaut" 1 "KS- (Kurzschluss nach minus)" 2 "KS+ (Kurzschluss nach plus)" 3 "OC (Leitungsunterbrechung)" 4 "OOR+ (Signal zu gross)" 5 "OOR- (Signal zu klein)" 6 "RC+ (Signal unplausibel zu gross)" 7 "RC- (Signal unplausibel zu klein)" 8 "KS+/OC (Kurzschluss nach plus/Unterbrechung)" 9 "KS-/OC  (Kurzschluss nach minus/Unterbrechung)" 10 "KS-/KS+  (Kurzschluss nach minus/plus)" 11 "KS-/KS+/OC (Kurzschluss nach minus/plus/Unterbrechung)" 12 "frei" 13 "frei" 14 "frei" 15 "frei";
VAL_ 2549088277 Airbag_01_KompSchutz 0 "inaktiv" 1 "aktiv";
VAL_ 2549088277 Airbag_01_Abschaltstufe 0 "keine_Einschraenkung" 1 "Funktionseinschraenkung";
VAL_ 2549088277 Airbag_01_Transport_Mode 0 "keine_Einschraenkung" 1 "Funktionseinschraenkung";
VAL_ 2549088277 Airbag_01_Nachlauftyp 0 "Komm_bei_KL15_EIN" 1 "Komm_nach_KL15_AUS" 2 "Komm_bei_KL15_AUS";
VAL_ 2549088277 NM_Airbag_01_Wakeup 0 "Peripherie_Wakeup__Ursache_nicht_bekannt" 1 "Bus_Wakeup" 2 "KL15_HW";
VAL_ 2549088277 KN_AB_DiagPfad 0 "aktiv" 1 "inaktiv";
VAL_ 2549088277 AB_KD_Fehler 0 "kein_KD_Fehler" 1 "KD_Fehler";
VAL_ 2549088380 EMotor_KompSchutz 0 "inaktiv" 1 "aktiv";
VAL_ 2549088380 EMotor_01_Abschaltstufe 0 "keine_Einschraenkung" 1 "Funktionseinschraenkung";
VAL_ 2549088380 EMotor_01_Transport_Mode 0 "keine_Einschraenkung" 1 "Funktionseinschraenkung";
VAL_ 2549088380 EMotor_Nachlauftyp 0 "Komm_bei_KL15_EIN" 1 "Komm_nach_KL15_AUS" 2 "Komm_bei_KL15_AUS";
VAL_ 2549088380 NM_EMotor_01_Wakeup 0 "Peripherie_Wakeup__Ursache_nicht_bekannt" 1 "Bus_Wakeup" 2 "KL15_HW";
VAL_ 2549088380 KN_EM_HYB_DiagPfad 0 "aktiv" 1 "inaktiv";
VAL_ 2549088380 EM_HYB_KD_Fehler 0 "kein_KD_Fehler" 1 "KD_Fehler";
VAL_ 2549088272 Gateway_KompSchutz 0 "inaktiv" 1 "aktiv";
VAL_ 2549088272 Gateway_Abschaltstufe 0 "keine_Einschraenkung" 1 "Funktionseinschraenkung";
VAL_ 2549088272 Gateway_Transport_Mode 0 "keine_Einschraenkung" 1 "Funktionseinschraenkung";
VAL_ 2549088272 Gateway_Nachlauftyp 0 "Komm_bei_KL15_EIN" 1 "Komm_nach_KL15_AUS" 2 "Komm_bei_KL15_AUS";
VAL_ 2549088272 NM_Gateway_Wakeup 128 "Energiemanagement" 0 "Peripherie_Wakeup__Ursache_nicht_bekannt" 129 "Funktionswakeup_OBDC" 1 "Bus_Wakeup" 130 "Hochvoltenergiemanagement" 2 "KL15_HW" 131 "CWU_empfangen" 3 "ACAN_Wakeup" 132 "Fuer_Bus_relevanten_FC_empfangen" 4 "FCAN_Wakeup" 133 "OnlineDienst_empfangen" 5 "KCAN_Wakeup" 134 "HV_Aktivieren" 6 "ICAN_Wakeup" 135 "HV_Deaktivieren" 7 "DiagCAN_Wakeup" 136 "VTS_Suche_DriverCard" 8 "ECAN_Wakeup" 137 "VTS_Hupen_Blinken" 9 "Energie_LIN_Wakeup" 138 "Remote_Vehicle_Status" 10 "Bedien_LIN_Wakeup" 139 "Plug_and_Charge" 11 "HybridCAN_Wakeup" 140 "VTS_Wakeup_Infotainment" 12 "Flexray_Wakeup" 141 "CCAN_Wakeup" 13 "MFL_WakeUp" 142 "NFcGW_fordert_OTA_FC_an" 14 "Ethernet" 15 "DCAN_Wakeup" 16 "K2CAN_Wakeup" 32 "FlexRay_Branch1_WakeUp" 33 "FlexRay_Branch2_WakeUp" 34 "FlexRay_Branch3_WakeUp" 35 "FlexRay_Branch4_WakeUp" 36 "FlexRay_Branch5_WakeUp" 37 "FlexRay_Branch6_WakeUp" 38 "FlexRay_Branch7_WakeUp" 39 "FlexRay_Branch8_WakeUp" 40 "FlexRay_Branch9_WakeUp" 41 "FlexRay_Branch10_WakeUp" 42 "FlexRay_Branch11_WakeUp" 43 "FlexRay_Branch12_WakeUp" 44 "FlexRay_Branch13_WakeUp" 45 "FlexRay_Branch14_WakeUp" 46 "FlexRay_Branch15_WakeUp" 47 "FlexRay_Branch16_WakeUp";
VAL_ 2549088272 KN_GW_DiagPfad 0 "aktiv" 1 "inaktiv";
VAL_ 2549088272 GW_KD_Fehler 0 "kein_KD_Fehler" 1 "KD_Fehler";
VAL_ 2549088440 LE2_KompSchutz 0 "inaktiv" 1 "aktiv";
VAL_ 2549088440 LE2_Abschaltstufe 0 "keine_Einschraenkung" 1 "Funktionseinschraenkung";
VAL_ 2549088440 LE2_Transport_Mode 0 "keine_Einschraenkung" 1 "Funktionseinschraenkung";
VAL_ 2549088440 LE2_Nachlauftyp 0 "Komm_bei_KL15_EIN" 1 "Komm_nach_KL15_AUS" 2 "Komm_bei_KL15_AUS";
VAL_ 2549088440 NM_LE2_Wakeup 0 "Peripherie_Wakeup__Ursache_nicht_bekannt" 1 "Bus_Wakeup" 2 "KL15_HW" 3 "KL_30__Reset";
VAL_ 2549088440 KN_LE2_DiagPfad 0 "aktiv" 1 "inaktiv";
VAL_ 2549088440 LE2_KD_Fehler 0 "kein_KD_Fehler" 1 "KD_Fehler";
VAL_ 2549088374 Motor_KompSchutz 0 "inaktiv" 1 "aktiv";
VAL_ 2549088374 MO_01_Abschaltstufe 0 "keine_Einschraenkung" 1 "Funktionseinschraenkung";
VAL_ 2549088374 MO_01_Transport_Mode 0 "keine_Einschraenkung" 1 "Funktionseinschraenkung";
VAL_ 2549088374 Motor_Nachlauftyp 0 "Komm_bei_KL15_EIN" 1 "Komm_nach_KL15_AUS" 2 "Komm_bei_KL15_AUS";
VAL_ 2549088374 KN_Motor_ECUKnockOutTimer 63 "ECUKnockOut_deaktiviert";
VAL_ 2549088374 KN_Motor_BusKnockOut 0 "Funktion_nicht_ausgeloest" 1 "Veto_aktiv" 2 "Funktion_ausgeloest" 3 "Funktion_deaktiviert";
VAL_ 2549088374 KN_Motor_BusKnockOutTimer 255 "BusKnockOut_deaktiviert";
VAL_ 2549088374 NM_MO_01_Wakeup 0 "Peripherie_Wakeup__Ursache_nicht_bekannt" 1 "Bus_Wakeup" 2 "KL15_HW" 3 "Oelstandsmessung" 4 "Evakuierung_SCR_System" 5 "Drucktankbetankung" 6 "KL50_HW" 7 "Fahrstufenwechsel";
VAL_ 2549088374 KN_Motor_ECUKnockOut 0 "Funktion_nicht_ausgeloest" 1 "Veto_war_aktiv" 2 "Funktion_ausgeloest" 3 "Funktion_deaktiviert";
VAL_ 2549088374 KN_MO_DiagPfad 0 "aktiv" 1 "inaktiv";
VAL_ 2549088374 MO_KD_Fehler 0 "kein_KD_Fehler" 1 "KD_Fehler";
VAL_ 982 LH_Aussenlicht_def 0 "OK" 1 "defekt";
VAL_ 982 LH_Standlicht_H_aktiv 1 "Standlicht hinten aktiv";
VAL_ 982 LH_Parklicht_HL_aktiv 0 "nicht aktiv" 1 "Parklicht hinten links aktiv";
VAL_ 982 LH_Parklicht_HR_aktiv 0 "nicht aktiv" 1 "Parklicht hinten rechts aktiv";
VAL_ 982 LH_Bremslicht_H_aktiv 1 "Bremslicht hinten aktiv";
VAL_ 982 LH_Nebelschluss_aktiv 0 "nicht aktiv" 1 "aktiv";
VAL_ 982 LH_Rueckfahrlicht_aktiv 0 "nicht aktiv" 1 "aktiv";
VAL_ 982 LH_Blinker_HL_akt 1 "Blinker hinten links aktiv";
VAL_ 982 LH_Blinker_HR_akt 1 "Blinker hinten rechts aktiv";
VAL_ 982 LH_Blinker_li_def 0 "OK" 1 "Blinker hinten links defekt";
VAL_ 982 LH_Bremsl_li_def 0 "OK" 1 "mindestens ein Bremslicht hinten links defekt";
VAL_ 982 LH_Schlusslicht_li_def 0 "OK" 1 "mindestens ein Schlusslicht hinten links defekt";
VAL_ 982 LH_Rueckf_li_def 0 "OK" 1 "Rückfahrlicht hinten links defekt";
VAL_ 982 LH_Nebel_li_def 0 "OK" 1 " Nebelschlusslicht hinten links defekt";
VAL_ 982 LH_Schluss_Brems_Nebel_li_def 0 "iO" 1 "defekt";
VAL_ 982 LH_Schluss_Brems_Nebel_re_def 0 "iO" 1 "defekt";
VAL_ 982 LH_Zusatzschlussl_def 0 "OK" 1 "mindestens_ein_Zusatzschlusslicht_defekt";
VAL_ 982 LH_Schluss_Brems_li_def 0 "OK" 1 "defekt";
VAL_ 982 LH_Schluss_Nebel_li_def 0 "OK" 1 "defekt";
VAL_ 982 LH_SL_BRL_BLK_li_def 0 "OK" 1 "defekt";
VAL_ 982 LH_Brems_Blk_li_def 0 "OK" 1 "defekt";
VAL_ 982 LH_Diag_Status_re_def 0 "OK" 1 "Aussenlict_Diagnose_Systemstoerung_rechts";
VAL_ 982 LH_Diag_Status_li_def 0 "OK" 1 "Aussenlicht_Diagnose_Systemstoerung_links";
VAL_ 982 LH_Diag_LED_li_def 0 "OK" 1 "Heckleuchte_links_defekt";
VAL_ 982 LH_Diag_LED_re_def 0 "OK" 1 "Heckleuchte_rechts_defekt";
VAL_ 982 LH_Blinker_re_def 0 "OK" 1 "Blinker hinten rechts defekt";
VAL_ 982 LH_Bremsl_re_def 0 "OK" 1 "mindestens ein Bremslicht hinten rechts defekt";
VAL_ 982 LH_Schlusslicht_re_def 0 "OK" 1 "mindestens ein Schlusslicht hinten rechts defekt";
VAL_ 982 LH_Rueckf_re_def 0 "OK" 1 "Rückfahrlicht hinten rechts defekt";
VAL_ 982 LH_Nebel_re_def 0 "OK" 1 "Nebelschlusslicht hinten rechts defekt";
VAL_ 982 LH_Schluss_Brems_mi_def 0 "OK" 1 "Defekt";
VAL_ 982 LH_Schluss_Brems_re_def 0 "OK" 1 "defekt";
VAL_ 982 LH_Schluss_Nebel_re_def 0 "OK" 1 "defekt";
VAL_ 982 LH_SL_BRL_BLK_re_def 0 "OK" 1 "defekt";
VAL_ 982 LH_Brems_Blk_re_def 0 "OK" 1 "defekt";
VAL_ 982 LH_Kennzl_def 0 "OK" 1 "Kennzeichenbeleuchtung hinten defekt";
VAL_ 982 LH_3_Bremsl_def 0 "OK" 1 "hochgesetzte  Bremsleuchte defekt";
VAL_ 982 LH_Nebel_mi_def 0 "OK" 1 " Nebelschlusslicht hinten Mitte defekt";
VAL_ 982 LH_Rueckf_mi_def 0 "OK" 1 "Rückfahllicht Mitte defekt";
VAL_ 982 LH_Schlusslicht_mi_def 0 "OK" 1 "defekt";
VAL_ 982 LH_Bremsl_li_ges_def 0 "OK" 1 "Alle Bremslichter hinten links defekt";
VAL_ 982 LH_Bremsl_re_ges_def 0 "OK" 1 "Alle Bremslichter hinten rechts defekt";
VAL_ 982 LH_Bremsl_mi_def 0 "OK" 1 "defekt";
VAL_ 982 BRL_als_SHL 0 "nicht_aktiv" 1 "aktiv";
VAL_ 134 LWI_Sensorstatus 0 "iO" 1 "nicht kalibriert";
VAL_ 134 LWI_QBit_Sub_Daten 0 "LWS-Subinfo 'real' (Lenkradwinkelinformation ADS-tauglich) " 1 "LWS-Subinfo 'simuliert' (Lenkradwinkelinformation nicht ADS-tauglich )";
VAL_ 134 LWI_QBit_Lenkradwinkel 0 "gültiger Wert" 1 "ausserhalb der Spezifikation";
VAL_ 134 LWI_Lenkradwinkel 8190 "Init" 8191 "Fehler";
VAL_ 134 LWI_VZ_Lenkradwinkel 0 "positiv_links_von_der_Nullstellung" 1 "negativ";
VAL_ 134 LWI_VZ_Lenkradw_Geschw 0 "positiv_links_von_der_Nullstellung" 1 "negativ";
VAL_ 134 LWI_Lenkradw_Geschw 510 "Init" 511 "Fehler";
VAL_ 817 MFL_Lokalaktiv 0 "war_nicht_lokal_aktiv" 1 "war_lokal_aktiv";
VAL_ 817 MFL_M_Taste 0 "nicht_betaetigt" 1 "betaetigt";
VAL_ 817 MFL_Paddle_Verbau 0 "verbaut" 1 "nicht_verbaut";
VAL_ 817 MFL_Tastencode_1 0 "Key_Released__No_Key" 1 "Context_Menu" 2 "Menu_Up__Next_Screen" 3 "Menu_Down__Previous_Screen" 4 "Up" 5 "Down" 6 "Up__Down_ThumbWheel" 7 "OK__ThumbWheel_Button" 8 "Cancel__Escape" 9 "Main_Menu" 10 "Side_Menu_left" 11 "Side_Menu_right" 12 "FAS_Menu" 13 "Left__Right_ThumbWheel" 16 "Volume_Up" 17 "Volume_Down" 18 "Volume_Up__Down_ThumbWheel" 19 "Volume_ThumbWheel_Button" 20 "Audio_Source" 21 "Arrow_A_Up__Right" 22 "Arrow_A_Down__Left" 23 "Arrow_B_Up__Right" 24 "Arrow_B_Down__Left" 25 "PTT__PushToTalk" 26 "PTT_Cancel" 27 "Route_Info" 28 "Hook" 29 "Hang_Up" 30 "Off_Hook" 31 "Light_On__Off" 32 "Mute" 33 "Joker1" 34 "Joker2" 35 "View" 100 "MAP" 36 "Arrow_A_Up__Down_ThumbWheel" 101 "MAP_Boost" 37 "Lenkradheizung" 102 "Turn_signal_left" 38 "Rekuperation" 103 "Turn_signal_right" 39 "Tube_Toggle" 104 "Turn_signal_off" 105 "Flashlight" 106 "Highbeam" 107 "Washer_button" 108 "Wiper_button_left" 109 "Wiper_button_right" 110 "Wiper_button_cancel" 111 "Exhaust_Sound" 240 "Startup_Reset" 112 "Drive_Select_button" 241 "Initialization" 113 "Sport_button" 114 "ESP_Drift_Selection_ThumbWheel" 115 "PTT_special_vehicle" 116 "TravelAssist";
VAL_ 817 MFL_Tastencode_2 0 "Key_Released__No_Key" 1 "Context_Menu" 2 "Menu_Up__Next_Screen" 3 "Menu_Down__Previous_Screen" 4 "Up" 5 "Down" 6 "Up__Down_ThumbWheel" 7 "OK__ThumbWheel_Button" 8 "Cancel__Escape" 9 "Main_Menu" 10 "Side_Menu_left" 11 "Side_Menu_right" 12 "FAS_Menu" 13 "Left__Right_ThumbWheel" 16 "Volume_Up" 17 "Volume_Down" 18 "Volume_Up__Down_ThumbWheel" 19 "Volume_ThumbWheel_Button" 20 "Audio_Source" 21 "Arrow_A_Up__Right" 22 "Arrow_A_Down__Left" 23 "Arrow_B_Up__Right" 24 "Arrow_B_Down__Left" 25 "PTT__PushToTalk" 26 "PTT_Cancel" 27 "Route_Info" 28 "Hook" 29 "Hang_Up" 30 "Off_Hook" 31 "Light_On__Off" 32 "Mute" 33 "Joker1" 34 "Joker2" 35 "View" 100 "MAP" 36 "Arrow_A_Up_Right_Down_Left_ThumbWheel" 101 "MAP_Boost" 37 "Lenkradheizung" 102 "Turn_signal_left" 38 "Rekuperation" 103 "Turn_signal_right" 39 "Tube_Toggle" 104 "Turn_signal_off" 105 "Flashlight" 106 "Highbeam" 107 "Washer_button" 108 "Wiper_button_left" 109 "Wiper_button_right" 110 "Wiper_button_cancel" 111 "Exhaust_Sound" 240 "Startup_Reset" 112 "Drive_Select_button" 241 "Initialization" 113 "Sport_button" 114 "ESP_Drift_Selection_ThumbWheel" 115 "PTT_special_vehicle" 116 "TravelAssist";
VAL_ 817 MFL_Eventcode_1 0 "W_no_event____T_no_event" 1 "W_1_Tick_up__T_pressed_normal" 2 "W_2_Ticks_up__T_touched" 3 "W_3_Ticks_up__T_double_click_nor" 4 "W_4_Ticks_up__T_long_press_nor_1" 5 "W_5_Ticks_up__T_long_press_nor_2" 6 "W_6_Ticks_up__T_long_press_nor_3" 7 "W_7_Ticks_up" 9 "W_7_Ticks_dn__T_pressed_strong" 10 "W_6_Ticks_dn" 11 "W_5_Ticks_dn__T_double_click_str" 12 "W_4_Ticks_dn__T_long_press_str_1" 13 "W_3_Ticks_dn__T_long_press_str_2" 14 "W_2_Ticks_dn__T_long_press_str_3" 15 "W_1_Tick_dn";
VAL_ 817 MFL_Eventcode_2 0 "W_no_event____T_no_event" 1 "W_1_Tick_up__T_pressed_normal" 2 "W_2_Ticks_up__T_touched" 3 "W_3_Ticks_up__T_double_click_nor" 4 "W_4_Ticks_up__T_long_press_nor_1" 5 "W_5_Ticks_up__T_long_press_nor_2" 6 "W_6_Ticks_up__T_long_press_nor_3" 7 "W_7_Ticks_up" 9 "W_7_Ticks_dn__T_pressed_strong" 10 "W_6_Ticks_dn" 11 "W_5_Ticks_dn__T_double_click_str" 12 "W_4_Ticks_dn__T_long_press_str_1" 13 "W_3_Ticks_dn__T_long_press_str_2" 14 "W_2_Ticks_dn__T_long_press_str_3" 15 "W_1_Tick_dn";
VAL_ 817 MFL_Marke 0 "VW" 1 "Audi" 2 "Seat" 3 "Skoda" 4 "VW_Nutzf" 5 "Bugatti" 6 "Lamborghini" 7 "Bentley" 8 "Rolls Royce" 9 "Quattro" 10 "kein_Hersteller_1" 11 "kein_Hersteller_2" 12 "kein_Hersteller_3" 13 "kein_Hersteller_4" 14 "Ford" 15 "Porsche";
VAL_ 817 MFL_Tip_Down 0 "nicht_betaetigt" 1 "betaetigt";
VAL_ 817 MFL_Tip_Up 0 "nicht_betaetigt" 1 "betaetigt";
VAL_ 817 MFL_SatModul_links_Err 0 "kein_Fehler" 1 "Fehler";
VAL_ 817 MFL_SatModul_rechts_Err 0 "kein_Fehler" 1 "Fehler";
VAL_ 817 MFL_LR_HZG_Status 0 "inaktiv" 1 "aktiv";
VAL_ 817 MFL_LR_HZG_Err 0 "normal" 1 "Fehler";
VAL_ 817 MFL_Signalhorn 0 "nicht_betaetigt" 1 "betaetigt";
VAL_ 817 MFL_Signalhorn_Err 0 "normal" 1 "Fehler";
VAL_ 817 MFL_Tip_links_Err 0 "normal" 1 "Fehler";
VAL_ 817 MFL_Tip_rechts_Err 0 "normal" 1 "Fehler";
VAL_ 817 MFL_Taste_links_Err 0 "normal" 1 "Fehler";
VAL_ 817 MFL_Taste_rechts_Err 0 "normal" 1 "Fehler";
VAL_ 817 MFL_ECU_Err 0 "normal" 1 "Fehler";
VAL_ 817 MFL_Response_Err 0 "normal" 1 "Fehler";
VAL_ 15 MO_SOPC 0 "kein_SOPC" 1 "SOPC";
VAL_ 1600 MO_QBit_Ansaugluft_Temp 0 "gueltiger_Wert" 1 "Ersatz_Init_oder_Fehlerwert";
VAL_ 1600 MO_QBit_Oel_Temp 0 "gueltiger_Wert" 1 "Ersatz_Init_oder_Fehlerwert";
VAL_ 1600 MO_QBit_Kuehlmittel_Temp 0 "gueltiger_Wert" 1 "Ersatz_Init_oder_Fehlerwert";
VAL_ 1600 MO_KL15_Abschaltempfehlung 0 "Keine Empfehlung" 1 "Abschaltempfehlung";
VAL_ 1600 MO_HYB_Fehler_HV_Netz 0 "i_O" 1 "kein_generatorischer_Betrieb_moeglich";
VAL_ 1600 MO_aktives_Getriebeheizen 0 "kein_Ventil_ansteuern" 1 "Ventil_muss_angesteuert_werden";
VAL_ 1600 MO_Absperrventil_oeffnen 0 "nicht_verfuegbar" 1 "Ansteuerung_Ventil_zulaessig" 2 "Ventil_oeffnen_oder_geoeffnet" 3 "Ventil_schliessen_oder_geschlossen";
VAL_ 1600 MO_Ansaugluft_Temp 254 "Init" 255 "Fehler";
VAL_ 1600 MO_Oel_Temp 253 "nicht_verbaut" 254 "Init" 255 "Fehler";
VAL_ 1600 MO_Kuehlmittel_Temp 254 "Init" 255 "Fehler";
VAL_ 1600 MO_Hoeheninfo 255 "Fehler";
VAL_ 1600 MO_Kennfeldk 0 "keine Kennfeldkühlung vorhanden" 1 "Kennfeldkühlung vorhanden";
VAL_ 1600 MO_Versionsinfo_02 16 "MQB_mit_neuer_Momentenschnittstelle" 0 "zum_Projektbeginn_aufgeraeumter_CAN" 1 "Motor_03_mit_10ms";
VAL_ 1600 MO_QBit_Hoeheninfo 0 "gueltiger_Wert" 1 "Ersatz_Init_oder_Fehlerwert";
VAL_ 1600 MO_Getriebe_kuehlen 0 "nicht_kuehlen" 1 "kuehlen";
VAL_ 1600 MO_Heizungspumpenansteuerung 13 "Fehler" 14 "Init" 15 "nicht_verbaut";
VAL_ 1600 MO_SpannungsAnf 0 "keine_Anforderung" 1 "Anforderung";
VAL_ 167 MO_Mom_Soll_Roh 1022 "Init";
VAL_ 167 MO_Mom_Ist_Summe 1022 "Init";
VAL_ 167 MO_Mom_Traegheit_Summe 1022 "Init";
VAL_ 167 MO_Mom_Soll_gefiltert 1022 "Init";
VAL_ 167 MO_Mom_Schub 510 "Init";
VAL_ 167 MO_Status_Normalbetrieb_01 0 "kein_Normalbetrieb" 1 "Normalbetrieb_erreicht";
VAL_ 167 MO_erste_Ungenauschwelle 0 "genau" 1 "Momente ungenauer >8%";
VAL_ 167 MO_QBit_Motormomente 0 "gueltiger_Wert" 1 "Ersatz_Init_oder_Fehlerwert";
VAL_ 168 MO_Mom_neg_verfuegbar 510 "Init" 511 "Fehler";
VAL_ 168 MO_Mom_Begr_Fahr 510 "Init" 511 "Fehler";
VAL_ 168 MO_Mom_Begr_Schalt 1022 "Init";
VAL_ 168 MO_QBit_Drehzahl_01 0 "gueltiger_Wert" 1 "Ersatz_Init_oder_Fehlerwert";
VAL_ 958 MO_StartStopp_Status 0 "System_in_diesem_KL15_Zyklus_nicht_verfuegbar" 1 "System_aktiv_keine_Freigabe_durch_StartStop_Koordinator" 2 "System_aktiv_alle_Freigaben_liegen_vor" 3 "System_aktiv_mindestens_eine_Freigabe_fehlt";
VAL_ 958 MO_StartStopp_Wiederstart 0 "Wiederstart_inaktiv" 1 "Wiederstart_aktiv";
VAL_ 958 MO_StartStopp_Motorstopp 0 "Motor_Stop_inaktiv" 1 "Motor_Stop_aktiv";
VAL_ 958 MO_Freig_Reku 0 "Rekuperations-Modus aus" 1 "Empfehlung Spannungsanhebung" 2 "Empfehlung Spannungsabsenkung" 3 "Rekuperationsmodus aktiv, Spannungsvariation nicht notwendig";
VAL_ 958 MO_Kl_75 0 "Aus" 1 "Ein";
VAL_ 958 MO_Kl_50 0 "aus" 1 "KL50_ein_Startausfuehrung_Fahrer";
VAL_ 958 MO_Gangposition 0 "Gang_N" 1 "Gang_1" 2 "Gang_2" 3 "Gang_3" 4 "Gang_4" 5 "Gang_5" 6 "Gang_6" 7 "Gang_7" 8 "Gang_8" 9 "Automat_P" 10 "Automat_Vorwaerts_S" 11 "Automat_Vorwaerts_D/E" 12 "Zwischenstellung" 13 "Gang_R" 14 "Istgang_nicht_definiert" 15 "Fehler";
VAL_ 958 MO_StartStopp_Fahrerwunsch 0 "Init" 1 "Stoppverbot_durch_Fahrer" 2 "Stoppfreigabe_durch_Fahrer" 3 "Stoppanforderung_durch_Fahrer";
VAL_ 958 MO_HYB_Fahrbereitschaft 0 "keine_Fahrbereitschaft" 1 "Fahrbereitschaft";
VAL_ 958 MO_Ext_E_Fahrt_aktiv 0 "Rueckmeldung_E_Taster_aus" 1 "Rueckmeldung_E_Taster_ein";
VAL_ 958 MO_Fahrer_bremst 0 "kein_Bremsen" 1 "Bremse_betaetigt";
VAL_ 958 MO_QBit_Fahrer_bremst 0 "gueltiger_Wert" 1 "Ersatz_Init_oder_Fehlerwert";
VAL_ 958 MO_BLS 0 "kein_Bremsen" 1 "Bremse_betaetigt";
VAL_ 958 MO_Konsistenz_Bremsped 0 "Bremspedalinformation_plausibel" 1 "Bremspedalinformation_unplausibel";
VAL_ 958 MO_Timeout_ESP 0 "Empfang_iO" 1 "Timeout";
VAL_ 958 MO_Klima_Eingr 0 "kein Eingriff" 1 "Klimakompressor ausschalten" 2 "Klimakompressor Leistungsreduzierung" 3 "Klimakompressor aufgrund der Heissleuchtenvorwarnung ausschalten";
VAL_ 958 MO_Aussp_Anlass 0 "Anlasser_darf_angesteuert_werden" 1 "Anlasser_ausspuren__Ansteuerung_nicht_moeglich";
VAL_ 958 MO_Freig_Anlass 0 "Start_nicht_zulaessig" 1 "Startfreigabe";
VAL_ 958 MO_Kuppl_schalter 0 "Schalter_sagt_ausgekuppelt" 1 "Schalter_sagt_eingekuppelt";
VAL_ 958 MO_Interlock 0 "Interlockschalter_nicht_betaetigt" 1 "Interlockschalter_betaetigt";
VAL_ 958 MO_Motor_laeuft 0 "Motor_laeuft_nicht" 1 "Motor_laeuft_autark_und_stabil_und_darf_mechanisch_belastet_werden";
VAL_ 958 MO_Kickdown 0 "kein_Kickdown" 1 "Kickdown";
VAL_ 958 MO_QBit_KL_75 0 "gueltiger_Wert" 1 "Ersatz_Init_oder_Fehlerwert";
VAL_ 958 MO_EKlKomLeiRed 0 "keine_Leistungsbegr" 1 "Leistungsbegr_75" 2 "Leistungsbegr_50" 3 "Leistungsbegr_25";
VAL_ 958 MO_Handshake_STH 0 "keine EKP-Ansteuerung durch STH-Anforderung" 1 "EKP-Ansteuerung durch STH-Anforderung";
VAL_ 958 MO_BKV_Unterdruckwarnung 0 "Unterdruckhaushalt_iO" 1 "Unterdruckhaushalt_niO";
VAL_ 958 MO_Freigabe_Segeln 0 "Segelbetrieb_nicht_freigegeben" 1 "Segelbetrieb_freigegeben";
VAL_ 958 MO_PTC_Status 0 "nicht_unterstuetzt" 1 "Stufe_0" 2 "Stufe_1" 3 "Stufe_2" 4 "Stufe_3" 7 "PTC_am_BCM";
VAL_ 958 MO_QBit_Gangposition 0 "gueltiger_Wert" 1 "Ersatz_Init_oder_Fehlerwert";
VAL_ 958 MO_Signalquelle_Gangposition 0 "Sensorsignal" 1 "Modellsignal";
VAL_ 958 MO_Remotestart_Betrieb 0 "MSG_nicht_bereit_fuer_RS_Betrieb" 1 "MSG_bereit_fuer_oder_im_RS_Betrieb";
VAL_ 958 MO_Remotestart_moeglich 0 "Remotestart_nicht_moeglich" 1 "Remotestart_moeglich";
VAL_ 958 MO_FMAus_aktiv 0 "inaktiv" 1 "Segeln_mit_Motor_aus_aktiv";
VAL_ 958 MO_FMAus_Startvariante 0 "kein_Motorstart" 1 "Motorstart_elektrischer_Starter" 2 "GetriebeAnschleppstart" 3 "GetriebeNotAnschleppstart";
VAL_ 958 MO_BMS_NV_Anf_stuetzen 0 "nicht_notwendig" 1 "notwendig";
VAL_ 958 MO_Zylinderabschaltung 0 "Vollmotorbetrieb_VMB" 1 "Uebergang_HMB_in_VMB" 2 "Uebergang_VMB_in_HMB" 3 "Halbmotorbetrieb_HMB";
VAL_ 958 MO_HYB_VM_aktiv 0 "VM_nicht_aktiv" 1 "VM_aktiv";
VAL_ 958 MO_StartVorauss_erfuellt 0 "Signal_nicht_bedient" 1 "StartVorauss_nicht_ueberpruefbar" 2 "StartVorauss_nicht_erfuellt" 3 "StartVorauss_erfuellt";
VAL_ 1631 TSK_QBit_Steigung 0 "gueltiger_Wert" 1 "Ersatz_Init_oder_Fehlerwert";
VAL_ 1631 TSK_QBit_Fahrzeugmasse 0 "gueltiger_Wert" 1 "Ersatz_Init_oder_Fehlerwert";
VAL_ 1631 MO_SpannungsAnf_02 0 "keine_Anforderung" 1 "Anforderung_Stufe_1" 2 "Anforderung_Stufe_2" 3 "Anforderung_Stufe_3";
VAL_ 1631 MO_DPF_reg 0 "DPF_regeneriert_nicht" 1 "DPF_regeneriert";
VAL_ 1631 MO_Heizstrom_EKAT 127 "Fehler";
VAL_ 1631 MO_Heizstrom_SCR 63 "Fehler";
VAL_ 1631 MO_P_Generator_ungefiltert_Anf 0 "nicht_angefordert" 1 "angefordert";
VAL_ 1631 TSK_Getriebeinfo 0 "Handschalter" 1 "AL_AQ_Getriebe" 2 "DL_DQ_Getriebe" 3 "CVT_Getriebe";
VAL_ 1631 MO_Energieinhalt_BMS 4094 "Init" 4095 "Fehler";
VAL_ 1631 TSK_Fahrzeugmasse_02 255 "Fehler";
VAL_ 1631 TSK_Steigung_02 0 "Init_oder_nicht_verbaut" 255 "Fehler";
VAL_ 1648 MO_ANC_Kennfeld_Anf 0 "Kennfeld_1" 1 "Uebergang_Kennfeld_2_nach_1" 2 "Uebergang_Kennfeld_1_nach_2" 3 "Kennfeld_2";
VAL_ 1648 MO_Bremslicht_Reku 0 "Aus" 1 "Ein";
VAL_ 1648 MO_StartStopp_PopUp 0 "Statuswechsel_ohne_Taster (Init)" 1 "StSt_per_Taster_deaktiviert" 2 "StSt_per_Taster_aktiviert" 3 "nicht verwendet";
VAL_ 1648 MO1_Sperr_Info_WFS 0 "nicht_gesperrt" 1 "gesperrt";
VAL_ 1648 MO1_Freigabe_Info_WFS 0 "ungueltig" 1 "gueltig";
VAL_ 1648 MO_EPCL 0 "EPCL_aus_kein_Text" 1 "EPCL_gelb_Stoerung" 2 "EPCL_gelb_Leistungsbeschraenkung" 3 "EPCL_rot_Fzg_sicher_abstellen";
VAL_ 1648 MO_Zylabsch_Texte_02 0 "ein_ZAS_generell_keine_ZAS_Anzeigen" 1 "ZAS_im_VMB" 2 "ZAS_im_ASB_1_Zyl_aktiv" 3 "ZAS_im_ASB_2_Zyl_aktiv" 4 "ZAS_im_ASB_3_Zyl_aktiv" 5 "ZAS_im_ASB_4_Zyl_aktiv" 6 "ZAS_im_ASB_5_Zyl_aktiv" 7 "ZAS_im_ASB_6_Zyl_aktiv" 8 "ZAS_im_ASB_8_Zyl_aktiv" 9 "ZAS_im_ASB_12_Zyl_aktiv" 13 "Uebergangsbetrieb" 14 "keine_ZAS_Anzeige_ggf_Stopp_Schub_Betrieb" 15 "ZAS_Stoerungs_Anzeige";
VAL_ 1648 MO_Fahrzeugtyp 0 "Verbrenner_Fahrzeug" 1 "Hybrid" 2 "E_Fahrzeug" 3 "E_Fahrzeug_mit_Range_Extender" 4 "Brennstoffzellenfahrzeug" 5 "tbd" 6 "tbd" 7 "tbd";
VAL_ 1648 MO_Abstellzeit 254 "Init" 255 "reserviert";
VAL_ 1648 MO_Abstellzeit_Status 0 "Abstellzeit_nicht_berechnet" 1 "Abstellzeit_berechnet" 2 "Abstellzeit_Minimalwert" 3 "Abstellzeit_ungueltig";
VAL_ 1648 MO1_Freigabe_Verfallsinfo_WFS 0 "verfaellt_nicht" 1 "verfaellt";
VAL_ 1648 MO_Hybrid_StartStopp_LED 0 "LED_aus_und_Blinken_aus" 1 "LED_ein_und_Blinken_aus" 2 "LED_ein_und_Blinken_ein_50_percent" 3 "reserviert";
VAL_ 1648 MO_Fehler_Zylabsch 0 "kein_Fehler" 1 "Notlauf_Vollmotorbetrieb" 2 "Notlauf_mindestens_einem_abgesch_Zylinder";
VAL_ 1648 MO_Anzahl_Abgesch_Zyl 0 "Vollmotorbetrieb" 1 "1_Zylinder_abgeschaltet" 2 "2_Zylinder_abgeschaltet" 3 "3_Zylinder_abgeschaltet" 4 "4_Zylinder_abgeschaltet" 5 "5_Zylinder_abgeschaltet" 6 "6_Zylinder_abgeschaltet" 7 "8_Zylinder_abgeschaltet";
VAL_ 1648 MO_Zylabsch_Texte 0 "keine_Texte" 1 "Zylinderabschaltung_deaktivieren" 2 "Zylinderabschaltung_aktivieren" 3 "Zylinderabschaltung_unruhig";
VAL_ 1648 MO_Ethanol_BS_Texte 0 "kein_Text" 1 "E85_Warm_Up" 2 "FlexFuel_Warnung_Stufe_3" 3 "Warmfahrempfehlung_MQB__FlexFuel_Warnung_Stufe_1" 4 "FlexFuel_Warnung_Stufe_2" 5 "FlexFuel_Warnung_Stufe_4" 6 "E25_Warm_Up";
VAL_ 1648 MO_Drehzahl_Warnung 0 "keinen_Warnhinweis_anzeigen" 1 "Warnhinweis_anzeigen";
VAL_ 1648 MO_obere_Drehzahlgrenze 0 "Init";
VAL_ 967 MO_Kuehlerluefter_MUX 0 "Kuehlerluefter_1" 1 "Kuehlerluefter_2";
VAL_ 967 MO_Kuehlerluefter_1 126 "Init" 127 "Fehler";
VAL_ 967 MO_Kuehlerluefter_2 126 "Init" 127 "Fehler";
VAL_ 967 MO_EFLEX_Lampe 0 "Lampe_aus" 1 "Lampe_ein" 2 "Lampe_blinkend" 3 "Lampe_blinkend_mit_Akustik";
VAL_ 967 MO_KJS_nicht_bereit 0 "kein_Fehler" 1 "Fehler";
VAL_ 967 MO_ITM_Warnung_Pumpe 0 "keine_Warnung" 1 "ITM_Warnung";
VAL_ 967 WIV_Anzeige_aktiv 0 "Anzeige aus" 1 "WIV Anzeige aktiv";
VAL_ 967 WIV_Oelmin_Warn 0 "in_Ordnung" 1 "Warnung";
VAL_ 967 WIV_Sensorfehler 0 "in_Ordnung" 1 "Sensor_defekt";
VAL_ 967 WIV_Schieflage 0 "Fahrzeug_gerade" 1 "Fahrzeug_in_Schieflage";
VAL_ 967 MO_Zustand_HWP 0 "HWP_nicht_schaltbar" 1 "HWP_foerdert_nicht" 2 "HWP_foerdert" 3 "reserviert";
VAL_ 967 OLEV_Systemstoerung 0 "Ölsystem i.O." 1 "Systemstörung Ölsystem";
VAL_ 967 MO_Oelwarnung_max 0 "keine_Warnung" 1 "Warnfall_aktiv";
VAL_ 967 WIV_Oelsystem_aktiv 0 "Anzeige_aus" 1 "Anzeige_aktiv";
VAL_ 967 WIV_nicht_betriebswarm 0 "Motor_warm" 1 "Motor_nicht_betriebswarm";
VAL_ 967 WIV_Ueberfuell_Warn 0 "in_Ordnung" 1 "Ueberfuellwarnung";
VAL_ 967 WIV_laufender_Motor 0 "Messung_moeglich" 1 "Messung_nicht_moeglich";
VAL_ 967 MO_E_Warnungen 0 "keine_Anzeige" 1 "Fehler_Elektrosystem_Anhalten" 2 "Fehler_Elektrosystem_Werkstatt" 3 "Elektrosystem_ueberhitzt_Stopp" 4 "Fehler_Hybridsystem_Anhalten" 5 "Fehler_Hybridsystem_Werkstatt" 6 "Fehler_Wasserstoffsystem_Anhalte" 7 "Fehler_Wasserstoffsystem_Werksta" 8 "reserviert_keine_Anzeige" 9 "reserviert_keine_Anzeige" 10 "reserviert_keine_Anzeige" 11 "reserviert_keine_Anzeige" 12 "reserviert_keine_Anzeige" 13 "reserviert_keine_Anzeige" 14 "reserviert_keine_Anzeige" 15 "reserviert_keine_Anzeige";
VAL_ 967 MO_Text_Motorstart 0 "keine_Anzeige" 9 "Unerwuenschter_Motorstillstand" 1 "Motor_im_Stoppbetrieb" 2 "StartStopp_sicherheitsbedingt_deaktiviert" 3 "System_fordert_Wiederstart" 4 "Aufforderung_Motorstart" 5 "Motorlauf_noetig" 6 "Motorlaufwarnung" 10 "Motorstart_nicht_moeglich" 11 "Fehler_Kupplungsschalter" 12 "Motor_startet" 13 "Kupplung_betaetigen" 14 "Waehlhebel_in_PN_Position" 15 "Bremse_treten";
VAL_ 967 MO_E_Texte 0 "keine_Anzeige" 1 "Batterie_fast_leer" 2 "Ladestecker_nicht_fahrbereit" 3 "VM_Betrieb_erforderlich" 4 "Batterie_laedt_Nicht_ausschalten" 5 "Bitte_Bremse_treten" 6 "manueller_Neustart_erforderlich" 7 "Stopp_Fahrzeug_nicht_abschleppen" 8 "kein_Neustart_Haube_nicht_oeffnen" 9 "Motorstart_im_naechsten_Zyklus" 10 "VM_erforderlich_EVMode_abwaehlen" 11 "laengerer_VMBetrieb_Bordbuch" 12 "Tank_leer_VM_nicht_verfuegbar" 13 "Bitte_warten_Motor_startet" 14 "kein_Start_Batterietemperatur" 15 "Ende_elektrische_Reichweite_erreicht";
VAL_ 967 WIV_Oeldyn_avl 0 "Oeldyn_nicht_vorhanden" 1 "Oeldyn_vorhanden";
VAL_ 967 OLEV_Oelstand_nicht_vorhanden 0 "Ölstand vorhanden" 1 "Ölstand nicht vorhanden";
VAL_ 967 MO_Systemlampe 0 "Lampe aus" 1 "Lampe ein";
VAL_ 967 MO_OBD2_Lampe 0 "Lampe aus" 1 "Lampe ein";
VAL_ 967 MO_Heissleuchte 0 "Lampe aus" 1 "Lampe ein";
VAL_ 967 MO_Partikel_Lampe 0 "Lampe aus" 1 "Lampe ein";
VAL_ 967 MO_RedFahrleistung_Lampe 0 "Lampe_aus" 1 "Lampe_ein";
VAL_ 967 WIV_Oelstand_nicht_vorhanden 0 "Ölstand vorhanden" 1 "Ölstand nicht vorhanden";
VAL_ 967 WIV_nachfuellanzeige_ein 0 "keine_Nachfuellanzeige" 1 "Nachfuellanzeige";
VAL_ 967 WIV_Ueberfuell_deaktiv 0 "Ueberfuellwarnung_am_Kombi_aktiv" 1 "Ueberfuellwarnung_am_Kombi_deaktiv";
VAL_ 967 WIV_Unterfuell_Warn 0 "in_Ordnung" 1 "Unterfuellwarnung";
VAL_ 967 MO_Tankdeckel_Lampe 0 "Lampe aus" 1 "Lampe ein";
VAL_ 967 MO_Text_Tankdeckelwarn 0 "kein_Text" 1 "Anzeige_Text_Tankdeckelwarnung_im_Kombi";
VAL_ 967 MO_Vorglueh_Lampe 0 "Lampe_aus" 1 "Lampe_ein";
VAL_ 967 WIV_Oeldr_Warn_Motor 0 "keine_Warnung" 1 "niedrige_Oeldruckstufe_nicht_erreicht";
VAL_ 967 MO_E_Mode 0 "keine_Anzeige" 1 "E_Mode_passiv" 2 "E_Mode_aktiv" 3 "E_Mode_inaktiv_nicht_verfuegbar" 4 "E_Mode_aktiv_nicht_verfuegbar" 5 "reserviert_keine_Anzeige" 6 "reserviert_keine_Anzeige" 7 "reserviert_keine_Anzeige";
